[part 12 of 23: package /Cluster]
AUTOSAR XML (schema 4-3-0)
package /Cluster  (continued)
  7 x lin cluster, all with baudrate=19200, protocol-name=LIN, protocol-version=2.0:  (continued)
    Klima_LIN4
      lin physical channel CHNL: comm-connectors=CN_Klima_LIN4
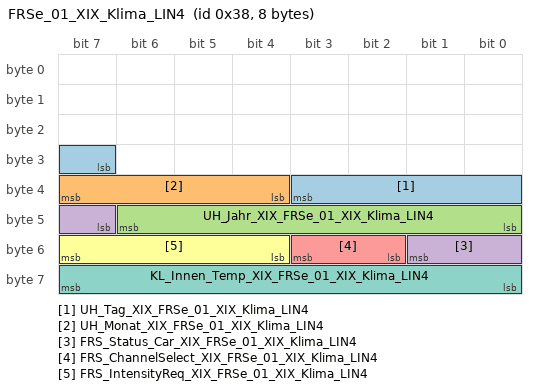
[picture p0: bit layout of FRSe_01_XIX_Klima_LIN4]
        frame FRSe_01_XIX_Klima_LIN4: id 0x38, from Klima, frame-length=8, lin-checksum=ENHANCED
          pdu FRSe_01_XIX_Klima_LIN4: length=8, unused-bit-pattern=0
            signal UH_Tag_XIX_FRSe_01_XIX_Klima_LIN4: start 31, 5 bit, little-endian, data-type-policy=OVERRIDE, i-signal-type=PRIMITIVE, init-value=0, base-type=BT_UH_Tag, compu {0=Cx0_Init (CM_UH_Tag_Cx0_Init), phys=raw for raw 1..31; unit Unit_Day}, range phys 1..31 Unit_Day, raw 0..31, unit=Unit_Day, transfer-property=PENDING  # 0x0: reserviert bei VW
            signal UH_Monat_XIX_FRSe_01_XIX_Klima_LIN4: start 36, 4 bit, little-endian, data-type-policy=OVERRIDE, i-signal-type=PRIMITIVE, init-value=0, base-type=BT_UH_Monat, invalid-value=Invalid_UH_Monat_XIX_FRSe_01_XIX_Klima_LIN4:15, compu {0=Cx0_Init (CM_UH_Monat_Cx0_Init), phys=raw for raw 1..12, 14=Cxe_Relatives_Datum (CM_UH_Monat_Cxe_Relatives_Datum), 15=Cxf_Fehler (CM_UH_Monat_Cxf_Fehler); unit Unit_Month}, range phys 1..12 Unit_Month, raw 0..15, unit=Unit_Month, transfer-property=PENDING  # 0x0D, 0xF = Werte ungültig 0x0E = Relatives Datum (nur VW)
            signal UH_Jahr_XIX_FRSe_01_XIX_Klima_LIN4: start 40, 7 bit, little-endian, data-type-policy=OVERRIDE, i-signal-type=PRIMITIVE, init-value=0, base-type=BT_UH_Jahr, compu {phys=raw+2000 for raw 0..127; unit Unit_Year}, range phys 2000..2127 Unit_Year, raw 0..127, unit=Unit_Year, transfer-property=PENDING
            signal FRS_Status_Car_XIX_FRSe_01_XIX_Klima_LIN4: start 47, 3 bit, little-endian, data-type-policy=OVERRIDE, i-signal-type=PRIMITIVE, init-value=0, base-type=BT_FRS_Status_Car, compu {0=Cx0_Kl15_off (CM_FRS_Status_Car_Cx0_Kl15_off), 1=Cx1_VoKo_active (CM_FRS_Status_Car_Cx1_VoKo_active), 2=Cx2_Kl15_on (CM_FRS_Status_Car_Cx2_Kl15_on)}, range raw 0..2, transfer-property=PENDING  # Status (Kl.15, VoKo)
            signal FRS_ChannelSelect_XIX_FRSe_01_XIX_Klima_LIN4: start 50, 2 bit, little-endian, data-type-policy=OVERRIDE, i-signal-type=PRIMITIVE, init-value=0, base-type=BT_FRS_ChannelSelect, compu {0=Cx0_Init (CM_FRS_ChannelSelect_Cx0_Init), 1=Cx1_container_1 (CM_FRS_ChannelSelect_Cx1_container_1), 2=Cx2_container_2 (CM_FRS_ChannelSelect_Cx2_container_2), 3=Cx3_container_3 (CM_FRS_ChannelSelect_Cx3_container_3)}, range raw 0..3, transfer-property=PENDING  # Fragrance channel select
            signal FRS_IntensityReq_XIX_FRSe_01_XIX_Klima_LIN4: start 52, 4 bit, little-endian, data-type-policy=OVERRIDE, i-signal-type=PRIMITIVE, init-value=14, base-type=BT_FRS_IntensityReq, invalid-value=Invalid_FRS_IntensityReq_XIX_FRSe_01_XIX_Klima_LIN4:15, compu {phys=raw*10 for raw 0..10, 14=Cxe_Init (CM_FRS_IntensityReq_Cxe_Init), 15=Cxf_Fehler (CM_FRS_IntensityReq_Cxf_Fehler); unit Unit_PerCent}, range phys 0..100 Unit_PerCent, raw 0..15, unit=Unit_PerCent, transfer-property=PENDING  # Fragrance Intensity Request (0=off, 10=max)
            signal KL_Innen_Temp_XIX_FRSe_01_XIX_Klima_LIN4: start 56, 8 bit, little-endian, data-type-policy=OVERRIDE, i-signal-type=PRIMITIVE, init-value=254, base-type=BT_KL_Innen_Temp, invalid-value=Invalid_KL_Innen_Temp_XIX_FRSe_01_XIX_Klima_LIN4:255, compu {phys=raw*0.5-50 for raw 0..252, 253=Cxfd_nicht_verbaut (CM_KL_Innen_Temp_Cxfd_nicht_verbaut), 254=Cxfe_nicht_verfuegbar (CM_KL_Innen_Temp_Cxfe_nicht_verfuegbar), 255=Cxff_Fehler (CM_KL_Innen_Temp_Cxff_Fehler); unit Unit_DegreCelsi}, range phys -50..76 Unit_DegreCelsi, raw 0..255, unit=Unit_DegreCelsi, transfer-property=PENDING  # Innentemperatur
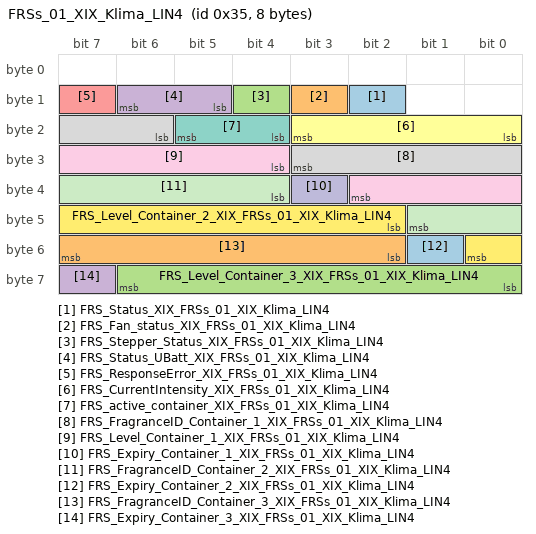
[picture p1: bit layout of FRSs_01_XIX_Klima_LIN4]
        frame FRSs_01_XIX_Klima_LIN4: id 0x35, to Klima, frame-length=8, lin-checksum=ENHANCED
          pdu FRSs_01_XIX_Klima_LIN4: length=8, unused-bit-pattern=0
            signal FRS_Status_XIX_FRSs_01_XIX_Klima_LIN4: start 10, 1 bit, little-endian, data-type-policy=OVERRIDE, i-signal-type=PRIMITIVE, init-value=0, base-type=BT_FRS_Status, compu {0=Cx0_no_error (CM_FRS_Status_Cx0_no_error), 1=Cx1_error (CM_FRS_Status_Cx1_error)}, range raw 0..1, transfer-property=PENDING, to Klima(timeout 3.5 s)  # internal error of fragrance system
            signal FRS_Fan_status_XIX_FRSs_01_XIX_Klima_LIN4: start 11, 1 bit, little-endian, data-type-policy=OVERRIDE, i-signal-type=PRIMITIVE, init-value=0, base-type=BT_FRS_Fan_status, compu {0=Cx0_no_error (CM_FRS_Fan_status_Cx0_no_error), 1=Cx1_error (CM_FRS_Fan_status_Cx1_error)}, range raw 0..1, transfer-property=PENDING, to Klima(timeout 3.5 s)  # Status of fragrance fan
            signal FRS_Stepper_Status_XIX_FRSs_01_XIX_Klima_LIN4: start 12, 1 bit, little-endian, data-type-policy=OVERRIDE, i-signal-type=PRIMITIVE, init-value=0, base-type=BT_FRS_Stepper_Status, compu {0=Cx0_no_error (CM_FRS_Stepper_Status_Cx0_no_error), 1=Cx1_error (CM_FRS_Stepper_Status_Cx1_error)}, range raw 0..1, transfer-property=PENDING, to Klima(timeout 3.5 s)  # Status of fragrance Stepper
            signal FRS_Status_UBatt_XIX_FRSs_01_XIX_Klima_LIN4: start 13, 2 bit, little-endian, data-type-policy=OVERRIDE, i-signal-type=PRIMITIVE, init-value=3, base-type=BT_FRS_Status_UBatt, compu {0=Cx0_voltage_OK (CM_FRS_Status_UBatt_Cx0_voltage_OK), 1=Cx1_undervoltage (CM_FRS_Status_UBatt_Cx1_undervoltage), 2=Cx2_overvoltage (CM_FRS_Status_UBatt_Cx2_overvoltage), 3=Cx3_init (CM_FRS_Status_UBatt_Cx3_init)}, range raw 0..3, transfer-property=PENDING, to Klima(timeout 3.5 s)  # Power supply status
            signal FRS_ResponseError_XIX_FRSs_01_XIX_Klima_LIN4: start 15, 1 bit, little-endian, data-type-policy=OVERRIDE, i-signal-type=PRIMITIVE, init-value=0, base-type=BT_FRS_ResponseError, invalid-value=Invalid_FRS_ResponseError_XIX_FRSs_01_XIX_Klima_LIN4:1, compu {0=Cx0_normal (CM_FRS_ResponseError_Cx0_normal), 1=Cx1_Fehler (CM_FRS_ResponseError_Cx1_Fehler)}, range raw 0..1, transfer-property=PENDING, to Klima(timeout 3.5 s)  # siehe LIN2.0-Specification (Darf nicht über ein Fehlergueltigkeitsbit abgesichtert werden!)
            signal FRS_CurrentIntensity_XIX_FRSs_01_XIX_Klima_LIN4: start 16, 4 bit, little-endian, data-type-policy=OVERRIDE, i-signal-type=PRIMITIVE, init-value=14, base-type=BT_FRS_CurrentIntensity, invalid-value=Invalid_FRS_CurrentIntensity_XIX_FRSs_01_XIX_Klima_LIN4:15, compu {phys=raw*10 for raw 0..10, 14=Cxe_Init (CM_FRS_CurrentIntensity_Cxe_Init), 15=Cxf_Fehler (CM_FRS_CurrentIntensity_Cxf_Fehler); unit Unit_PerCent}, range phys 0..100 Unit_PerCent, raw 0..15, unit=Unit_PerCent, transfer-property=PENDING, to Klima(timeout 3.5 s)  # Status of intensitry (0=off, 10=max)
            signal FRS_active_container_XIX_FRSs_01_XIX_Klima_LIN4: start 20, 2 bit, little-endian, data-type-policy=OVERRIDE, i-signal-type=PRIMITIVE, init-value=0, base-type=BT_FRS_active_container, compu {0=Cx0_init_none (CM_FRS_active_container_Cx0_init_none), 1=Cx1_container_1 (CM_FRS_active_container_Cx1_container_1), 2=Cx2_container_2 (CM_FRS_active_container_Cx2_container_2), 3=Cx3_container_3 (CM_FRS_active_container_Cx3_container_3)}, range raw 0..3, transfer-property=PENDING, to Klima(timeout 3.5 s)  # Current active container
            signal FRS_FragranceID_Container_1_XIX_FRSs_01_XIX_Klima_LIN4: start 22, 6 bit, little-endian, data-type-policy=OVERRIDE, i-signal-type=PRIMITIVE, init-value=0, base-type=BT_FRS_FragranceID_Container_1, compu {0=Cx0_not_installed (CM_FRS_FragranceID_Container_1_Cx0_not_installed), phys=raw for raw 1..60, 62=Cx3e_not_identified (CM_FRS_FragranceID_Container_1_Cx3e_not_identified), 63=Cx3f_custom_built (CM_FRS_FragranceID_Container_1_Cx3f_custom_built); unit Unit_None}, range phys 1..60 Unit_None, raw 0..63, unit=Unit_None, transfer-property=PENDING, to Klima(timeout 3.5 s)  # FragranceID in Container_1
            signal FRS_Level_Container_1_XIX_FRSs_01_XIX_Klima_LIN4: start 28, 7 bit, little-endian, data-type-policy=OVERRIDE, i-signal-type=PRIMITIVE, init-value=126, base-type=BT_FRS_Level_Container_1, compu {phys=raw for raw 0..100, 125=Cx7d_not_calculable (CM_FRS_Level_Container_1_Cx7d_not_calculable), 126=Cx7e_init (CM_FRS_Level_Container_1_Cx7e_init), 127=Cx7f_error (CM_FRS_Level_Container_1_Cx7f_error); unit Unit_PerCent}, range phys 0..100 Unit_PerCent, raw 0..127, unit=Unit_PerCent, transfer-property=PENDING, to Klima(timeout 3.5 s)  # Remaining level container 1
            signal FRS_Expiry_Container_1_XIX_FRSs_01_XIX_Klima_LIN4: start 35, 1 bit, little-endian, data-type-policy=OVERRIDE, i-signal-type=PRIMITIVE, init-value=0, base-type=BT_FRS_Expiry_Container_1, compu {0=Cx0_ok (CM_FRS_Expiry_Container_1_Cx0_ok), 1=Cx1_expiry_exceeded (CM_FRS_Expiry_Container_1_Cx1_expiry_exceeded)}, range raw 0..1, transfer-property=PENDING, to Klima(timeout 3.5 s)  # Expiry of Container 1
            signal FRS_FragranceID_Container_2_XIX_FRSs_01_XIX_Klima_LIN4: start 36, 6 bit, little-endian, data-type-policy=OVERRIDE, i-signal-type=PRIMITIVE, init-value=0, base-type=BT_FRS_FragranceID_Container_2, compu {0=Cx0_not_installed (CM_FRS_FragranceID_Container_2_Cx0_not_installed), phys=raw for raw 1..60, 62=Cx3e_not_identified (CM_FRS_FragranceID_Container_2_Cx3e_not_identified), 63=Cx3f_custom_built (CM_FRS_FragranceID_Container_2_Cx3f_custom_built); unit Unit_None}, range phys 1..60 Unit_None, raw 0..63, unit=Unit_None, transfer-property=PENDING, to Klima(timeout 3.5 s)  # FragranceID in Container_2
            signal FRS_Level_Container_2_XIX_FRSs_01_XIX_Klima_LIN4: start 42, 7 bit, little-endian, data-type-policy=OVERRIDE, i-signal-type=PRIMITIVE, init-value=126, base-type=BT_FRS_Level_Container_2, compu {phys=raw for raw 0..100, 125=Cx7d_not_calculable (CM_FRS_Level_Container_2_Cx7d_not_calculable), 126=Cx7e_init (CM_FRS_Level_Container_2_Cx7e_init), 127=Cx7f_error (CM_FRS_Level_Container_2_Cx7f_error); unit Unit_PerCent}, range phys 0..100 Unit_PerCent, raw 0..127, unit=Unit_PerCent, transfer-property=PENDING, to Klima(timeout 3.5 s)  # Remaining level container 2
            signal FRS_Expiry_Container_2_XIX_FRSs_01_XIX_Klima_LIN4: start 49, 1 bit, little-endian, data-type-policy=OVERRIDE, i-signal-type=PRIMITIVE, init-value=0, base-type=BT_FRS_Expiry_Container_2, compu {0=Cx0_ok (CM_FRS_Expiry_Container_2_Cx0_ok), 1=Cx1_expiry_exceeded (CM_FRS_Expiry_Container_2_Cx1_expiry_exceeded)}, range raw 0..1, transfer-property=PENDING, to Klima(timeout 3.5 s)  # Expiry of Container 2
            signal FRS_FragranceID_Container_3_XIX_FRSs_01_XIX_Klima_LIN4: start 50, 6 bit, little-endian, data-type-policy=OVERRIDE, i-signal-type=PRIMITIVE, init-value=0, base-type=BT_FRS_FragranceID_Container_3, compu {0=Cx0_not_installed (CM_FRS_FragranceID_Container_3_Cx0_not_installed), phys=raw for raw 1..60, 62=Cx3e_not_identified (CM_FRS_FragranceID_Container_3_Cx3e_not_identified), 63=Cx3f_custom_built (CM_FRS_FragranceID_Container_3_Cx3f_custom_built); unit Unit_None}, range phys 1..60 Unit_None, raw 0..63, unit=Unit_None, transfer-property=PENDING, to Klima(timeout 3.5 s)  # FragranceID in Container_3
            signal FRS_Level_Container_3_XIX_FRSs_01_XIX_Klima_LIN4: start 56, 7 bit, little-endian, data-type-policy=OVERRIDE, i-signal-type=PRIMITIVE, init-value=126, base-type=BT_FRS_Level_Container_3, compu {phys=raw for raw 0..100, 125=Cx7d_not_calculable (CM_FRS_Level_Container_3_Cx7d_not_calculable), 126=Cx7e_init (CM_FRS_Level_Container_3_Cx7e_init), 127=Cx7f_error (CM_FRS_Level_Container_3_Cx7f_error); unit Unit_PerCent}, range phys 0..100 Unit_PerCent, raw 0..127, unit=Unit_PerCent, transfer-property=PENDING, to Klima(timeout 3.5 s)  # Remaining level container 3
            signal FRS_Expiry_Container_3_XIX_FRSs_01_XIX_Klima_LIN4: start 63, 1 bit, little-endian, data-type-policy=OVERRIDE, i-signal-type=PRIMITIVE, init-value=0, base-type=BT_FRS_Expiry_Container_3, compu {0=Cx0_ok (CM_FRS_Expiry_Container_3_Cx0_ok), 1=Cx1_expiry_exceeded (CM_FRS_Expiry_Container_3_Cx1_expiry_exceeded)}, range raw 0..1, transfer-property=PENDING, to Klima(timeout 3.5 s)  # Expiry of Container 3
        frame HV_Hbe_01_XIX_Klima_LIN4: id 0x1C, from Klima, frame-length=4, lin-checksum=ENHANCED
          pdu HV_Hbe_01_XIX_Klima_LIN4: length=4, unused-bit-pattern=0
            signal KL_HV_Hb_soll_XIX_HV_Hbe_01_XIX_Klima_LIN4: start 0, 8 bit, little-endian, data-type-policy=OVERRIDE, i-signal-type=PRIMITIVE, init-value=254, base-type=BT_KL_HV_Hb_soll, invalid-value=Invalid_KL_HV_Hb_soll_XIX_HV_Hbe_01_XIX_Klima_LIN4:255, compu {phys=raw for raw 0..100, 254=Cxfe_Init (CM_KL_HV_Hb_soll_Cxfe_Init), 255=Cxff_Fehler (CM_KL_HV_Hb_soll_Cxff_Fehler); unit Unit_PerCent}, range phys 0..100 Unit_PerCent, raw 0..255, unit=Unit_PerCent, transfer-property=PENDING  # Calculated maximum HV-PTC Heater Power coming from Motor ECU
            signal KL_HV_Hb_ein_XIX_HV_Hbe_01_XIX_Klima_LIN4: start 8, 1 bit, little-endian, data-type-policy=OVERRIDE, i-signal-type=PRIMITIVE, init-value=0, base-type=BT_KL_HV_Hb_ein, compu {0=Cx0_Aus (CM_KL_HV_Hb_ein_Cx0_Aus), 1=Cx1_Ein (CM_KL_HV_Hb_ein_Cx1_Ein)}, range raw 0..1, transfer-property=PENDING  # PTC Aus/Ein
        frame HV_Hbs_01_XIX_Klima_LIN4: id 0x30, to Klima, frame-length=8, lin-checksum=ENHANCED  # HV-PTC
          pdu HV_Hbs_01_XIX_Klima_LIN4: length=8, unused-bit-pattern=0  # HV-PTC
            signal PTC_HVb_I_ist_XIX_HV_Hbs_01_XIX_Klima_LIN4: start 0, 8 bit, little-endian, data-type-policy=OVERRIDE, i-signal-type=PRIMITIVE, init-value=254, base-type=BT_PTC_HVb_I_ist, invalid-value=Invalid_PTC_HVb_I_ist_XIX_HV_Hbs_01_XIX_Klima_LIN4:255, compu {phys=raw*0.25 for raw 0..253, 254=Cxfe_Init (CM_PTC_HVb_I_ist_Cxfe_Init), 255=Cxff_Fehler (CM_PTC_HVb_I_ist_Cxff_Fehler); unit Unit_Amper}, range phys 0..63.25 Unit_Amper, raw 0..255, unit=Unit_Amper, transfer-property=PENDING, to Klima(timeout 3.5 s)  # PTC Stromverbrauch (max. 63,25A)
            signal PTC_HVb_ERR_XIX_HV_Hbs_01_XIX_Klima_LIN4: start 8, 2 bit, little-endian, data-type-policy=OVERRIDE, i-signal-type=PRIMITIVE, init-value=3, base-type=BT_PTC_HVb_ERR, compu {0=Cx0_No_Error (CM_PTC_HVb_ERR_Cx0_No_Error), 1=Cx1_High_Voltage_too_low (CM_PTC_HVb_ERR_Cx1_High_Voltage_too_low), 2=Cx2_High_Voltage_too_high (CM_PTC_HVb_ERR_Cx2_High_Voltage_too_high), 3=Cx3_Init (CM_PTC_HVb_ERR_Cx3_Init)}, range raw 0..3, transfer-property=PENDING, to Klima(timeout 3.5 s)
            signal PTC_HVb_Status_PTC_XIX_HV_Hbs_01_XIX_Klima_LIN4: start 16, 3 bit, little-endian, data-type-policy=OVERRIDE, i-signal-type=PRIMITIVE, init-value=7, base-type=BT_PTC_HVb_Status_PTC, compu {0=Cx0_PTC_OK (CM_PTC_HVb_Status_PTC_Cx0_PTC_OK), 1=Cx1_PTC_defekt (CM_PTC_HVb_Status_PTC_Cx1_PTC_defekt), 2=Cx2_PTC_error (CM_PTC_HVb_Status_PTC_Cx2_PTC_error), 3=Cx3_PTC_degraded_by_HW (CM_PTC_HVb_Status_PTC_Cx3_PTC_degraded_by_HW), 4=Cx4_PTC_degraded_by_SW (CM_PTC_HVb_Status_PTC_Cx4_PTC_degraded_by_SW), 5=Cx5_PTC_overheat_protection (CM_PTC_HVb_Status_PTC_Cx5_PTC_overheat_protection), 6=Cx6_not_defined (CM_PTC_HVb_Status_PTC_Cx6_not_defined), 7=Cx7_Init (CM_PTC_HVb_Status_PTC_Cx7_Init)}, range raw 0..7, transfer-property=PENDING, to Klima(timeout 3.5 s)  # Status der HV-PTC Heizeinheit
            signal PTC_HVb_Status_UBatt_XIX_HV_Hbs_01_XIX_Klima_LIN4: start 19, 2 bit, little-endian, data-type-policy=OVERRIDE, i-signal-type=PRIMITIVE, init-value=3, base-type=BT_PTC_HVb_Status_UBatt, compu {0=Cx0_Batterie_OK (CM_PTC_HVb_Status_UBatt_Cx0_Batterie_OK), 1=Cx1_Unterspannung (CM_PTC_HVb_Status_UBatt_Cx1_Unterspannung), 2=Cx2_Ueberspannung (CM_PTC_HVb_Status_UBatt_Cx2_Ueberspannung), 3=Cx3_Init (CM_PTC_HVb_Status_UBatt_Cx3_Init)}, range raw 0..3, transfer-property=PENDING, to Klima(timeout 3.5 s)  # Status der Batteriespannung
            signal PTC_HVb_ResponseError_XIX_HV_Hbs_01_XIX_Klima_LIN4: start 21, 1 bit, little-endian, data-type-policy=OVERRIDE, i-signal-type=PRIMITIVE, init-value=0, base-type=BT_PTC_HVb_ResponseError, invalid-value=Invalid_PTC_HVb_ResponseError_XIX_HV_Hbs_01_XIX_Klima_LIN4:1, compu {0=Cx0_normal (CM_PTC_HVb_ResponseError_Cx0_normal), 1=Cx1_Fehler (CM_PTC_HVb_ResponseError_Cx1_Fehler)}, range raw 0..1, transfer-property=PENDING, to Klima(timeout 3.5 s)  # siehe LIN2.0-Specification (Darf nicht über ein Fehlergueltigkeitsbit abgesichtert werden!)
            signal PTC_HVb_TimeOut_Fehler_XIX_HV_Hbs_01_XIX_Klima_LIN4: start 22, 1 bit, little-endian, data-type-policy=OVERRIDE, i-signal-type=PRIMITIVE, init-value=0, base-type=BT_PTC_HVb_TimeOut_Fehler, compu {0=Cx0_no_timeout (CM_PTC_HVb_TimeOut_Fehler_Cx0_no_timeout), 1=Cx1_timeout_detected (CM_PTC_HVb_TimeOut_Fehler_Cx1_timeout_detected)}, range raw 0..1, transfer-property=PENDING, to Klima(timeout 3.5 s)  # TPC hat zu lange keine Empfangsframes mehr erhalten (Dieser Fehler muss nicht über einen Fehlergueltigkeitsbit abgesichert werden).
            signal PTC_HVb_Err_Heizkreis_1_XIX_HV_Hbs_01_XIX_Klima_LIN4: start 24, 1 bit, little-endian, data-type-policy=OVERRIDE, i-signal-type=PRIMITIVE, init-value=0, base-type=BT_PTC_HVb_Err_Heizkreis_1, invalid-value=Invalid_PTC_HVb_Err_Heizkreis_1_XIX_HV_Hbs_01_XIX_Klima_LIN4:1, compu {0=Cx0_normal (CM_PTC_HVb_Err_Heizkreis_1_Cx0_normal), 1=Cx1_Fehler (CM_PTC_HVb_Err_Heizkreis_1_Cx1_Fehler)}, range raw 0..1, transfer-property=PENDING, to Klima(timeout 3.5 s)  # Bit wird gesetzt wenn Fehler in Heizkreis 1
            signal PTC_HVb_Err_Heizkreis_2_XIX_HV_Hbs_01_XIX_Klima_LIN4: start 25, 1 bit, little-endian, data-type-policy=OVERRIDE, i-signal-type=PRIMITIVE, init-value=0, base-type=BT_PTC_HVb_Err_Heizkreis_2, invalid-value=Invalid_PTC_HVb_Err_Heizkreis_2_XIX_HV_Hbs_01_XIX_Klima_LIN4:1, compu {0=Cx0_normal (CM_PTC_HVb_Err_Heizkreis_2_Cx0_normal), 1=Cx1_Fehler (CM_PTC_HVb_Err_Heizkreis_2_Cx1_Fehler)}, range raw 0..1, transfer-property=PENDING, to Klima(timeout 3.5 s)  # Bit wird gesetzt wenn Fehler in Heizkreis 2
            signal PTC_HVb_Err_Heizkreis_3_XIX_HV_Hbs_01_XIX_Klima_LIN4: start 26, 1 bit, little-endian, data-type-policy=OVERRIDE, i-signal-type=PRIMITIVE, init-value=0, base-type=BT_PTC_HVb_Err_Heizkreis_3, invalid-value=Invalid_PTC_HVb_Err_Heizkreis_3_XIX_HV_Hbs_01_XIX_Klima_LIN4:1, compu {0=Cx0_normal (CM_PTC_HVb_Err_Heizkreis_3_Cx0_normal), 1=Cx1_Fehler (CM_PTC_HVb_Err_Heizkreis_3_Cx1_Fehler)}, range raw 0..1, transfer-property=PENDING, to Klima(timeout 3.5 s)  # Bit wird gesetzt wenn Fehler in Heizkreis 3
            signal PTC_HVb_Err_Leckagestrom_XIX_HV_Hbs_01_XIX_Klima_LIN4: start 27, 1 bit, little-endian, data-type-policy=OVERRIDE, i-signal-type=PRIMITIVE, init-value=0, base-type=BT_PTC_HVb_Err_Leckagestrom, invalid-value=Invalid_PTC_HVb_Err_Leckagestrom_XIX_HV_Hbs_01_XIX_Klima_LIN4:1, compu {0=Cx0_normal (CM_PTC_HVb_Err_Leckagestrom_Cx0_normal), 1=Cx1_Fehler (CM_PTC_HVb_Err_Leckagestrom_Cx1_Fehler)}, range raw 0..1, transfer-property=PENDING, to Klima(timeout 3.5 s)  # Bit wird gesetzt, wenn Strom fließt obwohl kein Heizkreis angesteuert wird ( IGBT Fehler)
            signal PTC_HVb_Err_Ueberstromabschaltung_XIX_HV_Hbs_01_XIX_Klima_LIN4: start 28, 1 bit, little-endian, data-type-policy=OVERRIDE, i-signal-type=PRIMITIVE, init-value=0, base-type=BT_PTC_HVb_Err_Ueberstromabschaltung, compu {0=Cx0_inaktiv (CM_PTC_HVb_Err_Ueberstromabschaltung_Cx0_inaktiv), 1=Cx1_aktiv (CM_PTC_HVb_Err_Ueberstromabschaltung_Cx1_aktiv)}, range raw 0..1, transfer-property=PENDING, to Klima(timeout 3.5 s)  # Bit wird gesetzt, wenn über längeren Zeitraum ein zu hoher Gesamtstrom fließt (I Heizkreise > definierte Gesamtstromaufnahme)
            signal PTC_HVb_Err_Temperaturschutz_XIX_HV_Hbs_01_XIX_Klima_LIN4: start 29, 1 bit, little-endian, data-type-policy=OVERRIDE, i-signal-type=PRIMITIVE, init-value=0, base-type=BT_PTC_HVb_Err_Temperaturschutz, compu {0=Cx0_inaktiv (CM_PTC_HVb_Err_Temperaturschutz_Cx0_inaktiv), 1=Cx1_aktiv (CM_PTC_HVb_Err_Temperaturschutz_Cx1_aktiv)}, range raw 0..1, transfer-property=PENDING, to Klima(timeout 3.5 s)  # Bit wird gesetzt wenn die PlatinenTemperatur ihren Abschaltwert erreicht, Rücknahme bei erreichen der Einschalttemperaturschwelle
            signal PTC_HVb_Err_intern_XIX_HV_Hbs_01_XIX_Klima_LIN4: start 30, 1 bit, little-endian, data-type-policy=OVERRIDE, i-signal-type=PRIMITIVE, init-value=0, base-type=BT_PTC_HVb_Err_intern, invalid-value=Invalid_PTC_HVb_Err_intern_XIX_HV_Hbs_01_XIX_Klima_LIN4:1, compu {0=Cx0_normal (CM_PTC_HVb_Err_intern_Cx0_normal), 1=Cx1_Fehler (CM_PTC_HVb_Err_intern_Cx1_Fehler)}, range raw 0..1, transfer-property=PENDING, to Klima(timeout 3.5 s)  # Bit soll gesetzt werden, bei allen anderen internen Fehlern, welche denkbar sind (z.B. CPU- oder EEPROM Error; AD_Wandler defekt etc.)
            signal PTC_HVb_UBatt_XIX_HV_Hbs_01_XIX_Klima_LIN4: start 32, 8 bit, little-endian, data-type-policy=OVERRIDE, i-signal-type=PRIMITIVE, init-value=254, base-type=BT_PTC_HVb_UBatt, invalid-value=Invalid_PTC_HVb_UBatt_XIX_HV_Hbs_01_XIX_Klima_LIN4:255, compu {phys=raw*0.1 for raw 0..253, 254=Cxfe_Init (CM_PTC_HVb_UBatt_Cxfe_Init), 255=Cxff_Fehler (CM_PTC_HVb_UBatt_Cxff_Fehler); unit Unit_Volt}, range phys 0..25.3 Unit_Volt, raw 0..255, unit=Unit_Volt, transfer-property=PENDING, to Klima(timeout 3.5 s)  # Gemessene Batteriespannung
            signal PTC_HVb_Temp_PCB_XIX_HV_Hbs_01_XIX_Klima_LIN4: start 40, 8 bit, little-endian, data-type-policy=OVERRIDE, i-signal-type=PRIMITIVE, init-value=254, base-type=BT_PTC_HVb_Temp_PCB, invalid-value=Invalid_PTC_HVb_Temp_PCB_XIX_HV_Hbs_01_XIX_Klima_LIN4:255, compu {phys=raw-50 for raw 0..200, 254=Cxfe_Init (CM_PTC_HVb_Temp_PCB_Cxfe_Init), 255=Cxff_Fehler (CM_PTC_HVb_Temp_PCB_Cxff_Fehler); unit Unit_DegreCelsi}, range phys -50..150 Unit_DegreCelsi, raw 0..255, unit=Unit_DegreCelsi, transfer-property=PENDING, to Klima(timeout 3.5 s)  # Temperatur der PTC Ekektronik und der Platine (PCB)
            signal PTC_HVb_Heizmedium_Sensor_1_XIX_HV_Hbs_01_XIX_Klima_LIN4: start 48, 8 bit, little-endian, data-type-policy=OVERRIDE, i-signal-type=PRIMITIVE, init-value=254, base-type=BT_PTC_HVb_Heizmedium_Sensor_1, invalid-value=Invalid_PTC_HVb_Heizmedium_Sensor_1_XIX_HV_Hbs_01_XIX_Klima_LIN4:255, compu {phys=raw-50 for raw 0..220, 254=Cxfe_Init (CM_PTC_HVb_Heizmedium_Sensor_1_Cxfe_Init), 255=Cxff_Fehler (CM_PTC_HVb_Heizmedium_Sensor_1_Cxff_Fehler); unit Unit_DegreCelsi}, range phys -50..170 Unit_DegreCelsi, raw 0..255, unit=Unit_DegreCelsi, transfer-property=PENDING, to Klima(timeout 3.5 s)  # Gemessene Wassereinlasstemperatur
            signal PTC_HVb_Heizmedium_Sensor_2_XIX_HV_Hbs_01_XIX_Klima_LIN4: start 56, 8 bit, little-endian, data-type-policy=OVERRIDE, i-signal-type=PRIMITIVE, init-value=254, base-type=BT_PTC_HVb_Heizmedium_Sensor_2, invalid-value=Invalid_PTC_HVb_Heizmedium_Sensor_2_XIX_HV_Hbs_01_XIX_Klima_LIN4:255, compu {phys=raw-50 for raw 0..220, 254=Cxfe_Init (CM_PTC_HVb_Heizmedium_Sensor_2_Cxfe_Init), 255=Cxff_Fehler (CM_PTC_HVb_Heizmedium_Sensor_2_Cxff_Fehler); unit Unit_DegreCelsi}, range phys -50..170 Unit_DegreCelsi, raw 0..255, unit=Unit_DegreCelsi, transfer-property=PENDING, to Klima(timeout 3.5 s)  # Gemessene Wasserauslasstemperatur
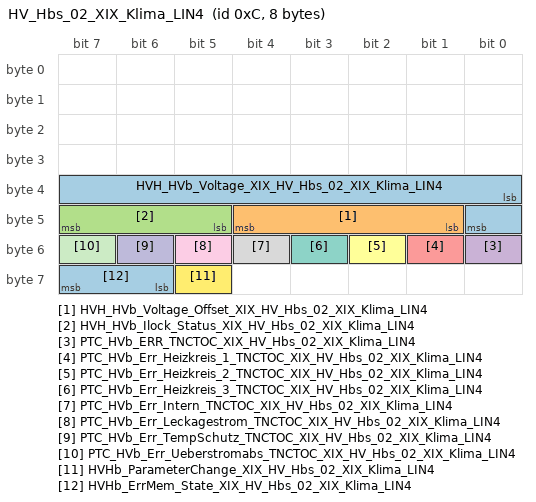
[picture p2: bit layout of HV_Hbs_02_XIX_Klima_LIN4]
        frame HV_Hbs_02_XIX_Klima_LIN4: id 0xC, to Klima, frame-length=8, lin-checksum=ENHANCED
          pdu HV_Hbs_02_XIX_Klima_LIN4: length=8, unused-bit-pattern=0
            signal HVH_HVb_Voltage_XIX_HV_Hbs_02_XIX_Klima_LIN4: start 32, 9 bit, little-endian, data-type-policy=OVERRIDE, i-signal-type=PRIMITIVE, init-value=510, base-type=BT_HVH_HVb_Voltage, invalid-value=Invalid_HVH_HVb_Voltage_XIX_HV_Hbs_02_XIX_Klima_LIN4:511, compu {phys=raw*4 for raw 0..509, 510=Cx1fe_Init (CM_HVH_HVb_Voltage_Cx1fe_Init), 511=Cx1ff_Fehler (CM_HVH_HVb_Voltage_Cx1ff_Fehler); unit Unit_Volt}, range phys 0..2036 Unit_Volt, raw 0..511, unit=Unit_Volt, transfer-property=PENDING, to Klima(timeout 3.5 s)  # Actual meassured High Voltage level of the HVH
            signal HVH_HVb_Voltage_Offset_XIX_HV_Hbs_02_XIX_Klima_LIN4: start 41, 4 bit, little-endian, data-type-policy=OVERRIDE, i-signal-type=PRIMITIVE, init-value=14, base-type=BT_HVH_HVb_Voltage_Offset, invalid-value=Invalid_HVH_HVb_Voltage_Offset_XIX_HV_Hbs_02_XIX_Klima_LIN4:15, compu {phys=raw*0.5 for raw 0..8, 14=Cxe_Init (CM_HVH_HVb_Voltage_Offset_Cxe_Init), 15=Cxf_Fehler (CM_HVH_HVb_Voltage_Offset_Cxf_Fehler); unit Unit_Volt}, range phys 0..4 Unit_Volt, raw 0..15, unit=Unit_Volt, transfer-property=PENDING, to Klima(timeout 3.5 s)  # Feinauflösung der HV-Spannung des HV-Heizers
            signal HVH_HVb_Ilock_Status_XIX_HV_Hbs_02_XIX_Klima_LIN4: start 45, 3 bit, little-endian, data-type-policy=OVERRIDE, i-signal-type=PRIMITIVE, init-value=7, base-type=BT_HVH_HVb_Ilock_Status, invalid-value=Invalid_HVH_HVb_Ilock_Status_XIX_HV_Hbs_02_XIX_Klima_LIN4:2, compu {0=Cx0_Connected (CM_HVH_HVb_Ilock_Status_Cx0_Connected), 1=Cx1_Disconnected (CM_HVH_HVb_Ilock_Status_Cx1_Disconnected), 2=Cx2_Fehler (CM_HVH_HVb_Ilock_Status_Cx2_Fehler), 3=Cx3_unused (CM_HVH_HVb_Ilock_Status_Cx3_unused), 4=Cx4_unused (CM_HVH_HVb_Ilock_Status_Cx4_unused), 5=Cx5_unused (CM_HVH_HVb_Ilock_Status_Cx5_unused), 6=Cx6_unused (CM_HVH_HVb_Ilock_Status_Cx6_unused), 7=Cx7_Init (CM_HVH_HVb_Ilock_Status_Cx7_Init)}, range raw 0..7, transfer-property=PENDING, to Klima(timeout 3.5 s)  # Status HV-Interlock
            signal PTC_HVb_ERR_TNCTOC_XIX_HV_Hbs_02_XIX_Klima_LIN4: start 48, 1 bit, little-endian, data-type-policy=OVERRIDE, i-signal-type=PRIMITIVE, init-value=1, base-type=BT_PTC_HVb_ERR_TNCTOC, compu {0=Cx0_testcompletedthisoperationcycle (CM_PTC_HVb_ERR_TNCTOC_Cx0_testcompletedthisoperationcycle), 1=Cx1_testnotcompleted (CM_PTC_HVb_ERR_TNCTOC_Cx1_testnotcompleted)}, range raw 0..1, transfer-property=PENDING, to Klima(timeout 3.5 s)  # Vorhalt OBD-Signal zu PTC_HV_ERR
            signal PTC_HVb_Err_Heizkreis_1_TNCTOC_XIX_HV_Hbs_02_XIX_Klima_LIN4: start 49, 1 bit, little-endian, data-type-policy=OVERRIDE, i-signal-type=PRIMITIVE, init-value=1, base-type=BT_PTC_HVb_Err_Heizkreis_1_TNCTOC, compu {0=Cx0_TestDurchlaufen (CM_PTC_HVb_Err_Heizkreis_1_TNCTOC_Cx0_TestDurchlaufen), 1=Cx1_TestNichtDurchlaufen (CM_PTC_HVb_Err_Heizkreis_1_TNCTOC_Cx1_TestNichtDurchlaufen)}, range raw 0..1, transfer-property=PENDING, to Klima(timeout 3.5 s)  # TNCTOC: test not completed this operation cycle
            signal PTC_HVb_Err_Heizkreis_2_TNCTOC_XIX_HV_Hbs_02_XIX_Klima_LIN4: start 50, 1 bit, little-endian, data-type-policy=OVERRIDE, i-signal-type=PRIMITIVE, init-value=1, base-type=BT_PTC_HVb_Err_Heizkreis_2_TNCTOC, compu {0=Cx0_TestDurchlaufen (CM_PTC_HVb_Err_Heizkreis_2_TNCTOC_Cx0_TestDurchlaufen), 1=Cx1_TestNichtDurchlaufen (CM_PTC_HVb_Err_Heizkreis_2_TNCTOC_Cx1_TestNichtDurchlaufen)}, range raw 0..1, transfer-property=PENDING, to Klima(timeout 3.5 s)  # TNCTOC: test not completed this operation cycle
            signal PTC_HVb_Err_Heizkreis_3_TNCTOC_XIX_HV_Hbs_02_XIX_Klima_LIN4: start 51, 1 bit, little-endian, data-type-policy=OVERRIDE, i-signal-type=PRIMITIVE, init-value=1, base-type=BT_PTC_HVb_Err_Heizkreis_3_TNCTOC, compu {0=Cx0_TestDurchlaufen (CM_PTC_HVb_Err_Heizkreis_3_TNCTOC_Cx0_TestDurchlaufen), 1=Cx1_TestNichtDurchlaufen (CM_PTC_HVb_Err_Heizkreis_3_TNCTOC_Cx1_TestNichtDurchlaufen)}, range raw 0..1, transfer-property=PENDING, to Klima(timeout 3.5 s)  # TNCTOC: test not completed this operation cycle
            signal PTC_HVb_Err_Intern_TNCTOC_XIX_HV_Hbs_02_XIX_Klima_LIN4: start 52, 1 bit, little-endian, data-type-policy=OVERRIDE, i-signal-type=PRIMITIVE, init-value=1, base-type=BT_PTC_HVb_Err_Intern_TNCTOC, compu {0=Cx0_TestDurchlaufen (CM_PTC_HVb_Err_Intern_TNCTOC_Cx0_TestDurchlaufen), 1=Cx1_TestNichtDurchlaufen (CM_PTC_HVb_Err_Intern_TNCTOC_Cx1_TestNichtDurchlaufen)}, range raw 0..1, transfer-property=PENDING, to Klima(timeout 3.5 s)  # TNCTOC: test not completed this operation cycle
            signal PTC_HVb_Err_Leckagestrom_TNCTOC_XIX_HV_Hbs_02_XIX_Klima_LIN4: start 53, 1 bit, little-endian, data-type-policy=OVERRIDE, i-signal-type=PRIMITIVE, init-value=1, base-type=BT_PTC_HVb_Err_Leckagestrom_TNCTOC, compu {0=Cx0_TestDurchlaufen (CM_PTC_HVb_Err_Leckagestrom_TNCTOC_Cx0_TestDurchlaufen), 1=Cx1_TestNichtDurchlaufen (CM_PTC_HVb_Err_Leckagestrom_TNCTOC_Cx1_TestNichtDurchlaufen)}, range raw 0..1, transfer-property=PENDING, to Klima(timeout 3.5 s)  # TNCTOC: test not completed this operation cycle
            signal PTC_HVb_Err_TempSchutz_TNCTOC_XIX_HV_Hbs_02_XIX_Klima_LIN4: start 54, 1 bit, little-endian, data-type-policy=OVERRIDE, i-signal-type=PRIMITIVE, init-value=1, base-type=BT_PTC_HVb_Err_TempSchutz_TNCTOC, compu {0=Cx0_TestDurchlaufen (CM_PTC_HVb_Err_TempSchutz_TNCTOC_Cx0_TestDurchlaufen), 1=Cx1_TestNichtDurchlaufen (CM_PTC_HVb_Err_TempSchutz_TNCTOC_Cx1_TestNichtDurchlaufen)}, range raw 0..1, transfer-property=PENDING, to Klima(timeout 3.5 s)  # TNCTOC: test not completed this operation cycle
            signal PTC_HVb_Err_Ueberstromabs_TNCTOC_XIX_HV_Hbs_02_XIX_Klima_LIN4: start 55, 1 bit, little-endian, data-type-policy=OVERRIDE, i-signal-type=PRIMITIVE, init-value=1, base-type=BT_PTC_HVb_Err_Ueberstromabs_TNCTOC, compu {0=Cx0_TestDurchlaufen (CM_PTC_HVb_Err_Ueberstromabs_TNCTOC_Cx0_TestDurchlaufen), 1=Cx1_TestNichtDurchlaufen (CM_PTC_HVb_Err_Ueberstromabs_TNCTOC_Cx1_TestNichtDurchlaufen)}, range raw 0..1, transfer-property=PENDING, to Klima(timeout 3.5 s)  # TNCTOC: test not completed this operation cycle
            signal HVHb_ParameterChange_XIX_HV_Hbs_02_XIX_Klima_LIN4: start 61, 1 bit, little-endian, data-type-policy=OVERRIDE, i-signal-type=PRIMITIVE, init-value=0, base-type=BT_HVHb_ParameterChange, compu {0=Cx0_noParameterChange (CM_HVHb_ParameterChange_Cx0_noParameterChange), 1=Cx1_ParameterChange (CM_HVHb_ParameterChange_Cx1_ParameterChange)}, range raw 0..1, transfer-property=PENDING, to Klima(timeout 3.5 s)  # Im LIN Slave wurde ein Parameter geändert, der eine Neuberechnung der CALID/CVN nach sich zieht. Das Bit wird auf '0' gesetzt, wenn seitens des DK4 eine Abfrage der CALID/CVN angestoßen und das DK1/2-System diese vollständig versendet hat.
            signal HVHb_ErrMem_State_XIX_HV_Hbs_02_XIX_Klima_LIN4: start 62, 2 bit, little-endian, data-type-policy=OVERRIDE, i-signal-type=PRIMITIVE, init-value=0, base-type=BT_HVHb_ErrMem_State, compu {0=Cx0_Init (CM_HVHb_ErrMem_State_Cx0_Init), 1=Cx1_Normalbetrieb (CM_HVHb_ErrMem_State_Cx1_Normalbetrieb), 2=Cx2_WertNachEmpfangMode04Request (CM_HVHb_ErrMem_State_Cx2_WertNachEmpfangMode04Request), 3=Cx3_WertNachInitialisierung (CM_HVHb_ErrMem_State_Cx3_WertNachInitialisierung)}, range raw 0..3, transfer-property=PENDING, to Klima(timeout 3.5 s)  # ErrMem_Init_done: Wird nach erfolgreichem löschen im LIN Slave für die Teit t_InitDone gesetzt und bedeutet, dass initialisiert wurde und ErrMem wieder aktiv ist. Nach Zeit t_InitDone wird der Wert 'ErrMem_Active_State' zurückgesetzt.
        frame KLhe_01_XIX_Klima_LIN4: id 0x1, from Klima, frame-length=8, lin-checksum=ENHANCED
          pdu KLhe_01_XIX_Klima_LIN4: length=8, unused-bit-pattern=0
            signal KL_Anz_oben_hl_XIX_KLhe_01_XIX_Klima_LIN4: start 0, 1 bit, little-endian, data-type-policy=OVERRIDE, i-signal-type=PRIMITIVE, init-value=0, base-type=BT_KL_Anz_oben_hl, compu {0=Cx0_Aus (CM_KL_Anz_oben_hl_Cx0_Aus), 1=Cx1_Ein (CM_KL_Anz_oben_hl_Cx1_Ein)}, range raw 0..1, transfer-property=PENDING  # VW428
            signal KL_Anz_mitte_hl_XIX_KLhe_01_XIX_Klima_LIN4: start 1, 1 bit, little-endian, data-type-policy=OVERRIDE, i-signal-type=PRIMITIVE, init-value=0, base-type=BT_KL_Anz_mitte_hl, compu {0=Cx0_Aus (CM_KL_Anz_mitte_hl_Cx0_Aus), 1=Cx1_Ein (CM_KL_Anz_mitte_hl_Cx1_Ein)}, range raw 0..1, transfer-property=PENDING  # Rückmeldung "Luftverteilung Mannanströmer Heck"
            signal KL_Anz_unten_hl_XIX_KLhe_01_XIX_Klima_LIN4: start 2, 1 bit, little-endian, data-type-policy=OVERRIDE, i-signal-type=PRIMITIVE, init-value=0, base-type=BT_KL_Anz_unten_hl, compu {0=Cx0_Aus (CM_KL_Anz_unten_hl_Cx0_Aus), 1=Cx1_Ein (CM_KL_Anz_unten_hl_Cx1_Ein)}, range raw 0..1, transfer-property=PENDING  # Rückmeldung "Luftverteilung Fußraum Heck"
            signal KL_Anz_auto_hl_XIX_KLhe_01_XIX_Klima_LIN4: start 3, 1 bit, little-endian, data-type-policy=OVERRIDE, i-signal-type=PRIMITIVE, init-value=0, base-type=BT_KL_Anz_auto_hl, compu {0=Cx0_Aus (CM_KL_Anz_auto_hl_Cx0_Aus), 1=Cx1_Ein (CM_KL_Anz_auto_hl_Cx1_Ein)}, range raw 0..1, transfer-property=PENDING  # Rückmeldung "Auto Heck"
            signal KL_Anz_seite_hl_XIX_KLhe_01_XIX_Klima_LIN4: start 4, 1 bit, little-endian, data-type-policy=OVERRIDE, i-signal-type=PRIMITIVE, init-value=0, base-type=BT_KL_Anz_seite_hl, compu {0=Cx0_Aus (CM_KL_Anz_seite_hl_Cx0_Aus), 1=Cx1_Ein (CM_KL_Anz_seite_hl_Cx1_Ein)}, range raw 0..1, transfer-property=PENDING  # Rückmeldung "Luftverteilung Seitenscheibe Heck"
            signal KL_Anz_seite_defog_hl_XIX_KLhe_01_XIX_Klima_LIN4: start 5, 1 bit, little-endian, data-type-policy=OVERRIDE, i-signal-type=PRIMITIVE, init-value=0, base-type=BT_KL_Anz_seite_defog_hl, compu {0=Cx0_Aus (CM_KL_Anz_seite_defog_hl_Cx0_Aus), 1=Cx1_Ein (CM_KL_Anz_seite_defog_hl_Cx1_Ein)}, range raw 0..1, transfer-property=PENDING  # Rückmeldung "Seitenscheiben-Defog Heck"
            signal KL_KLh_aus_XIX_KLhe_01_XIX_Klima_LIN4: start 8, 1 bit, little-endian, data-type-policy=OVERRIDE, i-signal-type=PRIMITIVE, base-type=BT_KL_KLh_aus, compu {0=Cx0_HeckBT_EIN (CM_KL_KLh_aus_Cx0_HeckBT_EIN), 1=Cx1_HeckBT_AUS (CM_KL_KLh_aus_Cx1_HeckBT_AUS)}, range raw 0..1, transfer-property=PENDING  # Anforderung Heckbedienteil Aus
            signal KL_KLh_LastMode_XIX_KLhe_01_XIX_Klima_LIN4: start 9, 2 bit, little-endian, data-type-policy=OVERRIDE, i-signal-type=PRIMITIVE, base-type=BT_KL_KLh_LastMode, compu {0=Cx0_LastMode_nicht_speichern (CM_KL_KLh_LastMode_Cx0_LastMode_nicht_speichern) (LastMode nicht speichern), 1=Cx1_Speichern_zeitbegrenzt (CM_KL_KLh_LastMode_Cx1_Speichern_zeitbegrenzt) (Speichern (zeitbegrenzt)), 2=Cx2_Speichern (CM_KL_KLh_LastMode_Cx2_Speichern)}, range raw 0..2, transfer-property=PENDING  # Übermittlung an Sitzheizung Heck, ob LastMode zu speichern ist.
            signal KL_KLh_lock_XIX_KLhe_01_XIX_Klima_LIN4: start 11, 1 bit, little-endian, data-type-policy=OVERRIDE, i-signal-type=PRIMITIVE, base-type=BT_KL_KLh_lock, compu {0=Cx0_Bedienung_HeckBT_nicht_gesperrt (CM_KL_KLh_lock_Cx0_Bedienung_HeckBT_nicht_gesperrt) (Bedienung HeckBT nicht gesperrt), 1=Cx1_Bedienung_HeckBT_gesperrt (CM_KL_KLh_lock_Cx1_Bedienung_HeckBT_gesperrt) (Bedienung HeckBT gesperrt)}, range raw 0..1, transfer-property=PENDING  # Das KlimaBT (front) unterbindet die Bedienung der Klimafunktionen des HeckBT durch Fahrgast hintere Reihe.
            signal KL_StellgliedtestINV_Heck_XIX_KLhe_01_XIX_Klima_LIN4: start 12, 1 bit, little-endian, data-type-policy=OVERRIDE, i-signal-type=PRIMITIVE, init-value=1, base-type=BT_KL_StellgliedtestINV_Heck, compu {0=Cx0_aktiv (CM_KL_StellgliedtestINV_Heck_Cx0_aktiv), 1=Cx1_inaktiv (CM_KL_StellgliedtestINV_Heck_Cx1_inaktiv)}, range raw 0..1, transfer-property=PENDING  # KlimaBT sendet an HeckBT Info über Status Stellgliedtest bzgl. Komponenten Heck.
            signal KL_Sitzkennlinie_Heck_XIX_KLhe_01_XIX_Klima_LIN4: start 13, 3 bit, little-endian, data-type-policy=OVERRIDE, i-signal-type=PRIMITIVE, base-type=BT_KL_Sitzkennlinie_Heck, compu {phys=raw for raw 0..7; unit Unit_None}, range phys 0..7 Unit_None, raw 0..7, unit=Unit_None, transfer-property=PENDING  # Globaler fester Satz von Applikationskennlinien Sitzheizung in HeckBT, ausgewählt für Fahrzeugprojekt.
            signal KL_Anz_Temp_hl_XIX_KLhe_01_XIX_Klima_LIN4: start 16, 8 bit, little-endian, data-type-policy=OVERRIDE, i-signal-type=PRIMITIVE, init-value=254, base-type=BT_KL_Anz_Temp_hl, invalid-value=Invalid_KL_Anz_Temp_hl_XIX_KLhe_01_XIX_Klima_LIN4:255, compu {0=Cx0_Low (CM_KL_Anz_Temp_hl_Cx0_Low), phys=raw for raw 1..250, 251=Cxfb_Anzeige_ECO (CM_KL_Anz_Temp_hl_Cxfb_Anzeige_ECO), 252=Cxfc_High (CM_KL_Anz_Temp_hl_Cxfc_High), 253=Cxfd_Keine_TemperaturAnzeige (CM_KL_Anz_Temp_hl_Cxfd_Keine_TemperaturAnzeige), 254=Cxfe_Init (CM_KL_Anz_Temp_hl_Cxfe_Init), 255=Cxff_Fehler (CM_KL_Anz_Temp_hl_Cxff_Fehler); unit Unit_None}, range phys 1..250 Unit_None, raw 0..255, unit=Unit_None, transfer-property=PENDING  # Soll-Temperatur Heck. Interpretation Intervall [1, 250] ist abhängig von Signal "KL_Anz_Temp_Einheit": °C: Offset=-50, Step=0,5 F: Offset=-50, Step=1 TempStufen: Offset=0, Step=1 physikalischer Wertebereich auf [1, 250] begrenzt logischer Wert für "ECO" hinzugefügt
            signal KL_Anz_Geblaese_hl_XIX_KLhe_01_XIX_Klima_LIN4: start 24, 4 bit, little-endian, data-type-policy=OVERRIDE, i-signal-type=PRIMITIVE, init-value=14, base-type=BT_KL_Anz_Geblaese_hl, invalid-value=Invalid_KL_Anz_Geblaese_hl_XIX_KLhe_01_XIX_Klima_LIN4:15, compu {phys=raw for raw 0..12, 13=Cxd_Keine_GeblaeseAnzeige (CM_KL_Anz_Geblaese_hl_Cxd_Keine_GeblaeseAnzeige), 14=Cxe_Init (CM_KL_Anz_Geblaese_hl_Cxe_Init), 15=Cxf_Fehler (CM_KL_Anz_Geblaese_hl_Cxf_Fehler); unit Unit_None}, range phys 0..12 Unit_None, raw 0..15, unit=Unit_None, transfer-property=PENDING  # Gebläsebalken Heck
            signal KL_SIH_Anforderung_hl_XIX_KLhe_01_XIX_Klima_LIN4: start 32, 3 bit, little-endian, data-type-policy=OVERRIDE, i-signal-type=PRIMITIVE, base-type=BT_KL_SIH_Anforderung_hl, compu {0=Cx0_Stufe_0_angefordert (CM_KL_SIH_Anforderung_hl_Cx0_Stufe_0_angefordert) (Stufe_0 angefordert), 1=Cx1_Stufe_1_angefordert (CM_KL_SIH_Anforderung_hl_Cx1_Stufe_1_angefordert) (Stufe_1 angefordert), 2=Cx2_Stufe_2_angefordert (CM_KL_SIH_Anforderung_hl_Cx2_Stufe_2_angefordert) (Stufe_2 angefordert), 3=Cx3_Stufe_3_angefordert (CM_KL_SIH_Anforderung_hl_Cx3_Stufe_3_angefordert) (Stufe_3 angefordert), 4=Cx4_Stufe_4_angefordert (CM_KL_SIH_Anforderung_hl_Cx4_Stufe_4_angefordert) (Stufe_4 angefordert), 5=Cx5_Stufe_5_angefordert (CM_KL_SIH_Anforderung_hl_Cx5_Stufe_5_angefordert) (Stufe_5 angefordert), 6=Cx6_Stufe_6_angefordert (CM_KL_SIH_Anforderung_hl_Cx6_Stufe_6_angefordert) (Stufe_6 angefordert), 7=Cx7_Keine_Anforderung (CM_KL_SIH_Anforderung_hl_Cx7_Keine_Anforderung) (Keine Anforderung)}, range raw 0..7, transfer-property=PENDING  # Anforderung der Sitzheizung Heck linke Seite durch KlimaBT.
            signal KL_SIH_Anforderung_hr_XIX_KLhe_01_XIX_Klima_LIN4: start 35, 3 bit, little-endian, data-type-policy=OVERRIDE, i-signal-type=PRIMITIVE, base-type=BT_KL_SIH_Anforderung_hr, compu {0=Cx0_Stufe_0_angefordert (CM_KL_SIH_Anforderung_hr_Cx0_Stufe_0_angefordert) (Stufe_0 angefordert), 1=Cx1_Stufe_1_angefordert (CM_KL_SIH_Anforderung_hr_Cx1_Stufe_1_angefordert) (Stufe_1 angefordert), 2=Cx2_Stufe_2_angefordert (CM_KL_SIH_Anforderung_hr_Cx2_Stufe_2_angefordert) (Stufe_2 angefordert), 3=Cx3_Stufe_3_angefordert (CM_KL_SIH_Anforderung_hr_Cx3_Stufe_3_angefordert) (Stufe_3 angefordert), 4=Cx4_Stufe_4_angefordert (CM_KL_SIH_Anforderung_hr_Cx4_Stufe_4_angefordert) (Stufe_4 angefordert), 5=Cx5_Stufe_5_angefordert (CM_KL_SIH_Anforderung_hr_Cx5_Stufe_5_angefordert) (Stufe_5 angefordert), 6=Cx6_Stufe_6_angefordert (CM_KL_SIH_Anforderung_hr_Cx6_Stufe_6_angefordert) (Stufe_6 angefordert), 7=Cx7_Keine_Anforderung (CM_KL_SIH_Anforderung_hr_Cx7_Keine_Anforderung) (Keine Anforderung)}, range raw 0..7, transfer-property=PENDING  # Anforderung der Sitzheizung Heck rechte Seite durch KlimaBT.
            signal KL_Anz_Temp_Einheit_XIX_KLhe_01_XIX_Klima_LIN4: start 38, 2 bit, little-endian, data-type-policy=OVERRIDE, i-signal-type=PRIMITIVE, base-type=BT_KL_Anz_Temp_Einheit, compu {0=Cx0_Celsius (CM_KL_Anz_Temp_Einheit_Cx0_Celsius), 1=Cx1_Fahrenheit (CM_KL_Anz_Temp_Einheit_Cx1_Fahrenheit), 2=Cx2_TemperaturStufen (CM_KL_Anz_Temp_Einheit_Cx2_TemperaturStufen), 3=Cx3_reserviert (CM_KL_Anz_Temp_Einheit_Cx3_reserviert)}, range raw 0..3, transfer-property=PENDING  # Vorgabe zur Interpretation der Temperaturanzeuge Heck.
            signal KL_Anz_Temp_hr_XIX_KLhe_01_XIX_Klima_LIN4: start 40, 8 bit, little-endian, data-type-policy=OVERRIDE, i-signal-type=PRIMITIVE, init-value=254, base-type=BT_KL_Anz_Temp_hr, invalid-value=Invalid_KL_Anz_Temp_hr_XIX_KLhe_01_XIX_Klima_LIN4:255, compu {0=Cx0_Low (CM_KL_Anz_Temp_hr_Cx0_Low), phys=raw for raw 1..250, 251=Cxfb_Anzeige_ECO (CM_KL_Anz_Temp_hr_Cxfb_Anzeige_ECO), 252=Cxfc_High (CM_KL_Anz_Temp_hr_Cxfc_High), 253=Cxfd_Keine_TemperaturAnzeige (CM_KL_Anz_Temp_hr_Cxfd_Keine_TemperaturAnzeige), 254=Cxfe_Init (CM_KL_Anz_Temp_hr_Cxfe_Init), 255=Cxff_Fehler (CM_KL_Anz_Temp_hr_Cxff_Fehler); unit Unit_None}, range phys 1..250 Unit_None, raw 0..255, unit=Unit_None, transfer-property=PENDING  # Soll-Temperatur Heck (rechts). Interpretation Intervall [1, 250] ist abhängig von Signal "KL_Anz_Temp_Einheit": °C: Offset=-50, Step=0,5 F: Offset=-50, Step=1 TempStufen: Offset=0, Step=1 physikalischer Wertebereich auf [1, 250] begrenzt logischer Wert für "ECO" hinzugefügt
            signal KL_HBT_Geblaesestufe_anzeigen_XIX_KLhe_01_XIX_Klima_LIN4: start 48, 2 bit, little-endian, data-type-policy=OVERRIDE, i-signal-type=PRIMITIVE, init-value=1, base-type=BT_KL_HBT_Geblaesestufe_anzeigen, compu {0=Cx0_Geblaesestufe_anzeigen (CM_KL_HBT_Geblaesestufe_anzeigen_Cx0_Geblaesestufe_anzeigen), 1=Cx1_Geblaesestufe_ausblenden (CM_KL_HBT_Geblaesestufe_anzeigen_Cx1_Geblaesestufe_ausblenden), 2=Cx2_reserviert (CM_KL_HBT_Geblaesestufe_anzeigen_Cx2_reserviert), 3=Cx3_reserviert (CM_KL_HBT_Geblaesestufe_anzeigen_Cx3_reserviert)}, range raw 0..3, transfer-property=PENDING  # Wenn zwei Heckbedienteile (HBT) im Fahrzeug verbaut sind, wird über dieses Signal eine synchrone Anzeige der Gebläsestufe sichergestellt. Wird an einem HBT die Gebläsestufe verändert, wird über diesen Flag dem anderen HBT signalisiert, die aktuelle Gebläsestufe ebenfalls anzuzeigen.
            signal KL_HBT_Verbausituation_XIX_KLhe_01_XIX_Klima_LIN4: start 50, 2 bit, little-endian, data-type-policy=OVERRIDE, i-signal-type=PRIMITIVE, init-value=1, base-type=BT_KL_HBT_Verbausituation, compu {0=Cx0_Zwei_Heckbedienteile (CM_KL_HBT_Verbausituation_Cx0_Zwei_Heckbedienteile), 1=Cx1_Ein_Heckbedienteil (CM_KL_HBT_Verbausituation_Cx1_Ein_Heckbedienteil), 2=Cx2_reserviert (CM_KL_HBT_Verbausituation_Cx2_reserviert), 3=Cx3_reserviert (CM_KL_HBT_Verbausituation_Cx3_reserviert)}, range raw 0..3, transfer-property=PENDING  # Gibt die Verbausituation der Heckbedienteile (HBT) an. Im Fahrzeug können für die Bedienung der hinteren Klimazone auch mehrere HBTs verbaut sein. Für eine synchrone Anzeige der Geläbsestufe wird über dieses Signal die Verbausituation dauerhaft gesendet.
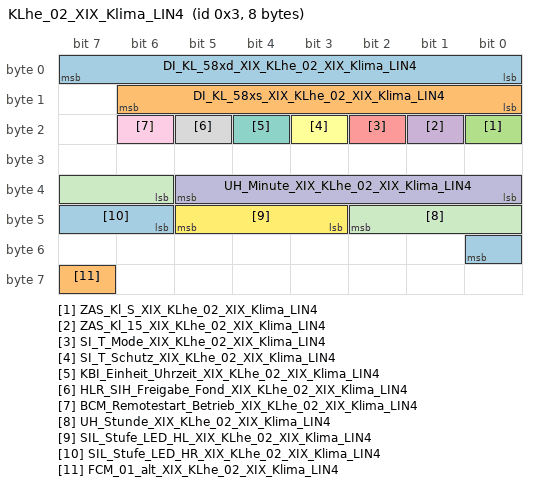
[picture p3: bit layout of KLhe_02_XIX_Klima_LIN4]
        frame KLhe_02_XIX_Klima_LIN4: id 0x3, from Klima, frame-length=8, lin-checksum=ENHANCED
          pdu KLhe_02_XIX_Klima_LIN4: length=8, unused-bit-pattern=0
            signal DI_KL_58xd_XIX_KLhe_02_XIX_Klima_LIN4: start 0, 8 bit, little-endian, data-type-policy=OVERRIDE, i-signal-type=PRIMITIVE, init-value=254, base-type=BT_DI_KL_58xd, invalid-value=Invalid_DI_KL_58xd_XIX_KLhe_02_XIX_Klima_LIN4:255, compu {phys=raw for raw 0..253, 254=Cxfe_Init (CM_DI_KL_58xd_Cxfe_Init), 255=Cxff_Fehler (CM_DI_KL_58xd_Cxff_Fehler)}, range phys 0..253, raw 0..255, transfer-property=PENDING  # Klemme 58xd Display- und Funktionsbeleuchtung Mit der Klemme 58xd wird die Helligkeit der Display- und der Funktionsbeleuchtungen der Schalter gesteuert. Im Detail beschrieben im 'Funktionslastenheft Dimmung MQB'.
            signal DI_KL_58xs_XIX_KLhe_02_XIX_Klima_LIN4: start 8, 7 bit, little-endian, data-type-policy=OVERRIDE, i-signal-type=PRIMITIVE, init-value=126, base-type=BT_DI_KL_58xs, invalid-value=Invalid_DI_KL_58xs_XIX_KLhe_02_XIX_Klima_LIN4:127, compu {phys=raw for raw 0..100, 126=Cx7e_Init (CM_DI_KL_58xs_Cx7e_Init), 127=Cx7f_Fehler (CM_DI_KL_58xs_Cx7f_Fehler); unit Unit_PerCent}, range phys 0..100 Unit_PerCent, raw 0..127, unit=Unit_PerCent, transfer-property=PENDING  # Suchbeleuchtung Schalter EIN-AUS-Schaltalgorithmus der allgemeinen Schaltersuchbeleuchtung. Im Detail beschrieben im 'Funktionslastenheft Dimmung MQB'.
            signal ZAS_Kl_S_XIX_KLhe_02_XIX_Klima_LIN4: start 16, 1 bit, little-endian, data-type-policy=OVERRIDE, i-signal-type=PRIMITIVE, init-value=0, base-type=BT_ZAS_Kl_S, compu {0=Cx0_aus (CM_ZAS_Kl_S_Cx0_aus), 1=Cx1_S_Kontakt_ein (CM_ZAS_Kl_S_Cx1_S_Kontakt_ein)}, range raw 0..1, transfer-property=PENDING  # Klemme S: S-Kontakt (Schluessel steckt)
            signal ZAS_Kl_15_XIX_KLhe_02_XIX_Klima_LIN4: start 17, 1 bit, little-endian, data-type-policy=OVERRIDE, i-signal-type=PRIMITIVE, init-value=0, base-type=BT_ZAS_Kl_15, compu {0=Cx0_aus (CM_ZAS_Kl_15_Cx0_aus), 1=Cx1_ein (CM_ZAS_Kl_15_Cx1_ein)}, range raw 0..1, transfer-property=PENDING  # Klemme 15: Zuendung (SW-Kl.15)
            signal SI_T_Mode_XIX_KLhe_02_XIX_Klima_LIN4: start 18, 1 bit, little-endian, data-type-policy=OVERRIDE, i-signal-type=PRIMITIVE, init-value=0, base-type=BT_SI_T_Mode, compu {0=Cx0_Transportmodus_nicht_aktiv (CM_SI_T_Mode_Cx0_Transportmodus_nicht_aktiv), 1=Cx1_Transportmodus_aktiv (CM_SI_T_Mode_Cx1_Transportmodus_aktiv)}, range raw 0..1, transfer-property=PENDING  # 0x0: Transportmodus nicht aktiv 0x1: Transportmodus aktiv
            signal SI_T_Schutz_XIX_KLhe_02_XIX_Klima_LIN4: start 19, 1 bit, little-endian, data-type-policy=OVERRIDE, i-signal-type=PRIMITIVE, init-value=0, base-type=BT_SI_T_Schutz, compu {0=Cx0_Transportschutz_nicht_aktiv (CM_SI_T_Schutz_Cx0_Transportschutz_nicht_aktiv), 1=Cx1_Transportschutz_aktiv (CM_SI_T_Schutz_Cx1_Transportschutz_aktiv)}, range raw 0..1, transfer-property=PENDING  # Transportschutz-Signal, das bei Transportmodus und Motorlauf aktiv bleibt 0x0: Transportschutz nicht aktiv 0x1: Transportschutz aktiv
            signal KBI_Einheit_Uhrzeit_XIX_KLhe_02_XIX_Klima_LIN4: start 20, 1 bit, little-endian, data-type-policy=OVERRIDE, i-signal-type=PRIMITIVE, init-value=0, base-type=BT_KBI_Einheit_Uhrzeit, compu {0=Cx0_24h (CM_KBI_Einheit_Uhrzeit_Cx0_24h), 1=Cx1_12h_AM_PM (CM_KBI_Einheit_Uhrzeit_Cx1_12h_AM_PM) (12h AM/PM)}, range raw 0..1, transfer-property=PENDING  # Anzeigevariante der Uhrzeit
            signal HLR_SIH_Freigabe_Fond_XIX_KLhe_02_XIX_Klima_LIN4: start 21, 1 bit, little-endian, data-type-policy=OVERRIDE, i-signal-type=PRIMITIVE, init-value=0, base-type=BT_HLR_SIH_Freigabe_Fond, compu {0=Cx0_keine_Freigabe (CM_HLR_SIH_Freigabe_Fond_Cx0_keine_Freigabe), 1=Cx1_Freigabe (CM_HLR_SIH_Freigabe_Fond_Cx1_Freigabe)}, range raw 0..1, transfer-property=PENDING  # Freigabe des EM für Sitzheizungen hinten
            signal BCM_Remotestart_Betrieb_XIX_KLhe_02_XIX_Klima_LIN4: start 22, 1 bit, little-endian, data-type-policy=OVERRIDE, i-signal-type=PRIMITIVE, init-value=0, base-type=BT_BCM_Remotestart_Betrieb, compu {0=Cx0_kein_RS_Betrieb (CM_BCM_Remotestart_Betrieb_Cx0_kein_RS_Betrieb), 1=Cx1_RS_Betrieb (CM_BCM_Remotestart_Betrieb_Cx1_RS_Betrieb)}, range raw 0..1, transfer-property=PENDING  # Zeigt den Status des RemoteStarts an, d.h. KL15_RSt ist aktiviert und der Motorlauf ist im RSt-Betrieb aktiv.
            signal UH_Minute_XIX_KLhe_02_XIX_Klima_LIN4: start 32, 6 bit, little-endian, data-type-policy=OVERRIDE, i-signal-type=PRIMITIVE, init-value=0, base-type=BT_UH_Minute, compu {phys=raw for raw 0..59; unit Unit_Minut}, range phys 0..59 Unit_Minut, raw 0..59, unit=Unit_Minut, transfer-property=PENDING  # 0x3C- 0x3f = Werte ungültig
            signal UH_Stunde_XIX_KLhe_02_XIX_Klima_LIN4: start 38, 5 bit, little-endian, data-type-policy=OVERRIDE, i-signal-type=PRIMITIVE, init-value=0, base-type=BT_UH_Stunde, compu {phys=raw for raw 0..23; unit Unit_Hours}, range phys 0..23 Unit_Hours, raw 0..23, unit=Unit_Hours, transfer-property=PENDING  # 0x18 - 0x1F = Werte ungültig
            signal SIL_Stufe_LED_HL_XIX_KLhe_02_XIX_Klima_LIN4: start 43, 3 bit, little-endian, data-type-policy=OVERRIDE, i-signal-type=PRIMITIVE, init-value=0, base-type=BT_SIL_Stufe_LED_HL, compu {0=Cx0_Aus (CM_SIL_Stufe_LED_HL_Cx0_Aus), 1=Cx1_Stufe_1 (CM_SIL_Stufe_LED_HL_Cx1_Stufe_1), 2=Cx2_Stufe_2 (CM_SIL_Stufe_LED_HL_Cx2_Stufe_2), 3=Cx3_Stufe_3 (CM_SIL_Stufe_LED_HL_Cx3_Stufe_3), 4=Cx4_Stufe_4 (CM_SIL_Stufe_LED_HL_Cx4_Stufe_4), 5=Cx5_Stufe_5 (CM_SIL_Stufe_LED_HL_Cx5_Stufe_5), 6=Cx6_Stufe_6 (CM_SIL_Stufe_LED_HL_Cx6_Stufe_6)}, range raw 0..6, transfer-property=PENDING  # Statusmeldung Sitzlüftung hinten links
            signal SIL_Stufe_LED_HR_XIX_KLhe_02_XIX_Klima_LIN4: start 46, 3 bit, little-endian, data-type-policy=OVERRIDE, i-signal-type=PRIMITIVE, init-value=0, base-type=BT_SIL_Stufe_LED_HR, compu {0=Cx0_Aus (CM_SIL_Stufe_LED_HR_Cx0_Aus), 1=Cx1_Stufe_1 (CM_SIL_Stufe_LED_HR_Cx1_Stufe_1), 2=Cx2_Stufe_2 (CM_SIL_Stufe_LED_HR_Cx2_Stufe_2), 3=Cx3_Stufe_3 (CM_SIL_Stufe_LED_HR_Cx3_Stufe_3), 4=Cx4_Stufe_4 (CM_SIL_Stufe_LED_HR_Cx4_Stufe_4), 5=Cx5_Stufe_5 (CM_SIL_Stufe_LED_HR_Cx5_Stufe_5), 6=Cx6_Stufe_6 (CM_SIL_Stufe_LED_HR_Cx6_Stufe_6)}, range raw 0..6, transfer-property=PENDING  # Statusmeldung Sitzlüftung hinten rechts
            signal FCM_01_alt_XIX_KLhe_02_XIX_Klima_LIN4: start 63, 1 bit, little-endian, data-type-policy=OVERRIDE, i-signal-type=PRIMITIVE, init-value=1, base-type=BT_FCM_01_alt, compu {0=Cx0_aktuell (CM_FCM_01_alt_Cx0_aktuell), 1=Cx1_veraltet (CM_FCM_01_alt_Cx1_veraltet)}, range raw 0..1, transfer-property=PENDING  # Veraltet Bit für die Botschaft FCM_01
        frame KLhs_01_XIX_Klima_LIN4: id 0x2, to Klima, frame-length=8, lin-checksum=ENHANCED
          pdu KLhs_01_XIX_Klima_LIN4: length=8, unused-bit-pattern=0
            signal KLh_Fehler1_XIX_KLhs_01_XIX_Klima_LIN4: start 0, 1 bit, little-endian, data-type-policy=OVERRIDE, i-signal-type=PRIMITIVE, init-value=0, base-type=BT_KLh_Fehler1, compu {0=Cx0_T5_Heck_normal (CM_KLh_Fehler1_Cx0_T5_Heck_normal) (T5 Heck normal), 1=Cx1_T5_Heck_Fehler (CM_KLh_Fehler1_Cx1_T5_Heck_Fehler) (T5 Heck Fehler)}, range raw 0..1, transfer-property=PENDING, to Klima(timeout 3.5 s)  # Heckbedienteil Fehler1
            signal KLh_Fehler2_XIX_KLhs_01_XIX_Klima_LIN4: start 1, 1 bit, little-endian, data-type-policy=OVERRIDE, i-signal-type=PRIMITIVE, init-value=0, base-type=BT_KLh_Fehler2, compu {0=Cx0_T5_Heck_normal (CM_KLh_Fehler2_Cx0_T5_Heck_normal) (T5 Heck normal), 1=Cx1_T5_Heck_Fehler (CM_KLh_Fehler2_Cx1_T5_Heck_Fehler) (T5 Heck Fehler)}, range raw 0..1, transfer-property=PENDING, to Klima(timeout 3.5 s)  # Heckbedienteil Fehler2
            signal KLh_Fehler3_XIX_KLhs_01_XIX_Klima_LIN4: start 2, 1 bit, little-endian, data-type-policy=OVERRIDE, i-signal-type=PRIMITIVE, init-value=0, base-type=BT_KLh_Fehler3, compu {0=Cx0_T5_Heck_normal (CM_KLh_Fehler3_Cx0_T5_Heck_normal) (T5 Heck normal), 1=Cx1_T5_Heck_Fehler (CM_KLh_Fehler3_Cx1_T5_Heck_Fehler) (T5 Heck Fehler)}, range raw 0..1, transfer-property=PENDING, to Klima(timeout 3.5 s)  # Heckbedienteil Fehler3
            signal KLh_Fehler4_XIX_KLhs_01_XIX_Klima_LIN4: start 3, 1 bit, little-endian, data-type-policy=OVERRIDE, i-signal-type=PRIMITIVE, init-value=0, base-type=BT_KLh_Fehler4, compu {0=Cx0_T5_Heck_normal (CM_KLh_Fehler4_Cx0_T5_Heck_normal) (T5 Heck normal), 1=Cx1_T5_Heck_Fehler (CM_KLh_Fehler4_Cx1_T5_Heck_Fehler) (T5 Heck Fehler)}, range raw 0..1, transfer-property=PENDING, to Klima(timeout 3.5 s)  # Heckbedienteil Fehler4
            signal KLh_Fehler5_XIX_KLhs_01_XIX_Klima_LIN4: start 4, 1 bit, little-endian, data-type-policy=OVERRIDE, i-signal-type=PRIMITIVE, init-value=0, base-type=BT_KLh_Fehler5, compu {0=Cx0_T5_Heck_normal (CM_KLh_Fehler5_Cx0_T5_Heck_normal) (T5 Heck normal), 1=Cx1_T5_Heck_Fehler (CM_KLh_Fehler5_Cx1_T5_Heck_Fehler) (T5 Heck Fehler)}, range raw 0..1, transfer-property=PENDING, to Klima(timeout 3.5 s)  # Heckbedienteil Fehler5
            signal KLh_Fehler6_XIX_KLhs_01_XIX_Klima_LIN4: start 5, 1 bit, little-endian, data-type-policy=OVERRIDE, i-signal-type=PRIMITIVE, init-value=0, base-type=BT_KLh_Fehler6, compu {0=Cx0_T5_Heck_normal (CM_KLh_Fehler6_Cx0_T5_Heck_normal) (T5 Heck normal), 1=Cx1_T5_Heck_Fehler (CM_KLh_Fehler6_Cx1_T5_Heck_Fehler) (T5 Heck Fehler)}, range raw 0..1, transfer-property=PENDING, to Klima(timeout 3.5 s)  # Heckbedienteil Fehler6
            signal KLh_Fehler7_XIX_KLhs_01_XIX_Klima_LIN4: start 6, 1 bit, little-endian, data-type-policy=OVERRIDE, i-signal-type=PRIMITIVE, init-value=0, base-type=BT_KLh_Fehler7, compu {0=Cx0_T5_Heck_normal (CM_KLh_Fehler7_Cx0_T5_Heck_normal) (T5 Heck normal), 1=Cx1_T5_Heck_Fehler (CM_KLh_Fehler7_Cx1_T5_Heck_Fehler) (T5 Heck Fehler)}, range raw 0..1, transfer-property=PENDING, to Klima(timeout 3.5 s)  # Heckbedienteil Fehler7
            signal KLh_Fehler8_XIX_KLhs_01_XIX_Klima_LIN4: start 7, 1 bit, little-endian, data-type-policy=OVERRIDE, i-signal-type=PRIMITIVE, init-value=0, base-type=BT_KLh_Fehler8, compu {0=Cx0_T5_Heck_normal (CM_KLh_Fehler8_Cx0_T5_Heck_normal) (T5 Heck normal), 1=Cx1_T5_Heck_Fehler (CM_KLh_Fehler8_Cx1_T5_Heck_Fehler) (T5 Heck Fehler)}, range raw 0..1, transfer-property=PENDING, to Klima(timeout 3.5 s)  # Heckbedienteil Fehler8
            signal KLhl_GeblaeseSoll_XIX_KLhs_01_XIX_Klima_LIN4: start 8, 4 bit, little-endian, data-type-policy=OVERRIDE, i-signal-type=PRIMITIVE, init-value=0, base-type=BT_KLhl_GeblaeseSoll, compu {0=Cx0_keine_Ticks (CM_KLhl_GeblaeseSoll_Cx0_keine_Ticks) (keine Ticks), 1=Cx1_1_Ticks (CM_KLhl_GeblaeseSoll_Cx1_1_Ticks) (+1 Ticks), 2=Cx2_2_Ticks (CM_KLhl_GeblaeseSoll_Cx2_2_Ticks) (+2 Ticks), 3=Cx3_3_Ticks (CM_KLhl_GeblaeseSoll_Cx3_3_Ticks) (+3 Ticks), 4=Cx4_4_Ticks (CM_KLhl_GeblaeseSoll_Cx4_4_Ticks) (+4 Ticks), 5=Cx5_5_Ticks (CM_KLhl_GeblaeseSoll_Cx5_5_Ticks) (+5 Ticks), 6=Cx6_6_Ticks (CM_KLhl_GeblaeseSoll_Cx6_6_Ticks) (+6 Ticks), 7=Cx7_7_Ticks (CM_KLhl_GeblaeseSoll_Cx7_7_Ticks) (+7 Ticks), 8=Cx8_Fehlerwert (CM_KLhl_GeblaeseSoll_Cx8_Fehlerwert), 9=Cx9_7_Ticks (CM_KLhl_GeblaeseSoll_Cx9_7_Ticks) (-7 Ticks), 10=Cxa_6_Ticks (CM_KLhl_GeblaeseSoll_Cxa_6_Ticks) (-6 Ticks), 11=Cxb_5_Ticks (CM_KLhl_GeblaeseSoll_Cxb_5_Ticks) (-5 Ticks), 12=Cxc_5_Ticks (CM_KLhl_GeblaeseSoll_Cxc_5_Ticks) (-5 Ticks), 13=Cxd_3_Ticks (CM_KLhl_GeblaeseSoll_Cxd_3_Ticks) (-3 Ticks), 14=Cxe_2_Ticks (CM_KLhl_GeblaeseSoll_Cxe_2_Ticks) (-2 Ticks), 15=Cxf_1_Ticks (CM_KLhl_GeblaeseSoll_Cxf_1_Ticks) (-1 Ticks)}, range raw 0..15, transfer-property=PENDING, to Klima(timeout 3.5 s)  # VW428
            signal KLhl_TempSoll_XIX_KLhs_01_XIX_Klima_LIN4: start 12, 4 bit, little-endian, data-type-policy=OVERRIDE, i-signal-type=PRIMITIVE, init-value=0, base-type=BT_KLhl_TempSoll, compu {0=Cx0_keine_Ticks (CM_KLhl_TempSoll_Cx0_keine_Ticks) (keine Ticks), 1=Cx1_1_Ticks (CM_KLhl_TempSoll_Cx1_1_Ticks) (+1 Ticks), 2=Cx2_2_Ticks (CM_KLhl_TempSoll_Cx2_2_Ticks) (+2 Ticks), 3=Cx3_3_Ticks (CM_KLhl_TempSoll_Cx3_3_Ticks) (+3 Ticks), 4=Cx4_4_Ticks (CM_KLhl_TempSoll_Cx4_4_Ticks) (+4 Ticks), 5=Cx5_5_Ticks (CM_KLhl_TempSoll_Cx5_5_Ticks) (+5 Ticks), 6=Cx6_6_Ticks (CM_KLhl_TempSoll_Cx6_6_Ticks) (+6 Ticks), 7=Cx7_7_Ticks (CM_KLhl_TempSoll_Cx7_7_Ticks) (+7 Ticks), 8=Cx8_Fehlerwert (CM_KLhl_TempSoll_Cx8_Fehlerwert), 9=Cx9_7_Ticks (CM_KLhl_TempSoll_Cx9_7_Ticks) (-7 Ticks), 10=Cxa_6_Ticks (CM_KLhl_TempSoll_Cxa_6_Ticks) (-6 Ticks), 11=Cxb_5_Ticks (CM_KLhl_TempSoll_Cxb_5_Ticks) (-5 Ticks), 12=Cxc_5_Ticks (CM_KLhl_TempSoll_Cxc_5_Ticks) (-5 Ticks), 13=Cxd_3_Ticks (CM_KLhl_TempSoll_Cxd_3_Ticks) (-3 Ticks), 14=Cxe_2_Ticks (CM_KLhl_TempSoll_Cxe_2_Ticks) (-2 Ticks), 15=Cxf_1_Ticks (CM_KLhl_TempSoll_Cxf_1_Ticks) (-1 Ticks)}, range raw 0..15, transfer-property=PENDING, to Klima(timeout 3.5 s)  # VW428
            signal KLhl_Luft_oben_XIX_KLhs_01_XIX_Klima_LIN4: start 16, 1 bit, little-endian, data-type-policy=OVERRIDE, i-signal-type=PRIMITIVE, init-value=0, base-type=BT_KLhl_Luft_oben, compu {0=Cx0_nicht_betaetigt (CM_KLhl_Luft_oben_Cx0_nicht_betaetigt), 1=Cx1_betaetigt (CM_KLhl_Luft_oben_Cx1_betaetigt)}, range raw 0..1, transfer-property=PENDING, to Klima(timeout 3.5 s)  # VW428
            signal KLhl_Luft_mitte_XIX_KLhs_01_XIX_Klima_LIN4: start 17, 1 bit, little-endian, data-type-policy=OVERRIDE, i-signal-type=PRIMITIVE, init-value=0, base-type=BT_KLhl_Luft_mitte, compu {0=Cx0_nicht_betaetigt (CM_KLhl_Luft_mitte_Cx0_nicht_betaetigt), 1=Cx1_betaetigt (CM_KLhl_Luft_mitte_Cx1_betaetigt)}, range raw 0..1, transfer-property=PENDING, to Klima(timeout 3.5 s)  # Tastendruck "Luftverteilung Mannanströmer Heck"
            signal KLhl_Luft_unten_XIX_KLhs_01_XIX_Klima_LIN4: start 18, 1 bit, little-endian, data-type-policy=OVERRIDE, i-signal-type=PRIMITIVE, init-value=0, base-type=BT_KLhl_Luft_unten, compu {0=Cx0_nicht_betaetigt (CM_KLhl_Luft_unten_Cx0_nicht_betaetigt), 1=Cx1_betaetigt (CM_KLhl_Luft_unten_Cx1_betaetigt)}, range raw 0..1, transfer-property=PENDING, to Klima(timeout 3.5 s)  # Tastendruck "Luftverteilung Fußraum Heck"
            signal KLhl_Luft_auto_XIX_KLhs_01_XIX_Klima_LIN4: start 19, 1 bit, little-endian, data-type-policy=OVERRIDE, i-signal-type=PRIMITIVE, init-value=0, base-type=BT_KLhl_Luft_auto, compu {0=Cx0_nicht_betaetigt (CM_KLhl_Luft_auto_Cx0_nicht_betaetigt), 1=Cx1_betaetigt (CM_KLhl_Luft_auto_Cx1_betaetigt)}, range raw 0..1, transfer-property=PENDING, to Klima(timeout 3.5 s)  # Tastendruck "Auto Heck"
            signal KLhl_Luft_seite_XIX_KLhs_01_XIX_Klima_LIN4: start 20, 1 bit, little-endian, data-type-policy=OVERRIDE, i-signal-type=PRIMITIVE, init-value=0, base-type=BT_KLhl_Luft_seite, compu {0=Cx0_nicht_betaetigt (CM_KLhl_Luft_seite_Cx0_nicht_betaetigt), 1=Cx1_betaetigt (CM_KLhl_Luft_seite_Cx1_betaetigt)}, range raw 0..1, transfer-property=PENDING, to Klima(timeout 3.5 s)  # Tastendruck "Luftverteilung Seitenscheibe Heck"
            signal KLh_Seite_defog_hl_XIX_KLhs_01_XIX_Klima_LIN4: start 21, 1 bit, little-endian, data-type-policy=OVERRIDE, i-signal-type=PRIMITIVE, init-value=0, base-type=BT_KLh_Seite_defog_hl, compu {0=Cx0_nicht_betaetigt (CM_KLh_Seite_defog_hl_Cx0_nicht_betaetigt), 1=Cx1_betaetigt (CM_KLh_Seite_defog_hl_Cx1_betaetigt)}, range raw 0..1, transfer-property=PENDING, to Klima(timeout 3.5 s)  # Tastendruck "defog Heck"
            signal KLh_aus_XIX_KLhs_01_XIX_Klima_LIN4: start 22, 1 bit, little-endian, data-type-policy=OVERRIDE, i-signal-type=PRIMITIVE, base-type=BT_KLh_aus, compu {0=Cx0_Ein (CM_KLh_aus_Cx0_Ein), 1=Cx1_Aus (CM_KLh_aus_Cx1_Aus)}, range raw 0..1, transfer-property=PENDING, to Klima(timeout 3.5 s)  # Zustand HeckBT ein/aus
            signal KLhl_ResponseError_XIX_KLhs_01_XIX_Klima_LIN4: start 23, 1 bit, little-endian, data-type-policy=OVERRIDE, i-signal-type=PRIMITIVE, init-value=0, base-type=BT_KLhl_ResponseError, invalid-value=Invalid_KLhl_ResponseError_XIX_KLhs_01_XIX_Klima_LIN4:1, compu {0=Cx0_normal (CM_KLhl_ResponseError_Cx0_normal), 1=Cx1_Fehler (CM_KLhl_ResponseError_Cx1_Fehler)}, range raw 0..1, transfer-property=PENDING, to Klima(timeout 3.5 s)  # siehe LIN2.0-Specification (Kap 2.7.3) (Darf nicht über ein Fehlergueltigkeitsbit abgesichtert werden!)
            signal KLh_Ausstattung_KlimaHeck_XIX_KLhs_01_XIX_Klima_LIN4: start 24, 3 bit, little-endian, data-type-policy=OVERRIDE, i-signal-type=PRIMITIVE, base-type=BT_KLh_Ausstattung_KlimaHeck, compu {0=Cx0_Heizung_elektrisch (CM_KLh_Ausstattung_KlimaHeck_Cx0_Heizung_elektrisch), 1=Cx1_Klimamanuell_elektrisch (CM_KLh_Ausstattung_KlimaHeck_Cx1_Klimamanuell_elektrisch), 2=Cx2_Climatic_1_Zone (CM_KLh_Ausstattung_KlimaHeck_Cx2_Climatic_1_Zone), 3=Cx3_Climatronic_1_Zone (CM_KLh_Ausstattung_KlimaHeck_Cx3_Climatronic_1_Zone), 4=Cx4_Climatronic_2_Zonen (CM_KLh_Ausstattung_KlimaHeck_Cx4_Climatronic_2_Zonen), 5=Cx5_reserviert (CM_KLh_Ausstattung_KlimaHeck_Cx5_reserviert), 6=Cx6_reserviert (CM_KLh_Ausstattung_KlimaHeck_Cx6_reserviert), 7=Cx7_reserviert (CM_KLh_Ausstattung_KlimaHeck_Cx7_reserviert)}, range raw 0..7, transfer-property=PENDING, to Klima(timeout 3.5 s)  # Austtattungsart der Klimabedienung Heckbedienteil
            signal KLhr_TempSoll_XIX_KLhs_01_XIX_Klima_LIN4: start 27, 4 bit, little-endian, data-type-policy=OVERRIDE, i-signal-type=PRIMITIVE, init-value=0, base-type=BT_KLhr_TempSoll, compu {0=Cx0_keine_Ticks (CM_KLhr_TempSoll_Cx0_keine_Ticks) (keine Ticks), 1=Cx1_1_Ticks (CM_KLhr_TempSoll_Cx1_1_Ticks) (+1 Ticks), 2=Cx2_2_Ticks (CM_KLhr_TempSoll_Cx2_2_Ticks) (+2 Ticks), 3=Cx3_3_Ticks (CM_KLhr_TempSoll_Cx3_3_Ticks) (+3 Ticks), 4=Cx4_4_Ticks (CM_KLhr_TempSoll_Cx4_4_Ticks) (+4 Ticks), 5=Cx5_5_Ticks (CM_KLhr_TempSoll_Cx5_5_Ticks) (+5 Ticks), 6=Cx6_6_Ticks (CM_KLhr_TempSoll_Cx6_6_Ticks) (+6 Ticks), 7=Cx7_7_Ticks (CM_KLhr_TempSoll_Cx7_7_Ticks) (+7 Ticks), 8=Cx8_Fehlerwert (CM_KLhr_TempSoll_Cx8_Fehlerwert), 9=Cx9_7_Ticks (CM_KLhr_TempSoll_Cx9_7_Ticks) (-7 Ticks), 10=Cxa_6_Ticks (CM_KLhr_TempSoll_Cxa_6_Ticks) (-6 Ticks), 11=Cxb_5_Ticks (CM_KLhr_TempSoll_Cxb_5_Ticks) (-5 Ticks), 12=Cxc_5_Ticks (CM_KLhr_TempSoll_Cxc_5_Ticks) (-5 Ticks), 13=Cxd_3_Ticks (CM_KLhr_TempSoll_Cxd_3_Ticks) (-3 Ticks), 14=Cxe_2_Ticks (CM_KLhr_TempSoll_Cxe_2_Ticks) (-2 Ticks), 15=Cxf_1_Ticks (CM_KLhr_TempSoll_Cxf_1_Ticks) (-1 Ticks)}, range raw 0..15, transfer-property=PENDING, to Klima(timeout 3.5 s)  # Verstellung Temperatur 4. Zone durch Bedienelement Heck
            signal KLh_toggle_LVT_XIX_KLhs_01_XIX_Klima_LIN4: start 32, 2 bit, little-endian, data-type-policy=OVERRIDE, i-signal-type=PRIMITIVE, init-value=0, base-type=BT_KLh_toggle_LVT, compu {0=Cx0_nicht_betaetigt (CM_KLh_toggle_LVT_Cx0_nicht_betaetigt), 1=Cx1_betaetigt (CM_KLh_toggle_LVT_Cx1_betaetigt), 2=Cx2_long_push (CM_KLh_toggle_LVT_Cx2_long_push), 3=Cx3_klemmt (CM_KLh_toggle_LVT_Cx3_klemmt)}, range raw 0..3, transfer-property=PENDING, to Klima(timeout 3.5 s)  # Tastendruck "Toggle"
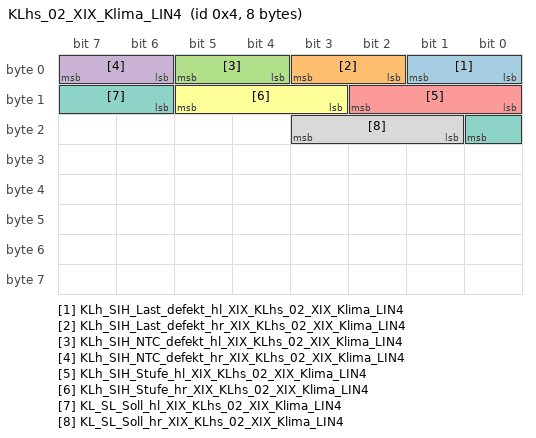
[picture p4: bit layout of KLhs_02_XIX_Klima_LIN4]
        frame KLhs_02_XIX_Klima_LIN4: id 0x4, to Klima, frame-length=8, lin-checksum=ENHANCED
          pdu KLhs_02_XIX_Klima_LIN4: length=8, unused-bit-pattern=0
            signal KLh_SIH_Last_defekt_hl_XIX_KLhs_02_XIX_Klima_LIN4: start 0, 2 bit, little-endian, data-type-policy=OVERRIDE, i-signal-type=PRIMITIVE, base-type=BT_KLh_SIH_Last_defekt_hl, compu {0=Cx0_Kein_Fehler_erkannt (CM_KLh_SIH_Last_defekt_hl_Cx0_Kein_Fehler_erkannt) (Kein Fehler erkannt), 1=Cx1_Unterbrechung (CM_KLh_SIH_Last_defekt_hl_Cx1_Unterbrechung), 2=Cx2_Kurzschluss_nach_Masse (CM_KLh_SIH_Last_defekt_hl_Cx2_Kurzschluss_nach_Masse) (Kurzschluss nach Masse)}, range raw 0..2, transfer-property=PENDING, to Klima(timeout 3.5 s)  # Diagnostizierung Sitzheizung Last Heck links.
            signal KLh_SIH_Last_defekt_hr_XIX_KLhs_02_XIX_Klima_LIN4: start 2, 2 bit, little-endian, data-type-policy=OVERRIDE, i-signal-type=PRIMITIVE, base-type=BT_KLh_SIH_Last_defekt_hr, compu {0=Cx0_Kein_Fehler_erkannt (CM_KLh_SIH_Last_defekt_hr_Cx0_Kein_Fehler_erkannt) (Kein Fehler erkannt), 1=Cx1_Unterbrechung (CM_KLh_SIH_Last_defekt_hr_Cx1_Unterbrechung), 2=Cx2_Kurzschluss_nach_Masse (CM_KLh_SIH_Last_defekt_hr_Cx2_Kurzschluss_nach_Masse) (Kurzschluss nach Masse)}, range raw 0..2, transfer-property=PENDING, to Klima(timeout 3.5 s)  # Diagnostizierung Sitzheizung Last Heck rechts.
            signal KLh_SIH_NTC_defekt_hl_XIX_KLhs_02_XIX_Klima_LIN4: start 4, 2 bit, little-endian, data-type-policy=OVERRIDE, i-signal-type=PRIMITIVE, base-type=BT_KLh_SIH_NTC_defekt_hl, compu {0=Cx0_Kein_Fehler_erkannt (CM_KLh_SIH_NTC_defekt_hl_Cx0_Kein_Fehler_erkannt) (Kein Fehler erkannt), 1=Cx1_Unterbrechung (CM_KLh_SIH_NTC_defekt_hl_Cx1_Unterbrechung), 2=Cx2_Kurzschluss_nach_Masse (CM_KLh_SIH_NTC_defekt_hl_Cx2_Kurzschluss_nach_Masse) (Kurzschluss nach Masse)}, range raw 0..2, transfer-property=PENDING, to Klima(timeout 3.5 s)  # Diagnostizierung Temperaturfühler Sitzheizung Heck links.
            signal KLh_SIH_NTC_defekt_hr_XIX_KLhs_02_XIX_Klima_LIN4: start 6, 2 bit, little-endian, data-type-policy=OVERRIDE, i-signal-type=PRIMITIVE, base-type=BT_KLh_SIH_NTC_defekt_hr, compu {0=Cx0_Kein_Fehler_erkannt (CM_KLh_SIH_NTC_defekt_hr_Cx0_Kein_Fehler_erkannt) (Kein Fehler erkannt), 1=Cx1_Unterbrechung (CM_KLh_SIH_NTC_defekt_hr_Cx1_Unterbrechung), 2=Cx2_Kurzschluss_nach_Masse (CM_KLh_SIH_NTC_defekt_hr_Cx2_Kurzschluss_nach_Masse) (Kurzschluss nach Masse)}, range raw 0..2, transfer-property=PENDING, to Klima(timeout 3.5 s)  # Diagnostizierung Temperaturfühler Sitzheizung Heck rechts.
            signal KLh_SIH_Stufe_hl_XIX_KLhs_02_XIX_Klima_LIN4: start 8, 3 bit, little-endian, data-type-policy=OVERRIDE, i-signal-type=PRIMITIVE, base-type=BT_KLh_SIH_Stufe_hl, compu {0=Cx0_Stufe_0 (CM_KLh_SIH_Stufe_hl_Cx0_Stufe_0), 1=Cx1_Stufe_1 (CM_KLh_SIH_Stufe_hl_Cx1_Stufe_1), 2=Cx2_Stufe_2 (CM_KLh_SIH_Stufe_hl_Cx2_Stufe_2), 3=Cx3_Stufe_3 (CM_KLh_SIH_Stufe_hl_Cx3_Stufe_3), 4=Cx4_Stufe_4 (CM_KLh_SIH_Stufe_hl_Cx4_Stufe_4), 5=Cx5_Stufe_5 (CM_KLh_SIH_Stufe_hl_Cx5_Stufe_5), 6=Cx6_Stufe_6 (CM_KLh_SIH_Stufe_hl_Cx6_Stufe_6)}, range raw 0..6, transfer-property=PENDING, to Klima(timeout 3.5 s)  # Aktive Stufe Sitzheizung Heck links, auf deren Basis die Sitzheizungsmatten bestromt werden. Bei dreistufigen Sitzheizungen wird Stufe 0/2/4/6 verwendet.
            signal KLh_SIH_Stufe_hr_XIX_KLhs_02_XIX_Klima_LIN4: start 11, 3 bit, little-endian, data-type-policy=OVERRIDE, i-signal-type=PRIMITIVE, base-type=BT_KLh_SIH_Stufe_hr, compu {0=Cx0_Stufe_0 (CM_KLh_SIH_Stufe_hr_Cx0_Stufe_0), 1=Cx1_Stufe_1 (CM_KLh_SIH_Stufe_hr_Cx1_Stufe_1), 2=Cx2_Stufe_2 (CM_KLh_SIH_Stufe_hr_Cx2_Stufe_2), 3=Cx3_Stufe_3 (CM_KLh_SIH_Stufe_hr_Cx3_Stufe_3), 4=Cx4_Stufe_4 (CM_KLh_SIH_Stufe_hr_Cx4_Stufe_4), 5=Cx5_Stufe_5 (CM_KLh_SIH_Stufe_hr_Cx5_Stufe_5), 6=Cx6_Stufe_6 (CM_KLh_SIH_Stufe_hr_Cx6_Stufe_6)}, range raw 0..6, transfer-property=PENDING, to Klima(timeout 3.5 s)  # Aktive Stufe Sitzheizung Heck rechts, auf deren Basis die Sitzheizungsmatten bestromt werden. Bei dreistufigen Sitzheizungen wird Stufe 0/2/4/6 verwendet.
            signal KL_SL_Soll_hl_XIX_KLhs_02_XIX_Klima_LIN4: start 14, 3 bit, little-endian, data-type-policy=OVERRIDE, i-signal-type=PRIMITIVE, init-value=0, base-type=BT_KL_SL_Soll_hl, compu {0=Cx0_Stufe_0 (CM_KL_SL_Soll_hl_Cx0_Stufe_0), 1=Cx1_Stufe_1 (CM_KL_SL_Soll_hl_Cx1_Stufe_1), 2=Cx2_Stufe_2 (CM_KL_SL_Soll_hl_Cx2_Stufe_2), 3=Cx3_Stufe_3 (CM_KL_SL_Soll_hl_Cx3_Stufe_3), 4=Cx4_Stufe_4 (CM_KL_SL_Soll_hl_Cx4_Stufe_4), 5=Cx5_Stufe_5 (CM_KL_SL_Soll_hl_Cx5_Stufe_5), 6=Cx6_Stufe_6 (CM_KL_SL_Soll_hl_Cx6_Stufe_6)}, range raw 0..6, transfer-property=PENDING, to Klima(timeout 3.5 s)  # Einstellung Sitzlüftung hinten links (0...6)
            signal KL_SL_Soll_hr_XIX_KLhs_02_XIX_Klima_LIN4: start 17, 3 bit, little-endian, data-type-policy=OVERRIDE, i-signal-type=PRIMITIVE, init-value=0, base-type=BT_KL_SL_Soll_hr, compu {0=Cx0_Stufe_0 (CM_KL_SL_Soll_hr_Cx0_Stufe_0), 1=Cx1_Stufe_1 (CM_KL_SL_Soll_hr_Cx1_Stufe_1), 2=Cx2_Stufe_2 (CM_KL_SL_Soll_hr_Cx2_Stufe_2), 3=Cx3_Stufe_3 (CM_KL_SL_Soll_hr_Cx3_Stufe_3), 4=Cx4_Stufe_4 (CM_KL_SL_Soll_hr_Cx4_Stufe_4), 5=Cx5_Stufe_5 (CM_KL_SL_Soll_hr_Cx5_Stufe_5), 6=Cx6_Stufe_6 (CM_KL_SL_Soll_hr_Cx6_Stufe_6)}, range raw 0..6, transfer-property=PENDING, to Klima(timeout 3.5 s)  # Einstellung Sitzlüftung hinten rechts (0...6)
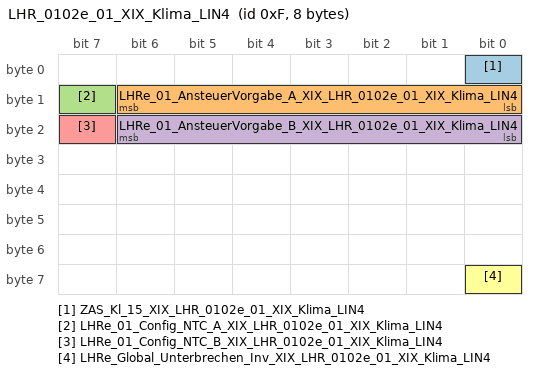
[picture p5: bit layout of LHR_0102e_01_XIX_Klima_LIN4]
        frame LHR_0102e_01_XIX_Klima_LIN4: id 0xF, from Klima, frame-length=8, lin-checksum=ENHANCED
          pdu LHR_0102e_01_XIX_Klima_LIN4: length=8, unused-bit-pattern=0
            signal ZAS_Kl_15_XIX_LHR_0102e_01_XIX_Klima_LIN4: start 0, 1 bit, little-endian, data-type-policy=OVERRIDE, i-signal-type=PRIMITIVE, init-value=0, base-type=BT_ZAS_Kl_15, compu {0=Cx0_aus (CM_ZAS_Kl_15_Cx0_aus), 1=Cx1_ein (CM_ZAS_Kl_15_Cx1_ein)}, range raw 0..1, transfer-property=PENDING  # Klemme 15: Zuendung (SW-Kl.15)
            signal LHRe_01_AnsteuerVorgabe_A_XIX_LHR_0102e_01_XIX_Klima_LIN4: start 8, 7 bit, little-endian, data-type-policy=OVERRIDE, i-signal-type=PRIMITIVE, init-value=0, base-type=BT_LHRe_01_AnsteuerVorgabe_A, invalid-value=Invalid_LHRe_01_AnsteuerVorgabe_A_XIX_LHR_0102e_01_XIX_Klima_LIN4:127, compu {phys=raw for raw 0..100, 101=Cx65_PWM_100Prozent_ohne_U_Kompensat (CM_LHRe_01_AnsteuerVorgabe_A_Cx65_PWM_100Prozent_ohne_U_Kompensat), 110=Cx6e_Stufe_0 (CM_LHRe_01_AnsteuerVorgabe_A_Cx6e_Stufe_0), 111=Cx6f_Stufe_1 (CM_LHRe_01_AnsteuerVorgabe_A_Cx6f_Stufe_1), 112=Cx70_Stufe_2 (CM_LHRe_01_AnsteuerVorgabe_A_Cx70_Stufe_2), 113=Cx71_Stufe_3 (CM_LHRe_01_AnsteuerVorgabe_A_Cx71_Stufe_3), 114=Cx72_Stufe_4 (CM_LHRe_01_AnsteuerVorgabe_A_Cx72_Stufe_4), 115=Cx73_Stufe_5 (CM_LHRe_01_AnsteuerVorgabe_A_Cx73_Stufe_5), 116=Cx74_Stufe_6 (CM_LHRe_01_AnsteuerVorgabe_A_Cx74_Stufe_6), 117=Cx75_Stufe_7 (CM_LHRe_01_AnsteuerVorgabe_A_Cx75_Stufe_7), 118=Cx76_Stufe_8 (CM_LHRe_01_AnsteuerVorgabe_A_Cx76_Stufe_8), 119=Cx77_Stufe_9 (CM_LHRe_01_AnsteuerVorgabe_A_Cx77_Stufe_9), 120=Cx78_Stufe_10 (CM_LHRe_01_AnsteuerVorgabe_A_Cx78_Stufe_10), 127=Cx7f_Fehler (CM_LHRe_01_AnsteuerVorgabe_A_Cx7f_Fehler); unit Unit_PerCent}, range phys 0..100 Unit_PerCent, raw 0..127, unit=Unit_PerCent, transfer-property=PENDING  # Heizvorgabe Kanal A
            signal LHRe_01_Config_NTC_A_XIX_LHR_0102e_01_XIX_Klima_LIN4: start 15, 1 bit, little-endian, data-type-policy=OVERRIDE, i-signal-type=PRIMITIVE, init-value=0, base-type=BT_LHRe_01_Config_NTC_A, compu {0=Cx0_Init_ohne_NTC (CM_LHRe_01_Config_NTC_A_Cx0_Init_ohne_NTC), 1=Cx1_mit_NTC (CM_LHRe_01_Config_NTC_A_Cx1_mit_NTC)}, range raw 0..1, transfer-property=PENDING  # Verbauinformation für NTC a
            signal LHRe_01_AnsteuerVorgabe_B_XIX_LHR_0102e_01_XIX_Klima_LIN4: start 16, 7 bit, little-endian, data-type-policy=OVERRIDE, i-signal-type=PRIMITIVE, init-value=0, base-type=BT_LHRe_01_AnsteuerVorgabe_B, invalid-value=Invalid_LHRe_01_AnsteuerVorgabe_B_XIX_LHR_0102e_01_XIX_Klima_LIN4:127, compu {phys=raw for raw 0..100, 101=Cx65_PWM_100Prozent_ohne_U_Kompensat (CM_LHRe_01_AnsteuerVorgabe_B_Cx65_PWM_100Prozent_ohne_U_Kompensat), 110=Cx6e_Stufe_0 (CM_LHRe_01_AnsteuerVorgabe_B_Cx6e_Stufe_0), 111=Cx6f_Stufe_1 (CM_LHRe_01_AnsteuerVorgabe_B_Cx6f_Stufe_1), 112=Cx70_Stufe_2 (CM_LHRe_01_AnsteuerVorgabe_B_Cx70_Stufe_2), 113=Cx71_Stufe_3 (CM_LHRe_01_AnsteuerVorgabe_B_Cx71_Stufe_3), 114=Cx72_Stufe_4 (CM_LHRe_01_AnsteuerVorgabe_B_Cx72_Stufe_4), 115=Cx73_Stufe_5 (CM_LHRe_01_AnsteuerVorgabe_B_Cx73_Stufe_5), 116=Cx74_Stufe_6 (CM_LHRe_01_AnsteuerVorgabe_B_Cx74_Stufe_6), 117=Cx75_Stufe_7 (CM_LHRe_01_AnsteuerVorgabe_B_Cx75_Stufe_7), 118=Cx76_Stufe_8 (CM_LHRe_01_AnsteuerVorgabe_B_Cx76_Stufe_8), 119=Cx77_Stufe_9 (CM_LHRe_01_AnsteuerVorgabe_B_Cx77_Stufe_9), 120=Cx78_Stufe_10 (CM_LHRe_01_AnsteuerVorgabe_B_Cx78_Stufe_10), 127=Cx7f_Fehler (CM_LHRe_01_AnsteuerVorgabe_B_Cx7f_Fehler); unit Unit_PerCent}, range phys 0..100 Unit_PerCent, raw 0..127, unit=Unit_PerCent, transfer-property=PENDING  # Heizvorgabe Kanal B
            signal LHRe_01_Config_NTC_B_XIX_LHR_0102e_01_XIX_Klima_LIN4: start 23, 1 bit, little-endian, data-type-policy=OVERRIDE, i-signal-type=PRIMITIVE, init-value=0, base-type=BT_LHRe_01_Config_NTC_B, compu {0=Cx0_Init_ohne_NTC (CM_LHRe_01_Config_NTC_B_Cx0_Init_ohne_NTC), 1=Cx1_mit_NTC (CM_LHRe_01_Config_NTC_B_Cx1_mit_NTC)}, range raw 0..1, transfer-property=PENDING  # Verbauinformation für NTC B
            signal LHRe_Global_Unterbrechen_Inv_XIX_LHR_0102e_01_XIX_Klima_LIN4: start 56, 1 bit, little-endian, data-type-policy=OVERRIDE, i-signal-type=PRIMITIVE, init-value=0, base-type=BT_LHRe_Global_Unterbrechen_Inv, compu {0=Cx0_Globale_Unterbrechung (CM_LHRe_Global_Unterbrechen_Inv_Cx0_Globale_Unterbrechung), 1=Cx1_Keine_Unterbrechung_Init (CM_LHRe_Global_Unterbrechen_Inv_Cx1_Keine_Unterbrechung_Init)}, range raw 0..1, transfer-property=PENDING  # Alle LHR-Slaves werden mit diesem Signal über eine temporäre Abschaltung informiert, damit sie so schnell wie möglich abschalten können um die Motor-Wiederstartanforderung zu erfüllen und andere Sofortabschaltungen umzusetzen.
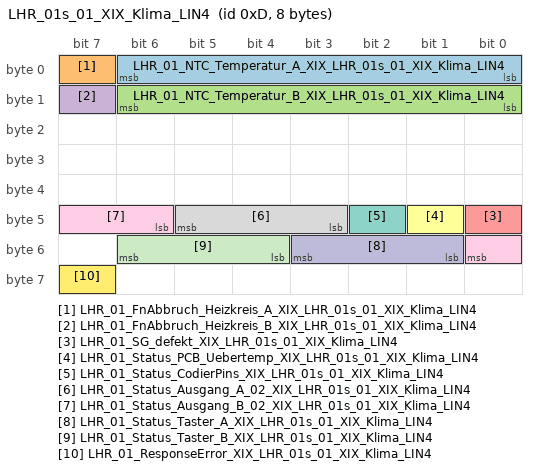
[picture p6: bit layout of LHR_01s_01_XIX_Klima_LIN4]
        frame LHR_01s_01_XIX_Klima_LIN4: id 0xD, to Klima, frame-length=8, lin-checksum=ENHANCED
          pdu LHR_01s_01_XIX_Klima_LIN4: length=8, unused-bit-pattern=0
            signal LHR_01_NTC_Temperatur_A_XIX_LHR_01s_01_XIX_Klima_LIN4: start 0, 7 bit, little-endian, data-type-policy=OVERRIDE, i-signal-type=PRIMITIVE, init-value=125, base-type=BT_LHR_01_NTC_Temperatur_A, compu {phys=raw-40 for raw 0..120, 125=Cx7d_NTC_ungetested_init (CM_LHR_01_NTC_Temperatur_A_Cx7d_NTC_ungetested_init), 126=Cx7e_OpenLoad_Kurzschluss_Plus (CM_LHR_01_NTC_Temperatur_A_Cx7e_OpenLoad_Kurzschluss_Plus), 127=Cx7f_Overload_Kurzschluss_Masse (CM_LHR_01_NTC_Temperatur_A_Cx7f_Overload_Kurzschluss_Masse); unit Unit_DegreCelsi}, range phys -40..80 Unit_DegreCelsi, raw 0..127, unit=Unit_DegreCelsi, transfer-property=PENDING, to Klima(timeout 3.5 s)  # Isttemperatur am NTC A
            signal LHR_01_FnAbbruch_Heizkreis_A_XIX_LHR_01s_01_XIX_Klima_LIN4: start 7, 1 bit, little-endian, data-type-policy=OVERRIDE, i-signal-type=PRIMITIVE, init-value=0, base-type=BT_LHR_01_FnAbbruch_Heizkreis_A, compu {0=Cx0_Init_OK (CM_LHR_01_FnAbbruch_Heizkreis_A_Cx0_Init_OK), 1=Cx1_Funktionsabbruch (CM_LHR_01_FnAbbruch_Heizkreis_A_Cx1_Funktionsabbruch)}, range raw 0..1, transfer-property=PENDING, to Klima(timeout 3.5 s)  # Heizungsregler hat Heizvorgang aufgrund von Fehler abgebrochen (wartet auf Neuinitialisierung)
            signal LHR_01_NTC_Temperatur_B_XIX_LHR_01s_01_XIX_Klima_LIN4: start 8, 7 bit, little-endian, data-type-policy=OVERRIDE, i-signal-type=PRIMITIVE, init-value=125, base-type=BT_LHR_01_NTC_Temperatur_B, compu {phys=raw-40 for raw 0..120, 125=Cx7d_NTC_ungetested_init (CM_LHR_01_NTC_Temperatur_B_Cx7d_NTC_ungetested_init), 126=Cx7e_OpenLoad_Kurzschluss_Plus (CM_LHR_01_NTC_Temperatur_B_Cx7e_OpenLoad_Kurzschluss_Plus), 127=Cx7f_Overload_Kurzschluss_Masse (CM_LHR_01_NTC_Temperatur_B_Cx7f_Overload_Kurzschluss_Masse); unit Unit_DegreCelsi}, range phys -40..80 Unit_DegreCelsi, raw 0..127, unit=Unit_DegreCelsi, transfer-property=PENDING, to Klima(timeout 3.5 s)  # Isttemperatur am NTC B
            signal LHR_01_FnAbbruch_Heizkreis_B_XIX_LHR_01s_01_XIX_Klima_LIN4: start 15, 1 bit, little-endian, data-type-policy=OVERRIDE, i-signal-type=PRIMITIVE, init-value=0, base-type=BT_LHR_01_FnAbbruch_Heizkreis_B, compu {0=Cx0_Init_OK (CM_LHR_01_FnAbbruch_Heizkreis_B_Cx0_Init_OK), 1=Cx1_Funktionsabbruch (CM_LHR_01_FnAbbruch_Heizkreis_B_Cx1_Funktionsabbruch)}, range raw 0..1, transfer-property=PENDING, to Klima(timeout 3.5 s)  # Heizungsregler hat Heizvorgang aufgrund von Fehler abgebrochen (wartet auf Neuinitialisierung)
            signal LHR_01_SG_defekt_XIX_LHR_01s_01_XIX_Klima_LIN4: start 40, 1 bit, little-endian, data-type-policy=OVERRIDE, i-signal-type=PRIMITIVE, init-value=0, base-type=BT_LHR_01_SG_defekt, compu {0=Cx0_Init_OK (CM_LHR_01_SG_defekt_Cx0_Init_OK), 1=Cx1_SG_defekt (CM_LHR_01_SG_defekt_Cx1_SG_defekt)}, range raw 0..1, transfer-property=PENDING, to Klima(timeout 3.5 s)  # Heizungsregler hat irreversiblen defekt
            signal LHR_01_Status_PCB_Uebertemp_XIX_LHR_01s_01_XIX_Klima_LIN4: start 41, 1 bit, little-endian, data-type-policy=OVERRIDE, i-signal-type=PRIMITIVE, init-value=0, base-type=BT_LHR_01_Status_PCB_Uebertemp, compu {0=Cx0_Init_OK (CM_LHR_01_Status_PCB_Uebertemp_Cx0_Init_OK), 1=Cx1_Uebertemperatur (CM_LHR_01_Status_PCB_Uebertemp_Cx1_Uebertemperatur)}, range raw 0..1, transfer-property=PENDING, to Klima(timeout 3.5 s)  # Status der Leiterplattentemperatur
            signal LHR_01_Status_CodierPins_XIX_LHR_01s_01_XIX_Klima_LIN4: start 42, 1 bit, little-endian, data-type-policy=OVERRIDE, i-signal-type=PRIMITIVE, init-value=0, base-type=BT_LHR_01_Status_CodierPins, compu {0=Cx0_Init_OK (CM_LHR_01_Status_CodierPins_Cx0_Init_OK), 1=Cx1_HW_Codierung_Fehler (CM_LHR_01_Status_CodierPins_Cx1_HW_Codierung_Fehler)}, range raw 0..1, transfer-property=PENDING, to Klima(timeout 3.5 s)  # Status der Codierung (Abgleich HW und Softwarecodierung)
            signal LHR_01_Status_Ausgang_A_02_XIX_LHR_01s_01_XIX_Klima_LIN4: start 43, 3 bit, little-endian, data-type-policy=OVERRIDE, i-signal-type=PRIMITIVE, init-value=0, base-type=BT_LHR_01_Status_Ausgang_A_02, compu {0=Cx0_ungetestet (CM_LHR_01_Status_Ausgang_A_02_Cx0_ungetestet), 1=Cx1_Sitzheizung_erkannt (CM_LHR_01_Status_Ausgang_A_02_Cx1_Sitzheizung_erkannt), 2=Cx2_Sitzheizung_nicht_erkannt (CM_LHR_01_Status_Ausgang_A_02_Cx2_Sitzheizung_nicht_erkannt), 3=Cx3_Overload (CM_LHR_01_Status_Ausgang_A_02_Cx3_Overload), 4=Cx4_Openload (CM_LHR_01_Status_Ausgang_A_02_Cx4_Openload)}, range raw 0..4, transfer-property=PENDING, to Klima(timeout 3.5 s)  # Status des Leistungstreibers A. Verbau der Sitzheizung und Kurzschlussprüfung nach Masse oder nach Plus.
            signal LHR_01_Status_Ausgang_B_02_XIX_LHR_01s_01_XIX_Klima_LIN4: start 46, 3 bit, little-endian, data-type-policy=OVERRIDE, i-signal-type=PRIMITIVE, init-value=0, base-type=BT_LHR_01_Status_Ausgang_B_02, compu {0=Cx0_ungetestet (CM_LHR_01_Status_Ausgang_B_02_Cx0_ungetestet), 1=Cx1_Sitzheizung_erkannt (CM_LHR_01_Status_Ausgang_B_02_Cx1_Sitzheizung_erkannt), 2=Cx2_Sitzheizung_nicht_erkannt (CM_LHR_01_Status_Ausgang_B_02_Cx2_Sitzheizung_nicht_erkannt), 3=Cx3_Overload (CM_LHR_01_Status_Ausgang_B_02_Cx3_Overload), 4=Cx4_Openload (CM_LHR_01_Status_Ausgang_B_02_Cx4_Openload)}, range raw 0..4, transfer-property=PENDING, to Klima(timeout 3.5 s)  # Status des Leistungstreibers A. Verbau der Sitzheizung und Kurzschlussprüfung nach Masse oder nach Plus.
            signal LHR_01_Status_Taster_A_XIX_LHR_01s_01_XIX_Klima_LIN4: start 49, 3 bit, little-endian, data-type-policy=OVERRIDE, i-signal-type=PRIMITIVE, init-value=0, base-type=BT_LHR_01_Status_Taster_A, compu {0=Cx0_ungetestet (CM_LHR_01_Status_Taster_A_Cx0_ungetestet), 1=Cx1_Taster_nicht_erkannt (CM_LHR_01_Status_Taster_A_Cx1_Taster_nicht_erkannt), 2=Cx2_Taster_Stufe_0 (CM_LHR_01_Status_Taster_A_Cx2_Taster_Stufe_0), 3=Cx3_Taster_Stufe_1 (CM_LHR_01_Status_Taster_A_Cx3_Taster_Stufe_1), 4=Cx4_Taster_Stufe_2 (CM_LHR_01_Status_Taster_A_Cx4_Taster_Stufe_2), 5=Cx5_Taster_Stufe_3 (CM_LHR_01_Status_Taster_A_Cx5_Taster_Stufe_3)}, range raw 0..5, transfer-property=PENDING, to Klima(timeout 3.5 s)  # Status des Sitzheizungstasters, Kanal A
            signal LHR_01_Status_Taster_B_XIX_LHR_01s_01_XIX_Klima_LIN4: start 52, 3 bit, little-endian, data-type-policy=OVERRIDE, i-signal-type=PRIMITIVE, init-value=0, base-type=BT_LHR_01_Status_Taster_B, compu {0=Cx0_ungetestet (CM_LHR_01_Status_Taster_B_Cx0_ungetestet), 1=Cx1_Taster_nicht_erkannt (CM_LHR_01_Status_Taster_B_Cx1_Taster_nicht_erkannt), 2=Cx2_Taster_Stufe_0 (CM_LHR_01_Status_Taster_B_Cx2_Taster_Stufe_0), 3=Cx3_Taster_Stufe_1 (CM_LHR_01_Status_Taster_B_Cx3_Taster_Stufe_1), 4=Cx4_Taster_Stufe_2 (CM_LHR_01_Status_Taster_B_Cx4_Taster_Stufe_2), 5=Cx5_Taster_Stufe_3 (CM_LHR_01_Status_Taster_B_Cx5_Taster_Stufe_3)}, range raw 0..5, transfer-property=PENDING, to Klima(timeout 3.5 s)  # Status des Sitzheizungstasters, Kanal B
            signal LHR_01_ResponseError_XIX_LHR_01s_01_XIX_Klima_LIN4: start 63, 1 bit, little-endian, data-type-policy=OVERRIDE, i-signal-type=PRIMITIVE, init-value=0, base-type=BT_LHR_01_ResponseError, invalid-value=Invalid_LHR_01_ResponseError_XIX_LHR_01s_01_XIX_Klima_LIN4:1, compu {0=Cx0_normal (CM_LHR_01_ResponseError_Cx0_normal), 1=Cx1_Fehler (CM_LHR_01_ResponseError_Cx1_Fehler)}, range raw 0..1, transfer-property=PENDING, to Klima(timeout 3.5 s)  # siehe LIN2.0-Specification (Darf nicht über ein Fehlergueltigkeitsbit abgesichtert werden!)
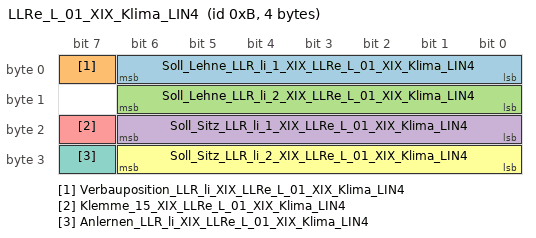
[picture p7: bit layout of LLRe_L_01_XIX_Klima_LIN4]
        frame LLRe_L_01_XIX_Klima_LIN4: id 0xB, from Klima, frame-length=4, lin-checksum=ENHANCED
          pdu LLRe_L_01_XIX_Klima_LIN4: length=4, unused-bit-pattern=0
            signal Soll_Lehne_LLR_li_1_XIX_LLRe_L_01_XIX_Klima_LIN4: start 0, 7 bit, little-endian, data-type-policy=OVERRIDE, i-signal-type=PRIMITIVE, init-value=0, base-type=BT_Soll_Lehne_LLR_li_1, compu {phys=raw for raw 0..100; unit Unit_PerCent}, range phys 0..100 Unit_PerCent, raw 0..100, unit=Unit_PerCent, transfer-property=PENDING  # Ansteuerung Sitzluefter PWM in %
            signal Verbauposition_LLR_li_XIX_LLRe_L_01_XIX_Klima_LIN4: start 7, 1 bit, little-endian, data-type-policy=OVERRIDE, i-signal-type=PRIMITIVE, base-type=BT_Verbauposition_LLR_li, compu {0=Cx0_vorne (CM_Verbauposition_LLR_li_Cx0_vorne), 1=Cx1_hinten (CM_Verbauposition_LLR_li_Cx1_hinten)}, range raw 0..1, transfer-property=PENDING  # Verbauposition vorne/hinten für eindeutige Diagnose/Identifikation. Signal für hinten ist immer 0x1, Signal für vorne ist immer 0x0.
            signal Soll_Lehne_LLR_li_2_XIX_LLRe_L_01_XIX_Klima_LIN4: start 8, 7 bit, little-endian, data-type-policy=OVERRIDE, i-signal-type=PRIMITIVE, init-value=0, base-type=BT_Soll_Lehne_LLR_li_2, compu {phys=raw for raw 0..100; unit Unit_PerCent}, range phys 0..100 Unit_PerCent, raw 0..100, unit=Unit_PerCent, transfer-property=PENDING  # Ansteuerung Sitzluefter PWM in %
            signal Soll_Sitz_LLR_li_1_XIX_LLRe_L_01_XIX_Klima_LIN4: start 16, 7 bit, little-endian, data-type-policy=OVERRIDE, i-signal-type=PRIMITIVE, init-value=0, base-type=BT_Soll_Sitz_LLR_li_1, compu {phys=raw for raw 0..100; unit Unit_PerCent}, range phys 0..100 Unit_PerCent, raw 0..100, unit=Unit_PerCent, transfer-property=PENDING  # Ansteuerung Sitzluefter PWM in %
            signal Klemme_15_XIX_LLRe_L_01_XIX_Klima_LIN4: start 23, 1 bit, little-endian, data-type-policy=OVERRIDE, i-signal-type=PRIMITIVE, init-value=0, base-type=BT_Klemme_15, compu {0=Cx0_Aus (CM_Klemme_15_Cx0_Aus), 1=Cx1_Ein (CM_Klemme_15_Cx1_Ein)}, range raw 0..1, transfer-property=PENDING
            signal Soll_Sitz_LLR_li_2_XIX_LLRe_L_01_XIX_Klima_LIN4: start 24, 7 bit, little-endian, data-type-policy=OVERRIDE, i-signal-type=PRIMITIVE, init-value=0, base-type=BT_Soll_Sitz_LLR_li_2, compu {phys=raw for raw 0..100; unit Unit_PerCent}, range phys 0..100 Unit_PerCent, raw 0..100, unit=Unit_PerCent, transfer-property=PENDING  # Ansteuerung Sitzluefter PWM in %
            signal Anlernen_LLR_li_XIX_LLRe_L_01_XIX_Klima_LIN4: start 31, 1 bit, little-endian, data-type-policy=OVERRIDE, i-signal-type=PRIMITIVE, init-value=0, base-type=BT_Anlernen_LLR_li, compu {0=Cx0_Init (CM_Anlernen_LLR_li_Cx0_Init), 1=Cx1_Adresse_lernen (CM_Anlernen_LLR_li_Cx1_Adresse_lernen)}, range raw 0..1, transfer-property=PENDING  # Triggersignale zum Anlernen der Slave SG abhängig vom CodierPin
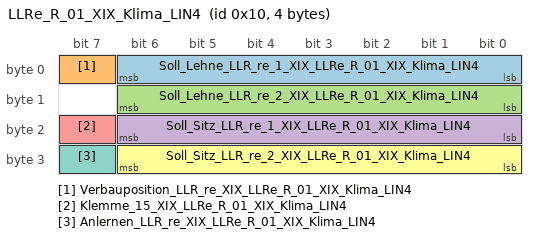
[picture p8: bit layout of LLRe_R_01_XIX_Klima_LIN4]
        frame LLRe_R_01_XIX_Klima_LIN4: id 0x10, from Klima, frame-length=4, lin-checksum=ENHANCED
          pdu LLRe_R_01_XIX_Klima_LIN4: length=4, unused-bit-pattern=0
            signal Soll_Lehne_LLR_re_1_XIX_LLRe_R_01_XIX_Klima_LIN4: start 0, 7 bit, little-endian, data-type-policy=OVERRIDE, i-signal-type=PRIMITIVE, init-value=0, base-type=BT_Soll_Lehne_LLR_re_1, compu {phys=raw for raw 0..100; unit Unit_PerCent}, range phys 0..100 Unit_PerCent, raw 0..100, unit=Unit_PerCent, transfer-property=PENDING  # Ansteuerung Sitzluefter PWM in %
            signal Verbauposition_LLR_re_XIX_LLRe_R_01_XIX_Klima_LIN4: start 7, 1 bit, little-endian, data-type-policy=OVERRIDE, i-signal-type=PRIMITIVE, base-type=BT_Verbauposition_LLR_re, compu {0=Cx0_vorne (CM_Verbauposition_LLR_re_Cx0_vorne), 1=Cx1_hinten (CM_Verbauposition_LLR_re_Cx1_hinten)}, range raw 0..1, transfer-property=PENDING  # Verbauposition vorne/hinten für eindeutige Diagnose/Identifikation. Signal für hinten ist immer 0x1, Signal für vorne ist immer 0x0.
            signal Soll_Lehne_LLR_re_2_XIX_LLRe_R_01_XIX_Klima_LIN4: start 8, 7 bit, little-endian, data-type-policy=OVERRIDE, i-signal-type=PRIMITIVE, init-value=0, base-type=BT_Soll_Lehne_LLR_re_2, compu {phys=raw for raw 0..100; unit Unit_PerCent}, range phys 0..100 Unit_PerCent, raw 0..100, unit=Unit_PerCent, transfer-property=PENDING  # Ansteuerung Sitzluefter PWM in %
            signal Soll_Sitz_LLR_re_1_XIX_LLRe_R_01_XIX_Klima_LIN4: start 16, 7 bit, little-endian, data-type-policy=OVERRIDE, i-signal-type=PRIMITIVE, init-value=0, base-type=BT_Soll_Sitz_LLR_re_1, compu {phys=raw for raw 0..100; unit Unit_PerCent}, range phys 0..100 Unit_PerCent, raw 0..100, unit=Unit_PerCent, transfer-property=PENDING  # Ansteuerung Sitzluefter PWM in %
            signal Klemme_15_XIX_LLRe_R_01_XIX_Klima_LIN4: start 23, 1 bit, little-endian, data-type-policy=OVERRIDE, i-signal-type=PRIMITIVE, init-value=0, base-type=BT_Klemme_15, compu {0=Cx0_Aus (CM_Klemme_15_Cx0_Aus), 1=Cx1_Ein (CM_Klemme_15_Cx1_Ein)}, range raw 0..1, transfer-property=PENDING
            signal Soll_Sitz_LLR_re_2_XIX_LLRe_R_01_XIX_Klima_LIN4: start 24, 7 bit, little-endian, data-type-policy=OVERRIDE, i-signal-type=PRIMITIVE, init-value=0, base-type=BT_Soll_Sitz_LLR_re_2, compu {phys=raw for raw 0..100; unit Unit_PerCent}, range phys 0..100 Unit_PerCent, raw 0..100, unit=Unit_PerCent, transfer-property=PENDING  # Ansteuerung Sitzluefter PWM in %
            signal Anlernen_LLR_re_XIX_LLRe_R_01_XIX_Klima_LIN4: start 31, 1 bit, little-endian, data-type-policy=OVERRIDE, i-signal-type=PRIMITIVE, init-value=0, base-type=BT_Anlernen_LLR_re, compu {0=Cx0_Init (CM_Anlernen_LLR_re_Cx0_Init), 1=Cx1_Adresse_lernen (CM_Anlernen_LLR_re_Cx1_Adresse_lernen)}, range raw 0..1, transfer-property=PENDING  # Triggersignale zum Anlernen der Slave SG abhängig vom CodierPin
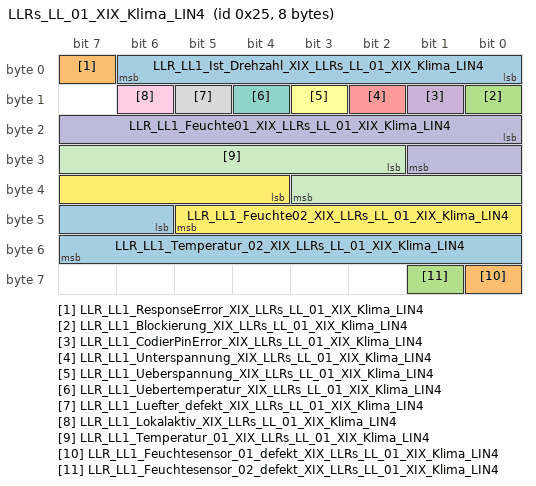
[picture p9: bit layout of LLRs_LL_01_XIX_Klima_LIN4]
        frame LLRs_LL_01_XIX_Klima_LIN4: id 0x25, to Klima, frame-length=8, lin-checksum=ENHANCED
          pdu LLRs_LL_01_XIX_Klima_LIN4: length=8, unused-bit-pattern=0
            signal LLR_LL1_Ist_Drehzahl_XIX_LLRs_LL_01_XIX_Klima_LIN4: start 0, 7 bit, little-endian, data-type-policy=OVERRIDE, i-signal-type=PRIMITIVE, init-value=0, base-type=BT_LLR_LL1_Ist_Drehzahl, compu {phys=raw for raw 0..100; unit Unit_PerCent}, range phys 0..100 Unit_PerCent, raw 0..100, unit=Unit_PerCent, transfer-property=PENDING, to Klima(timeout 3.5 s)  # Fehlende Beschreibung (Import)
            signal LLR_LL1_ResponseError_XIX_LLRs_LL_01_XIX_Klima_LIN4: start 7, 1 bit, little-endian, data-type-policy=OVERRIDE, i-signal-type=PRIMITIVE, init-value=0, base-type=BT_LLR_LL1_ResponseError, invalid-value=Invalid_LLR_LL1_ResponseError_XIX_LLRs_LL_01_XIX_Klima_LIN4:1, compu {0=Cx0_normal (CM_LLR_LL1_ResponseError_Cx0_normal), 1=Cx1_Fehler (CM_LLR_LL1_ResponseError_Cx1_Fehler)}, range raw 0..1, transfer-property=PENDING, to Klima(timeout 3.5 s)  # siehe LIN2.0-Specification (Darf nicht über ein Fehlergueltigkeitsbit abgesichtert werden!)
            signal LLR_LL1_Blockierung_XIX_LLRs_LL_01_XIX_Klima_LIN4: start 8, 1 bit, little-endian, data-type-policy=OVERRIDE, i-signal-type=PRIMITIVE, init-value=0, base-type=BT_LLR_LL1_Blockierung, compu {0=Cx0_kein_Fehler (CM_LLR_LL1_Blockierung_Cx0_kein_Fehler), 1=Cx1_Blockierung_Kompressor_Fehler (CM_LLR_LL1_Blockierung_Cx1_Blockierung_Kompressor_Fehler)}, range raw 0..1, transfer-property=PENDING, to Klima(timeout 3.5 s)  # Blockierung des Lüfters erkannt Geforderte Solldrehzahl kann nicht erreicht werden
            signal LLR_LL1_CodierPinError_XIX_LLRs_LL_01_XIX_Klima_LIN4: start 9, 1 bit, little-endian, data-type-policy=OVERRIDE, i-signal-type=PRIMITIVE, init-value=0, base-type=BT_LLR_LL1_CodierPinError, compu {0=Cx0_kein_Fehler (CM_LLR_LL1_CodierPinError_Cx0_kein_Fehler), 1=Cx1_HW_Codierung_Fehler (CM_LLR_LL1_CodierPinError_Cx1_HW_Codierung_Fehler)}, range raw 0..1, transfer-property=PENDING, to Klima(timeout 3.5 s)  # Fehlende Beschreibung (Import)
            signal LLR_LL1_Unterspannung_XIX_LLRs_LL_01_XIX_Klima_LIN4: start 10, 1 bit, little-endian, data-type-policy=OVERRIDE, i-signal-type=PRIMITIVE, init-value=0, base-type=BT_LLR_LL1_Unterspannung, invalid-value=Invalid_LLR_LL1_Unterspannung_XIX_LLRs_LL_01_XIX_Klima_LIN4:1, compu {0=Cx0_normal (CM_LLR_LL1_Unterspannung_Cx0_normal), 1=Cx1_Fehler (CM_LLR_LL1_Unterspannung_Cx1_Fehler)}, range raw 0..1, transfer-property=PENDING, to Klima(timeout 3.5 s)  # Fehlende Beschreibung (Import)
            signal LLR_LL1_Ueberspannung_XIX_LLRs_LL_01_XIX_Klima_LIN4: start 11, 1 bit, little-endian, data-type-policy=OVERRIDE, i-signal-type=PRIMITIVE, init-value=0, base-type=BT_LLR_LL1_Ueberspannung, invalid-value=Invalid_LLR_LL1_Ueberspannung_XIX_LLRs_LL_01_XIX_Klima_LIN4:1, compu {0=Cx0_normal (CM_LLR_LL1_Ueberspannung_Cx0_normal), 1=Cx1_Fehler (CM_LLR_LL1_Ueberspannung_Cx1_Fehler)}, range raw 0..1, transfer-property=PENDING, to Klima(timeout 3.5 s)  # Fehlende Beschreibung (Import)
            signal LLR_LL1_Uebertemperatur_XIX_LLRs_LL_01_XIX_Klima_LIN4: start 12, 1 bit, little-endian, data-type-policy=OVERRIDE, i-signal-type=PRIMITIVE, init-value=0, base-type=BT_LLR_LL1_Uebertemperatur, invalid-value=Invalid_LLR_LL1_Uebertemperatur_XIX_LLRs_LL_01_XIX_Klima_LIN4:1, compu {0=Cx0_normal (CM_LLR_LL1_Uebertemperatur_Cx0_normal), 1=Cx1_Fehler (CM_LLR_LL1_Uebertemperatur_Cx1_Fehler)}, range raw 0..1, transfer-property=PENDING, to Klima(timeout 3.5 s)  # Fehlende Beschreibung (Import)
            signal LLR_LL1_Luefter_defekt_XIX_LLRs_LL_01_XIX_Klima_LIN4: start 13, 1 bit, little-endian, data-type-policy=OVERRIDE, i-signal-type=PRIMITIVE, init-value=0, base-type=BT_LLR_LL1_Luefter_defekt, compu {0=Cx0_Luefter_iO (CM_LLR_LL1_Luefter_defekt_Cx0_Luefter_iO), 1=Cx1_Luefter_defekt (CM_LLR_LL1_Luefter_defekt_Cx1_Luefter_defekt)}, range raw 0..1, transfer-property=PENDING, to Klima(timeout 3.5 s)  # interner Lüfterdefekt erkannt der zu einem Tausch der BG swingt
            signal LLR_LL1_Lokalaktiv_XIX_LLRs_LL_01_XIX_Klima_LIN4: start 14, 1 bit, little-endian, data-type-policy=OVERRIDE, i-signal-type=PRIMITIVE, init-value=0, base-type=BT_LLR_LL1_Lokalaktiv, compu {0=Cx0_war_nicht_lokal_aktiv (CM_LLR_LL1_Lokalaktiv_Cx0_war_nicht_lokal_aktiv), 1=Cx1_war_lokal_aktiv (CM_LLR_LL1_Lokalaktiv_Cx1_war_lokal_aktiv)}, range raw 0..1, transfer-property=PENDING, to Klima(timeout 3.5 s)  # Lüfter war im letzten Sleepmodus lokal aktiv (Nachtlauffunktion)
            signal LLR_LL1_Feuchte01_XIX_LLRs_LL_01_XIX_Klima_LIN4: start 16, 10 bit, little-endian, data-type-policy=OVERRIDE, i-signal-type=PRIMITIVE, init-value=1022, base-type=BT_LLR_LL1_Feuchte01, invalid-value=Invalid_LLR_LL1_Feuchte01_XIX_LLRs_LL_01_XIX_Klima_LIN4:1023, compu {phys=raw*0.1000000015 for raw 0..1021, 1022=Cx3fe_Init (CM_LLR_LL1_Feuchte01_Cx3fe_Init), 1023=Cx3ff_Fehler (CM_LLR_LL1_Feuchte01_Cx3ff_Fehler); unit Unit_PerCent}, range phys 0..102.10000152140856 Unit_PerCent, raw 0..1023, unit=Unit_PerCent, transfer-property=PENDING, to Klima(timeout 3.5 s)  # Vom Sensor01 gemessene relative Feuchte
            signal LLR_LL1_Temperatur_01_XIX_LLRs_LL_01_XIX_Klima_LIN4: start 26, 10 bit, little-endian, data-type-policy=OVERRIDE, i-signal-type=PRIMITIVE, init-value=1022, base-type=BT_LLR_LL1_Temperatur_01, invalid-value=Invalid_LLR_LL1_Temperatur_01_XIX_LLRs_LL_01_XIX_Klima_LIN4:1023, compu {phys=raw*0.1000000015-40 for raw 0..1019, 1020=Cx3fc_Temperatur_unter_40_C (CM_LLR_LL1_Temperatur_01_Cx3fc_Temperatur_unter_40_C) (Temperatur_unter_-40°C), 1021=Cx3fd_Temperatur_ueber_60_C (CM_LLR_LL1_Temperatur_01_Cx3fd_Temperatur_ueber_60_C) (Temperatur_über_+60°C), 1022=Cx3fe_Init (CM_LLR_LL1_Temperatur_01_Cx3fe_Init), 1023=Cx3ff_Fehler (CM_LLR_LL1_Temperatur_01_Cx3ff_Fehler); unit Unit_DegreCelsi}, range phys -40..61.900001518428326 Unit_DegreCelsi, raw 0..1023, unit=Unit_DegreCelsi, transfer-property=PENDING, to Klima(timeout 3.5 s)  # Vom Sensor01 gemessene Temperatur
            signal LLR_LL1_Feuchte02_XIX_LLRs_LL_01_XIX_Klima_LIN4: start 36, 10 bit, little-endian, data-type-policy=OVERRIDE, i-signal-type=PRIMITIVE, init-value=1022, base-type=BT_LLR_LL1_Feuchte02, invalid-value=Invalid_LLR_LL1_Feuchte02_XIX_LLRs_LL_01_XIX_Klima_LIN4:1023, compu {phys=raw*0.1000000015 for raw 0..1021, 1022=Cx3fe_Init (CM_LLR_LL1_Feuchte02_Cx3fe_Init), 1023=Cx3ff_Fehler (CM_LLR_LL1_Feuchte02_Cx3ff_Fehler); unit Unit_PerCent}, range phys 0..102.10000152140856 Unit_PerCent, raw 0..1023, unit=Unit_PerCent, transfer-property=PENDING, to Klima(timeout 3.5 s)  # Vom Sensor02 gemessene relative Feuchte
            signal LLR_LL1_Temperatur_02_XIX_LLRs_LL_01_XIX_Klima_LIN4: start 46, 10 bit, little-endian, data-type-policy=OVERRIDE, i-signal-type=PRIMITIVE, init-value=1022, base-type=BT_LLR_LL1_Temperatur_02, invalid-value=Invalid_LLR_LL1_Temperatur_02_XIX_LLRs_LL_01_XIX_Klima_LIN4:1023, compu {phys=raw*0.1000000015-40 for raw 0..1019, 1020=Cx3fc_Temperatur_unter_40_C (CM_LLR_LL1_Temperatur_02_Cx3fc_Temperatur_unter_40_C) (Temperatur_unter_-40°C), 1021=Cx3fd_Temperatur_ueber_60_C (CM_LLR_LL1_Temperatur_02_Cx3fd_Temperatur_ueber_60_C) (Temperatur_über_+60°C), 1022=Cx3fe_Init (CM_LLR_LL1_Temperatur_02_Cx3fe_Init), 1023=Cx3ff_Fehler (CM_LLR_LL1_Temperatur_02_Cx3ff_Fehler); unit Unit_DegreCelsi}, range phys -40..61.900001518428326 Unit_DegreCelsi, raw 0..1023, unit=Unit_DegreCelsi, transfer-property=PENDING, to Klima(timeout 3.5 s)  # Vom Sensor02 gemessene Temperatur
            signal LLR_LL1_Feuchtesensor_01_defekt_XIX_LLRs_LL_01_XIX_Klima_LIN4: start 56, 1 bit, little-endian, data-type-policy=OVERRIDE, i-signal-type=PRIMITIVE, init-value=0, base-type=BT_LLR_LL1_Feuchtesensor_01_defekt, compu {0=Cx0_Sensor_iO (CM_LLR_LL1_Feuchtesensor_01_defekt_Cx0_Sensor_iO), 1=Cx1_Sensor_defekt (CM_LLR_LL1_Feuchtesensor_01_defekt_Cx1_Sensor_defekt)}, range raw 0..1, transfer-property=PENDING, to Klima(timeout 3.5 s)  # Fehlfunktion des angeschlossenen externen Feuchtesensors 01 erkannt
            signal LLR_LL1_Feuchtesensor_02_defekt_XIX_LLRs_LL_01_XIX_Klima_LIN4: start 57, 1 bit, little-endian, data-type-policy=OVERRIDE, i-signal-type=PRIMITIVE, init-value=0, base-type=BT_LLR_LL1_Feuchtesensor_02_defekt, compu {0=Cx0_Sensor_iO (CM_LLR_LL1_Feuchtesensor_02_defekt_Cx0_Sensor_iO), 1=Cx1_Sensor_defekt (CM_LLR_LL1_Feuchtesensor_02_defekt_Cx1_Sensor_defekt)}, range raw 0..1, transfer-property=PENDING, to Klima(timeout 3.5 s)  # (Description too short)
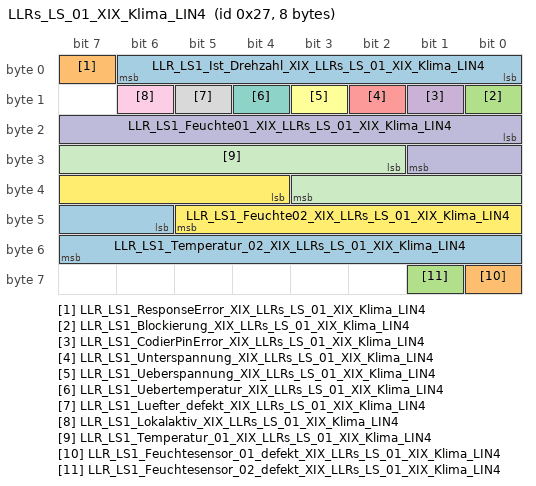
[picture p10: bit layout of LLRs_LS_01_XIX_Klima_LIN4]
        frame LLRs_LS_01_XIX_Klima_LIN4: id 0x27, to Klima, frame-length=8, lin-checksum=ENHANCED
          pdu LLRs_LS_01_XIX_Klima_LIN4: length=8, unused-bit-pattern=0
            signal LLR_LS1_Ist_Drehzahl_XIX_LLRs_LS_01_XIX_Klima_LIN4: start 0, 7 bit, little-endian, data-type-policy=OVERRIDE, i-signal-type=PRIMITIVE, init-value=0, base-type=BT_LLR_LS1_Ist_Drehzahl, compu {phys=raw for raw 0..100; unit Unit_PerCent}, range phys 0..100 Unit_PerCent, raw 0..100, unit=Unit_PerCent, transfer-property=PENDING, to Klima(timeout 3.5 s)  # Aktuelle Istdrehzahl [%] in Bezug auf Maximalwert
            signal LLR_LS1_ResponseError_XIX_LLRs_LS_01_XIX_Klima_LIN4: start 7, 1 bit, little-endian, data-type-policy=OVERRIDE, i-signal-type=PRIMITIVE, init-value=0, base-type=BT_LLR_LS1_ResponseError, invalid-value=Invalid_LLR_LS1_ResponseError_XIX_LLRs_LS_01_XIX_Klima_LIN4:1, compu {0=Cx0_normal (CM_LLR_LS1_ResponseError_Cx0_normal), 1=Cx1_Fehler (CM_LLR_LS1_ResponseError_Cx1_Fehler)}, range raw 0..1, transfer-property=PENDING, to Klima(timeout 3.5 s)  # siehe LIN2.0-Specification (Darf nicht über ein Fehlergueltigkeitsbit abgesichtert werden!)
            signal LLR_LS1_Blockierung_XIX_LLRs_LS_01_XIX_Klima_LIN4: start 8, 1 bit, little-endian, data-type-policy=OVERRIDE, i-signal-type=PRIMITIVE, init-value=0, base-type=BT_LLR_LS1_Blockierung, compu {0=Cx0_kein_Fehler (CM_LLR_LS1_Blockierung_Cx0_kein_Fehler), 1=Cx1_Blockierung_Kompressor_Fehler (CM_LLR_LS1_Blockierung_Cx1_Blockierung_Kompressor_Fehler)}, range raw 0..1, transfer-property=PENDING, to Klima(timeout 3.5 s)  # Fehlende Beschreibung (Import)
            signal LLR_LS1_CodierPinError_XIX_LLRs_LS_01_XIX_Klima_LIN4: start 9, 1 bit, little-endian, data-type-policy=OVERRIDE, i-signal-type=PRIMITIVE, init-value=0, base-type=BT_LLR_LS1_CodierPinError, compu {0=Cx0_kein_Fehler (CM_LLR_LS1_CodierPinError_Cx0_kein_Fehler), 1=Cx1_HW_Codierung_Fehler (CM_LLR_LS1_CodierPinError_Cx1_HW_Codierung_Fehler)}, range raw 0..1, transfer-property=PENDING, to Klima(timeout 3.5 s)  # Fehlende Beschreibung (Import)
            signal LLR_LS1_Unterspannung_XIX_LLRs_LS_01_XIX_Klima_LIN4: start 10, 1 bit, little-endian, data-type-policy=OVERRIDE, i-signal-type=PRIMITIVE, init-value=0, base-type=BT_LLR_LS1_Unterspannung, invalid-value=Invalid_LLR_LS1_Unterspannung_XIX_LLRs_LS_01_XIX_Klima_LIN4:1, compu {0=Cx0_normal (CM_LLR_LS1_Unterspannung_Cx0_normal), 1=Cx1_Fehler (CM_LLR_LS1_Unterspannung_Cx1_Fehler)}, range raw 0..1, transfer-property=PENDING, to Klima(timeout 3.5 s)  # lokal Unterspannung erkannt
            signal LLR_LS1_Ueberspannung_XIX_LLRs_LS_01_XIX_Klima_LIN4: start 11, 1 bit, little-endian, data-type-policy=OVERRIDE, i-signal-type=PRIMITIVE, init-value=0, base-type=BT_LLR_LS1_Ueberspannung, invalid-value=Invalid_LLR_LS1_Ueberspannung_XIX_LLRs_LS_01_XIX_Klima_LIN4:1, compu {0=Cx0_normal (CM_LLR_LS1_Ueberspannung_Cx0_normal), 1=Cx1_Fehler (CM_LLR_LS1_Ueberspannung_Cx1_Fehler)}, range raw 0..1, transfer-property=PENDING, to Klima(timeout 3.5 s)  # Fehlende Beschreibung (Import)
            signal LLR_LS1_Uebertemperatur_XIX_LLRs_LS_01_XIX_Klima_LIN4: start 12, 1 bit, little-endian, data-type-policy=OVERRIDE, i-signal-type=PRIMITIVE, init-value=0, base-type=BT_LLR_LS1_Uebertemperatur, invalid-value=Invalid_LLR_LS1_Uebertemperatur_XIX_LLRs_LS_01_XIX_Klima_LIN4:1, compu {0=Cx0_normal (CM_LLR_LS1_Uebertemperatur_Cx0_normal), 1=Cx1_Fehler (CM_LLR_LS1_Uebertemperatur_Cx1_Fehler)}, range raw 0..1, transfer-property=PENDING, to Klima(timeout 3.5 s)  # intern gemessene Baugruppentemperatur liegt ausserhalb des zulässigen Bereichs
            signal LLR_LS1_Luefter_defekt_XIX_LLRs_LS_01_XIX_Klima_LIN4: start 13, 1 bit, little-endian, data-type-policy=OVERRIDE, i-signal-type=PRIMITIVE, init-value=0, base-type=BT_LLR_LS1_Luefter_defekt, compu {0=Cx0_Luefter_iO (CM_LLR_LS1_Luefter_defekt_Cx0_Luefter_iO), 1=Cx1_Luefter_defekt (CM_LLR_LS1_Luefter_defekt_Cx1_Luefter_defekt)}, range raw 0..1, transfer-property=PENDING, to Klima(timeout 3.5 s)  # interner Lüfterdefekt erkannt der zu einem Tausch der BG swingt
            signal LLR_LS1_Lokalaktiv_XIX_LLRs_LS_01_XIX_Klima_LIN4: start 14, 1 bit, little-endian, data-type-policy=OVERRIDE, i-signal-type=PRIMITIVE, init-value=0, base-type=BT_LLR_LS1_Lokalaktiv, compu {0=Cx0_war_nicht_lokal_aktiv (CM_LLR_LS1_Lokalaktiv_Cx0_war_nicht_lokal_aktiv), 1=Cx1_war_lokal_aktiv (CM_LLR_LS1_Lokalaktiv_Cx1_war_lokal_aktiv)}, range raw 0..1, transfer-property=PENDING, to Klima(timeout 3.5 s)  # Lüfter war im letzten Sleepmodus lokal aktiv (Nachtlauffunktion)
            signal LLR_LS1_Feuchte01_XIX_LLRs_LS_01_XIX_Klima_LIN4: start 16, 10 bit, little-endian, data-type-policy=OVERRIDE, i-signal-type=PRIMITIVE, init-value=1022, base-type=BT_LLR_LS1_Feuchte01, invalid-value=Invalid_LLR_LS1_Feuchte01_XIX_LLRs_LS_01_XIX_Klima_LIN4:1023, compu {phys=raw*0.1000000015 for raw 0..1021, 1022=Cx3fe_Init (CM_LLR_LS1_Feuchte01_Cx3fe_Init), 1023=Cx3ff_Fehler (CM_LLR_LS1_Feuchte01_Cx3ff_Fehler); unit Unit_PerCent}, range phys 0..102.10000152140856 Unit_PerCent, raw 0..1023, unit=Unit_PerCent, transfer-property=PENDING, to Klima(timeout 3.5 s)  # Vom Sensor01 gemessene relative Feuchte
            signal LLR_LS1_Temperatur_01_XIX_LLRs_LS_01_XIX_Klima_LIN4: start 26, 10 bit, little-endian, data-type-policy=OVERRIDE, i-signal-type=PRIMITIVE, init-value=1022, base-type=BT_LLR_LS1_Temperatur_01, invalid-value=Invalid_LLR_LS1_Temperatur_01_XIX_LLRs_LS_01_XIX_Klima_LIN4:1023, compu {phys=raw*0.1000000015-40 for raw 0..1019, 1020=Cx3fc_Temperatur_unter_40_C (CM_LLR_LS1_Temperatur_01_Cx3fc_Temperatur_unter_40_C) (Temperatur_unter_-40°C), 1021=Cx3fd_Temperatur_ueber_60_C (CM_LLR_LS1_Temperatur_01_Cx3fd_Temperatur_ueber_60_C) (Temperatur_über_+60°C), 1022=Cx3fe_Init (CM_LLR_LS1_Temperatur_01_Cx3fe_Init), 1023=Cx3ff_Fehler (CM_LLR_LS1_Temperatur_01_Cx3ff_Fehler); unit Unit_DegreCelsi}, range phys -40..61.900001518428326 Unit_DegreCelsi, raw 0..1023, unit=Unit_DegreCelsi, transfer-property=PENDING, to Klima(timeout 3.5 s)  # Vom Sensor01 gemessene Temperatur
            signal LLR_LS1_Feuchte02_XIX_LLRs_LS_01_XIX_Klima_LIN4: start 36, 10 bit, little-endian, data-type-policy=OVERRIDE, i-signal-type=PRIMITIVE, init-value=1022, base-type=BT_LLR_LS1_Feuchte02, invalid-value=Invalid_LLR_LS1_Feuchte02_XIX_LLRs_LS_01_XIX_Klima_LIN4:1023, compu {phys=raw*0.1000000015 for raw 0..1021, 1022=Cx3fe_Init (CM_LLR_LS1_Feuchte02_Cx3fe_Init), 1023=Cx3ff_Fehler (CM_LLR_LS1_Feuchte02_Cx3ff_Fehler); unit Unit_PerCent}, range phys 0..102.10000152140856 Unit_PerCent, raw 0..1023, unit=Unit_PerCent, transfer-property=PENDING, to Klima(timeout 3.5 s)  # Vom Sensor02 gemessene relative Feuchte
            signal LLR_LS1_Temperatur_02_XIX_LLRs_LS_01_XIX_Klima_LIN4: start 46, 10 bit, little-endian, data-type-policy=OVERRIDE, i-signal-type=PRIMITIVE, init-value=1022, base-type=BT_LLR_LS1_Temperatur_02, invalid-value=Invalid_LLR_LS1_Temperatur_02_XIX_LLRs_LS_01_XIX_Klima_LIN4:1023, compu {phys=raw*0.1000000015-40 for raw 0..1019, 1020=Cx3fc_Temperatur_unter_40_C (CM_LLR_LS1_Temperatur_02_Cx3fc_Temperatur_unter_40_C) (Temperatur_unter_-40°C), 1021=Cx3fd_Temperatur_ueber_60_C (CM_LLR_LS1_Temperatur_02_Cx3fd_Temperatur_ueber_60_C) (Temperatur_über_+60°C), 1022=Cx3fe_Init (CM_LLR_LS1_Temperatur_02_Cx3fe_Init), 1023=Cx3ff_Fehler (CM_LLR_LS1_Temperatur_02_Cx3ff_Fehler); unit Unit_DegreCelsi}, range phys -40..61.900001518428326 Unit_DegreCelsi, raw 0..1023, unit=Unit_DegreCelsi, transfer-property=PENDING, to Klima(timeout 3.5 s)  # Vom Sensor02 gemessene Temperatur
            signal LLR_LS1_Feuchtesensor_01_defekt_XIX_LLRs_LS_01_XIX_Klima_LIN4: start 56, 1 bit, little-endian, data-type-policy=OVERRIDE, i-signal-type=PRIMITIVE, init-value=0, base-type=BT_LLR_LS1_Feuchtesensor_01_defekt, compu {0=Cx0_Sensor_iO (CM_LLR_LS1_Feuchtesensor_01_defekt_Cx0_Sensor_iO), 1=Cx1_Sensor_defekt (CM_LLR_LS1_Feuchtesensor_01_defekt_Cx1_Sensor_defekt)}, range raw 0..1, transfer-property=PENDING, to Klima(timeout 3.5 s)  # Fehlfunktion des angeschlossenen externen Feuchtesensors 01 erkannt
            signal LLR_LS1_Feuchtesensor_02_defekt_XIX_LLRs_LS_01_XIX_Klima_LIN4: start 57, 1 bit, little-endian, data-type-policy=OVERRIDE, i-signal-type=PRIMITIVE, init-value=0, base-type=BT_LLR_LS1_Feuchtesensor_02_defekt, compu {0=Cx0_Sensor_iO (CM_LLR_LS1_Feuchtesensor_02_defekt_Cx0_Sensor_iO), 1=Cx1_Sensor_defekt (CM_LLR_LS1_Feuchtesensor_02_defekt_Cx1_Sensor_defekt)}, range raw 0..1, transfer-property=PENDING, to Klima(timeout 3.5 s)  # Status Feuchtesensor02
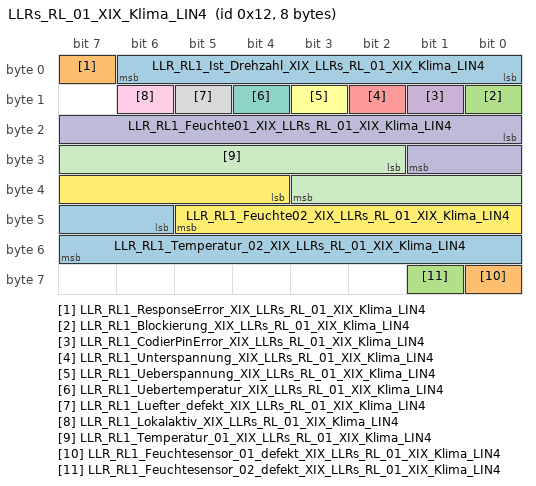
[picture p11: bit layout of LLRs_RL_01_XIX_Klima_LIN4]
        frame LLRs_RL_01_XIX_Klima_LIN4: id 0x12, to Klima, frame-length=8, lin-checksum=ENHANCED
          pdu LLRs_RL_01_XIX_Klima_LIN4: length=8, unused-bit-pattern=0
            signal LLR_RL1_Ist_Drehzahl_XIX_LLRs_RL_01_XIX_Klima_LIN4: start 0, 7 bit, little-endian, data-type-policy=OVERRIDE, i-signal-type=PRIMITIVE, init-value=0, base-type=BT_LLR_RL1_Ist_Drehzahl, compu {phys=raw for raw 0..100; unit Unit_PerCent}, range phys 0..100 Unit_PerCent, raw 0..100, unit=Unit_PerCent, transfer-property=PENDING, to Klima(timeout 3.5 s)  # Aktuelle Istdrehzahl [%] in Bezug auf Maximalwert
            signal LLR_RL1_ResponseError_XIX_LLRs_RL_01_XIX_Klima_LIN4: start 7, 1 bit, little-endian, data-type-policy=OVERRIDE, i-signal-type=PRIMITIVE, init-value=0, base-type=BT_LLR_RL1_ResponseError, invalid-value=Invalid_LLR_RL1_ResponseError_XIX_LLRs_RL_01_XIX_Klima_LIN4:1, compu {0=Cx0_normal (CM_LLR_RL1_ResponseError_Cx0_normal), 1=Cx1_Fehler (CM_LLR_RL1_ResponseError_Cx1_Fehler)}, range raw 0..1, transfer-property=PENDING, to Klima(timeout 3.5 s)  # siehe LIN2.0-Specification (Darf nicht über ein Fehlergueltigkeitsbit abgesichtert werden!)
            signal LLR_RL1_Blockierung_XIX_LLRs_RL_01_XIX_Klima_LIN4: start 8, 1 bit, little-endian, data-type-policy=OVERRIDE, i-signal-type=PRIMITIVE, init-value=0, base-type=BT_LLR_RL1_Blockierung, compu {0=Cx0_kein_Fehler (CM_LLR_RL1_Blockierung_Cx0_kein_Fehler), 1=Cx1_Blockierung_Kompressor_Fehler (CM_LLR_RL1_Blockierung_Cx1_Blockierung_Kompressor_Fehler)}, range raw 0..1, transfer-property=PENDING, to Klima(timeout 3.5 s)  # Blockierung des Lüfters erkannt Geforderte Solldrehzahl kann nicht erreicht werden
            signal LLR_RL1_CodierPinError_XIX_LLRs_RL_01_XIX_Klima_LIN4: start 9, 1 bit, little-endian, data-type-policy=OVERRIDE, i-signal-type=PRIMITIVE, init-value=0, base-type=BT_LLR_RL1_CodierPinError, compu {0=Cx0_kein_Fehler (CM_LLR_RL1_CodierPinError_Cx0_kein_Fehler), 1=Cx1_HW_Codierung_Fehler (CM_LLR_RL1_CodierPinError_Cx1_HW_Codierung_Fehler)}, range raw 0..1, transfer-property=PENDING, to Klima(timeout 3.5 s)  # Die eingelesene Leitungssatzkodierung entspricht nicht dem abgespeicherten Sollwert
            signal LLR_RL1_Unterspannung_XIX_LLRs_RL_01_XIX_Klima_LIN4: start 10, 1 bit, little-endian, data-type-policy=OVERRIDE, i-signal-type=PRIMITIVE, init-value=0, base-type=BT_LLR_RL1_Unterspannung, invalid-value=Invalid_LLR_RL1_Unterspannung_XIX_LLRs_RL_01_XIX_Klima_LIN4:1, compu {0=Cx0_normal (CM_LLR_RL1_Unterspannung_Cx0_normal), 1=Cx1_Fehler (CM_LLR_RL1_Unterspannung_Cx1_Fehler)}, range raw 0..1, transfer-property=PENDING, to Klima(timeout 3.5 s)  # Fehlende Beschreibung (Import)
            signal LLR_RL1_Ueberspannung_XIX_LLRs_RL_01_XIX_Klima_LIN4: start 11, 1 bit, little-endian, data-type-policy=OVERRIDE, i-signal-type=PRIMITIVE, init-value=0, base-type=BT_LLR_RL1_Ueberspannung, invalid-value=Invalid_LLR_RL1_Ueberspannung_XIX_LLRs_RL_01_XIX_Klima_LIN4:1, compu {0=Cx0_normal (CM_LLR_RL1_Ueberspannung_Cx0_normal), 1=Cx1_Fehler (CM_LLR_RL1_Ueberspannung_Cx1_Fehler)}, range raw 0..1, transfer-property=PENDING, to Klima(timeout 3.5 s)  # lokal Überspannung erkannt
            signal LLR_RL1_Uebertemperatur_XIX_LLRs_RL_01_XIX_Klima_LIN4: start 12, 1 bit, little-endian, data-type-policy=OVERRIDE, i-signal-type=PRIMITIVE, init-value=0, base-type=BT_LLR_RL1_Uebertemperatur, invalid-value=Invalid_LLR_RL1_Uebertemperatur_XIX_LLRs_RL_01_XIX_Klima_LIN4:1, compu {0=Cx0_normal (CM_LLR_RL1_Uebertemperatur_Cx0_normal), 1=Cx1_Fehler (CM_LLR_RL1_Uebertemperatur_Cx1_Fehler)}, range raw 0..1, transfer-property=PENDING, to Klima(timeout 3.5 s)  # intern gemessene Baugruppentemperatur liegt ausserhalb des zulässigen Bereichs
            signal LLR_RL1_Luefter_defekt_XIX_LLRs_RL_01_XIX_Klima_LIN4: start 13, 1 bit, little-endian, data-type-policy=OVERRIDE, i-signal-type=PRIMITIVE, init-value=0, base-type=BT_LLR_RL1_Luefter_defekt, compu {0=Cx0_Luefter_iO (CM_LLR_RL1_Luefter_defekt_Cx0_Luefter_iO), 1=Cx1_Luefter_defekt (CM_LLR_RL1_Luefter_defekt_Cx1_Luefter_defekt)}, range raw 0..1, transfer-property=PENDING, to Klima(timeout 3.5 s)  # interner Lüfterdefekt erkannt der zu einem Tausch der BG swingt
            signal LLR_RL1_Lokalaktiv_XIX_LLRs_RL_01_XIX_Klima_LIN4: start 14, 1 bit, little-endian, data-type-policy=OVERRIDE, i-signal-type=PRIMITIVE, init-value=0, base-type=BT_LLR_RL1_Lokalaktiv, compu {0=Cx0_war_nicht_lokal_aktiv (CM_LLR_RL1_Lokalaktiv_Cx0_war_nicht_lokal_aktiv), 1=Cx1_war_lokal_aktiv (CM_LLR_RL1_Lokalaktiv_Cx1_war_lokal_aktiv)}, range raw 0..1, transfer-property=PENDING, to Klima(timeout 3.5 s)  # Lüfter war im letzten Sleepmodus lokal aktiv (Nachtlauffunktion)
            signal LLR_RL1_Feuchte01_XIX_LLRs_RL_01_XIX_Klima_LIN4: start 16, 10 bit, little-endian, data-type-policy=OVERRIDE, i-signal-type=PRIMITIVE, init-value=1022, base-type=BT_LLR_RL1_Feuchte01, invalid-value=Invalid_LLR_RL1_Feuchte01_XIX_LLRs_RL_01_XIX_Klima_LIN4:1023, compu {phys=raw*0.1000000015 for raw 0..1021, 1022=Cx3fe_Init (CM_LLR_RL1_Feuchte01_Cx3fe_Init), 1023=Cx3ff_Fehler (CM_LLR_RL1_Feuchte01_Cx3ff_Fehler); unit Unit_PerCent}, range phys 0..102.10000152140856 Unit_PerCent, raw 0..1023, unit=Unit_PerCent, transfer-property=PENDING, to Klima(timeout 3.5 s)  # Vom Sensor01 gemessene relative Feuchte
            signal LLR_RL1_Temperatur_01_XIX_LLRs_RL_01_XIX_Klima_LIN4: start 26, 10 bit, little-endian, data-type-policy=OVERRIDE, i-signal-type=PRIMITIVE, init-value=1022, base-type=BT_LLR_RL1_Temperatur_01, invalid-value=Invalid_LLR_RL1_Temperatur_01_XIX_LLRs_RL_01_XIX_Klima_LIN4:1023, compu {phys=raw*0.1000000015-40 for raw 0..1019, 1020=Cx3fc_Temperatur_unter_40_C (CM_LLR_RL1_Temperatur_01_Cx3fc_Temperatur_unter_40_C) (Temperatur_unter_-40°C), 1021=Cx3fd_Temperatur_ueber_60_C (CM_LLR_RL1_Temperatur_01_Cx3fd_Temperatur_ueber_60_C) (Temperatur_über_+60°C), 1022=Cx3fe_Init (CM_LLR_RL1_Temperatur_01_Cx3fe_Init), 1023=Cx3ff_Fehler (CM_LLR_RL1_Temperatur_01_Cx3ff_Fehler); unit Unit_DegreCelsi}, range phys -40..61.900001518428326 Unit_DegreCelsi, raw 0..1023, unit=Unit_DegreCelsi, transfer-property=PENDING, to Klima(timeout 3.5 s)  # Vom Sensor01 gemessene Temperatur
            signal LLR_RL1_Feuchte02_XIX_LLRs_RL_01_XIX_Klima_LIN4: start 36, 10 bit, little-endian, data-type-policy=OVERRIDE, i-signal-type=PRIMITIVE, init-value=1022, base-type=BT_LLR_RL1_Feuchte02, invalid-value=Invalid_LLR_RL1_Feuchte02_XIX_LLRs_RL_01_XIX_Klima_LIN4:1023, compu {phys=raw*0.1000000015 for raw 0..1021, 1022=Cx3fe_Init (CM_LLR_RL1_Feuchte02_Cx3fe_Init), 1023=Cx3ff_Fehler (CM_LLR_RL1_Feuchte02_Cx3ff_Fehler); unit Unit_PerCent}, range phys 0..102.10000152140856 Unit_PerCent, raw 0..1023, unit=Unit_PerCent, transfer-property=PENDING, to Klima(timeout 3.5 s)  # Vom Sensor02 gemessene relative Feuchte
            signal LLR_RL1_Temperatur_02_XIX_LLRs_RL_01_XIX_Klima_LIN4: start 46, 10 bit, little-endian, data-type-policy=OVERRIDE, i-signal-type=PRIMITIVE, init-value=1022, base-type=BT_LLR_RL1_Temperatur_02, invalid-value=Invalid_LLR_RL1_Temperatur_02_XIX_LLRs_RL_01_XIX_Klima_LIN4:1023, compu {phys=raw*0.1000000015-40 for raw 0..1019, 1020=Cx3fc_Temperatur_unter_40_C (CM_LLR_RL1_Temperatur_02_Cx3fc_Temperatur_unter_40_C) (Temperatur_unter_-40°C), 1021=Cx3fd_Temperatur_ueber_60_C (CM_LLR_RL1_Temperatur_02_Cx3fd_Temperatur_ueber_60_C) (Temperatur_über_+60°C), 1022=Cx3fe_Init (CM_LLR_RL1_Temperatur_02_Cx3fe_Init), 1023=Cx3ff_Fehler (CM_LLR_RL1_Temperatur_02_Cx3ff_Fehler); unit Unit_DegreCelsi}, range phys -40..61.900001518428326 Unit_DegreCelsi, raw 0..1023, unit=Unit_DegreCelsi, transfer-property=PENDING, to Klima(timeout 3.5 s)  # Vom Sensor02 gemessene Temperatur
            signal LLR_RL1_Feuchtesensor_01_defekt_XIX_LLRs_RL_01_XIX_Klima_LIN4: start 56, 1 bit, little-endian, data-type-policy=OVERRIDE, i-signal-type=PRIMITIVE, init-value=0, base-type=BT_LLR_RL1_Feuchtesensor_01_defekt, compu {0=Cx0_Sensor_iO (CM_LLR_RL1_Feuchtesensor_01_defekt_Cx0_Sensor_iO), 1=Cx1_Sensor_defekt (CM_LLR_RL1_Feuchtesensor_01_defekt_Cx1_Sensor_defekt)}, range raw 0..1, transfer-property=PENDING, to Klima(timeout 3.5 s)  # Fehlfunktion des angeschlossenen externen Feuchtesensors 01 erkannt
            signal LLR_RL1_Feuchtesensor_02_defekt_XIX_LLRs_RL_01_XIX_Klima_LIN4: start 57, 1 bit, little-endian, data-type-policy=OVERRIDE, i-signal-type=PRIMITIVE, init-value=0, base-type=BT_LLR_RL1_Feuchtesensor_02_defekt, compu {0=Cx0_Sensor_iO (CM_LLR_RL1_Feuchtesensor_02_defekt_Cx0_Sensor_iO), 1=Cx1_Sensor_defekt (CM_LLR_RL1_Feuchtesensor_02_defekt_Cx1_Sensor_defekt)}, range raw 0..1, transfer-property=PENDING, to Klima(timeout 3.5 s)  # Status Feuchtesensor02
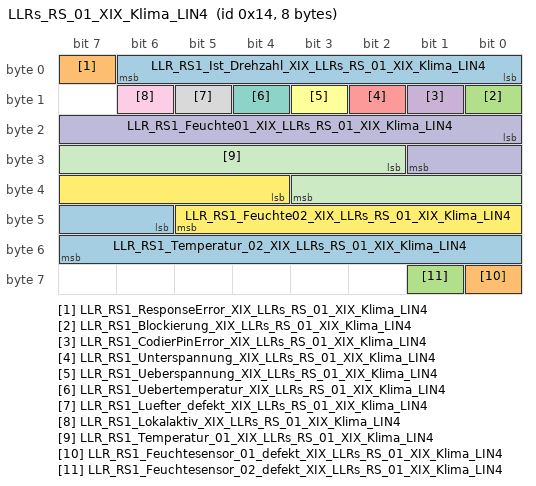
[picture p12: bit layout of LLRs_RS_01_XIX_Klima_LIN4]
        frame LLRs_RS_01_XIX_Klima_LIN4: id 0x14, to Klima, frame-length=8, lin-checksum=ENHANCED
          pdu LLRs_RS_01_XIX_Klima_LIN4: length=8, unused-bit-pattern=0
            signal LLR_RS1_Ist_Drehzahl_XIX_LLRs_RS_01_XIX_Klima_LIN4: start 0, 7 bit, little-endian, data-type-policy=OVERRIDE, i-signal-type=PRIMITIVE, init-value=0, base-type=BT_LLR_RS1_Ist_Drehzahl, compu {phys=raw for raw 0..100; unit Unit_PerCent}, range phys 0..100 Unit_PerCent, raw 0..100, unit=Unit_PerCent, transfer-property=PENDING, to Klima(timeout 3.5 s)  # Aktuelle Istdrehzahl [%] in Bezug auf Maximalwert
            signal LLR_RS1_ResponseError_XIX_LLRs_RS_01_XIX_Klima_LIN4: start 7, 1 bit, little-endian, data-type-policy=OVERRIDE, i-signal-type=PRIMITIVE, init-value=0, base-type=BT_LLR_RS1_ResponseError, invalid-value=Invalid_LLR_RS1_ResponseError_XIX_LLRs_RS_01_XIX_Klima_LIN4:1, compu {0=Cx0_normal (CM_LLR_RS1_ResponseError_Cx0_normal), 1=Cx1_Fehler (CM_LLR_RS1_ResponseError_Cx1_Fehler)}, range raw 0..1, transfer-property=PENDING, to Klima(timeout 3.5 s)  # siehe LIN2.0-Specification (Darf nicht über ein Fehlergueltigkeitsbit abgesichtert werden!)
            signal LLR_RS1_Blockierung_XIX_LLRs_RS_01_XIX_Klima_LIN4: start 8, 1 bit, little-endian, data-type-policy=OVERRIDE, i-signal-type=PRIMITIVE, init-value=0, base-type=BT_LLR_RS1_Blockierung, compu {0=Cx0_kein_Fehler (CM_LLR_RS1_Blockierung_Cx0_kein_Fehler), 1=Cx1_Blockierung_Kompressor_Fehler (CM_LLR_RS1_Blockierung_Cx1_Blockierung_Kompressor_Fehler)}, range raw 0..1, transfer-property=PENDING, to Klima(timeout 3.5 s)  # Blockierung des Lüfters erkannt Geforderte Solldrehzahl kann nicht erreicht werden
            signal LLR_RS1_CodierPinError_XIX_LLRs_RS_01_XIX_Klima_LIN4: start 9, 1 bit, little-endian, data-type-policy=OVERRIDE, i-signal-type=PRIMITIVE, init-value=0, base-type=BT_LLR_RS1_CodierPinError, compu {0=Cx0_kein_Fehler (CM_LLR_RS1_CodierPinError_Cx0_kein_Fehler), 1=Cx1_HW_Codierung_Fehler (CM_LLR_RS1_CodierPinError_Cx1_HW_Codierung_Fehler)}, range raw 0..1, transfer-property=PENDING, to Klima(timeout 3.5 s)  # Die eingelesene Leitungssatzkodierung entspricht nicht dem abgespeicherten Sollwert
            signal LLR_RS1_Unterspannung_XIX_LLRs_RS_01_XIX_Klima_LIN4: start 10, 1 bit, little-endian, data-type-policy=OVERRIDE, i-signal-type=PRIMITIVE, init-value=0, base-type=BT_LLR_RS1_Unterspannung, invalid-value=Invalid_LLR_RS1_Unterspannung_XIX_LLRs_RS_01_XIX_Klima_LIN4:1, compu {0=Cx0_normal (CM_LLR_RS1_Unterspannung_Cx0_normal), 1=Cx1_Fehler (CM_LLR_RS1_Unterspannung_Cx1_Fehler)}, range raw 0..1, transfer-property=PENDING, to Klima(timeout 3.5 s)  # lokal Unterspannung erkannt
            signal LLR_RS1_Ueberspannung_XIX_LLRs_RS_01_XIX_Klima_LIN4: start 11, 1 bit, little-endian, data-type-policy=OVERRIDE, i-signal-type=PRIMITIVE, init-value=0, base-type=BT_LLR_RS1_Ueberspannung, invalid-value=Invalid_LLR_RS1_Ueberspannung_XIX_LLRs_RS_01_XIX_Klima_LIN4:1, compu {0=Cx0_normal (CM_LLR_RS1_Ueberspannung_Cx0_normal), 1=Cx1_Fehler (CM_LLR_RS1_Ueberspannung_Cx1_Fehler)}, range raw 0..1, transfer-property=PENDING, to Klima(timeout 3.5 s)  # lokal Überspannung erkannt
            signal LLR_RS1_Uebertemperatur_XIX_LLRs_RS_01_XIX_Klima_LIN4: start 12, 1 bit, little-endian, data-type-policy=OVERRIDE, i-signal-type=PRIMITIVE, init-value=0, base-type=BT_LLR_RS1_Uebertemperatur, invalid-value=Invalid_LLR_RS1_Uebertemperatur_XIX_LLRs_RS_01_XIX_Klima_LIN4:1, compu {0=Cx0_normal (CM_LLR_RS1_Uebertemperatur_Cx0_normal), 1=Cx1_Fehler (CM_LLR_RS1_Uebertemperatur_Cx1_Fehler)}, range raw 0..1, transfer-property=PENDING, to Klima(timeout 3.5 s)  # intern gemessene Baugruppentemperatur liegt ausserhalb des zulässigen Bereichs
            signal LLR_RS1_Luefter_defekt_XIX_LLRs_RS_01_XIX_Klima_LIN4: start 13, 1 bit, little-endian, data-type-policy=OVERRIDE, i-signal-type=PRIMITIVE, init-value=0, base-type=BT_LLR_RS1_Luefter_defekt, compu {0=Cx0_Luefter_iO (CM_LLR_RS1_Luefter_defekt_Cx0_Luefter_iO), 1=Cx1_Luefter_defekt (CM_LLR_RS1_Luefter_defekt_Cx1_Luefter_defekt)}, range raw 0..1, transfer-property=PENDING, to Klima(timeout 3.5 s)  # interner Lüfterdefekt erkannt der zu einem Tausch der BG swingt
            signal LLR_RS1_Lokalaktiv_XIX_LLRs_RS_01_XIX_Klima_LIN4: start 14, 1 bit, little-endian, data-type-policy=OVERRIDE, i-signal-type=PRIMITIVE, init-value=0, base-type=BT_LLR_RS1_Lokalaktiv, compu {0=Cx0_war_nicht_lokal_aktiv (CM_LLR_RS1_Lokalaktiv_Cx0_war_nicht_lokal_aktiv), 1=Cx1_war_lokal_aktiv (CM_LLR_RS1_Lokalaktiv_Cx1_war_lokal_aktiv)}, range raw 0..1, transfer-property=PENDING, to Klima(timeout 3.5 s)  # Lüfter war im letzten Sleepmodus lokal aktiv (Nachtlauffunktion)
            signal LLR_RS1_Feuchte01_XIX_LLRs_RS_01_XIX_Klima_LIN4: start 16, 10 bit, little-endian, data-type-policy=OVERRIDE, i-signal-type=PRIMITIVE, init-value=1022, base-type=BT_LLR_RS1_Feuchte01, invalid-value=Invalid_LLR_RS1_Feuchte01_XIX_LLRs_RS_01_XIX_Klima_LIN4:1023, compu {phys=raw*0.1000000015 for raw 0..1021, 1022=Cx3fe_Init (CM_LLR_RS1_Feuchte01_Cx3fe_Init), 1023=Cx3ff_Fehler (CM_LLR_RS1_Feuchte01_Cx3ff_Fehler); unit Unit_PerCent}, range phys 0..102.10000152140856 Unit_PerCent, raw 0..1023, unit=Unit_PerCent, transfer-property=PENDING, to Klima(timeout 3.5 s)  # Vom Sensor01 gemessene relative Feuchte
            signal LLR_RS1_Temperatur_01_XIX_LLRs_RS_01_XIX_Klima_LIN4: start 26, 10 bit, little-endian, data-type-policy=OVERRIDE, i-signal-type=PRIMITIVE, init-value=1022, base-type=BT_LLR_RS1_Temperatur_01, invalid-value=Invalid_LLR_RS1_Temperatur_01_XIX_LLRs_RS_01_XIX_Klima_LIN4:1023, compu {phys=raw*0.1000000015-40 for raw 0..1019, 1020=Cx3fc_Temperatur_unter_40_C (CM_LLR_RS1_Temperatur_01_Cx3fc_Temperatur_unter_40_C) (Temperatur unter -40°C), 1021=Cx3fd_Temperatur_ueber_60_C (CM_LLR_RS1_Temperatur_01_Cx3fd_Temperatur_ueber_60_C) (Temperatur über +60°C), 1022=Cx3fe_Init (CM_LLR_RS1_Temperatur_01_Cx3fe_Init), 1023=Cx3ff_Fehler (CM_LLR_RS1_Temperatur_01_Cx3ff_Fehler); unit Unit_DegreCelsi}, range phys -40..61.900001518428326 Unit_DegreCelsi, raw 0..1023, unit=Unit_DegreCelsi, transfer-property=PENDING, to Klima(timeout 3.5 s)  # Vom Sensor01 gemessene Temperatur
            signal LLR_RS1_Feuchte02_XIX_LLRs_RS_01_XIX_Klima_LIN4: start 36, 10 bit, little-endian, data-type-policy=OVERRIDE, i-signal-type=PRIMITIVE, init-value=1022, base-type=BT_LLR_RS1_Feuchte02, invalid-value=Invalid_LLR_RS1_Feuchte02_XIX_LLRs_RS_01_XIX_Klima_LIN4:1023, compu {phys=raw*0.1000000015 for raw 0..1021, 1022=Cx3fe_Init (CM_LLR_RS1_Feuchte02_Cx3fe_Init), 1023=Cx3ff_Fehler (CM_LLR_RS1_Feuchte02_Cx3ff_Fehler); unit Unit_PerCent}, range phys 0..102.10000152140856 Unit_PerCent, raw 0..1023, unit=Unit_PerCent, transfer-property=PENDING, to Klima(timeout 3.5 s)  # Vom Sensor02 gemessene relative Feuchte
            signal LLR_RS1_Temperatur_02_XIX_LLRs_RS_01_XIX_Klima_LIN4: start 46, 10 bit, little-endian, data-type-policy=OVERRIDE, i-signal-type=PRIMITIVE, init-value=1022, base-type=BT_LLR_RS1_Temperatur_02, compu {phys=raw*0.1000000015-40 for raw 0..1019, 1020=Cx3fc_Temperatur_unter_minus_40_Grad_C (CM_LLR_RS1_Temperatur_02_Cx3fc_Temperatur_unter_minus_40_Grad_C), 1021=Cx3fd_Temperatur_ueber_plus_60_Grad_C (CM_LLR_RS1_Temperatur_02_Cx3fd_Temperatur_ueber_plus_60_Grad_C), 1022=Cx3fe_Init (CM_LLR_RS1_Temperatur_02_Cx3fe_Init); unit Unit_DegreCelsi}, range phys -40..61.900001518428326 Unit_DegreCelsi, raw 0..1022, unit=Unit_DegreCelsi, transfer-property=PENDING, to Klima(timeout 3.5 s)  # Vom Sensor02 gemessene Temperatur
            signal LLR_RS1_Feuchtesensor_01_defekt_XIX_LLRs_RS_01_XIX_Klima_LIN4: start 56, 1 bit, little-endian, data-type-policy=OVERRIDE, i-signal-type=PRIMITIVE, init-value=0, base-type=BT_LLR_RS1_Feuchtesensor_01_defekt, compu {0=Cx0_Sensor_iO (CM_LLR_RS1_Feuchtesensor_01_defekt_Cx0_Sensor_iO), 1=Cx1_Sensor_defekt (CM_LLR_RS1_Feuchtesensor_01_defekt_Cx1_Sensor_defekt)}, range raw 0..1, transfer-property=PENDING, to Klima(timeout 3.5 s)  # Status Feuchtesensor01
            signal LLR_RS1_Feuchtesensor_02_defekt_XIX_LLRs_RS_01_XIX_Klima_LIN4: start 57, 1 bit, little-endian, data-type-policy=OVERRIDE, i-signal-type=PRIMITIVE, init-value=0, base-type=BT_LLR_RS1_Feuchtesensor_02_defekt, compu {0=Cx0_Sensor_iO (CM_LLR_RS1_Feuchtesensor_02_defekt_Cx0_Sensor_iO), 1=Cx1_Sensor_defekt (CM_LLR_RS1_Feuchtesensor_02_defekt_Cx1_Sensor_defekt)}, range raw 0..1, transfer-property=PENDING, to Klima(timeout 3.5 s)  # Status Feuchtesensor02
        frame MasterReq_XIX_Klima_LIN4: id 0x3C, from Klima, frame-length=8, lin-checksum=CLASSIC
          n pdu MasterReq_XIX_Klima_LIN4: length=8
        frame SlaveResp_XIX_Klima_LIN4: id 0x3D, to Klima, frame-length=8, lin-checksum=CLASSIC
          n pdu SlaveResp_XIX_Klima_LIN4: length=8
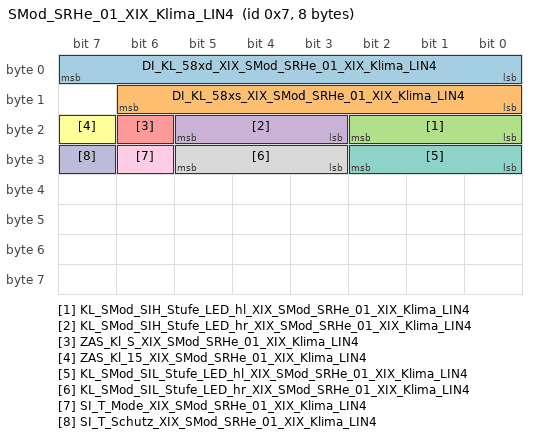
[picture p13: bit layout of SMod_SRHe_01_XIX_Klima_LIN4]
        frame SMod_SRHe_01_XIX_Klima_LIN4: id 0x7, from Klima, frame-length=8, lin-checksum=ENHANCED
          pdu SMod_SRHe_01_XIX_Klima_LIN4: length=8, unused-bit-pattern=0
            signal DI_KL_58xd_XIX_SMod_SRHe_01_XIX_Klima_LIN4: start 0, 8 bit, little-endian, data-type-policy=OVERRIDE, i-signal-type=PRIMITIVE, init-value=254, base-type=BT_DI_KL_58xd, invalid-value=Invalid_DI_KL_58xd_XIX_SMod_SRHe_01_XIX_Klima_LIN4:255, compu {phys=raw for raw 0..253, 254=Cxfe_Init (CM_DI_KL_58xd_Cxfe_Init), 255=Cxff_Fehler (CM_DI_KL_58xd_Cxff_Fehler)}, range phys 0..253, raw 0..255, transfer-property=PENDING  # Klemme 58xd Display- und Funktionsbeleuchtung Mit der Klemme 58xd wird die Helligkeit der Display- und der Funktionsbeleuchtungen der Schalter gesteuert. Im Detail beschrieben im 'Funktionslastenheft Dimmung MQB'.
            signal DI_KL_58xs_XIX_SMod_SRHe_01_XIX_Klima_LIN4: start 8, 7 bit, little-endian, data-type-policy=OVERRIDE, i-signal-type=PRIMITIVE, init-value=126, base-type=BT_DI_KL_58xs, invalid-value=Invalid_DI_KL_58xs_XIX_SMod_SRHe_01_XIX_Klima_LIN4:127, compu {phys=raw for raw 0..100, 126=Cx7e_Init (CM_DI_KL_58xs_Cx7e_Init), 127=Cx7f_Fehler (CM_DI_KL_58xs_Cx7f_Fehler); unit Unit_PerCent}, range phys 0..100 Unit_PerCent, raw 0..127, unit=Unit_PerCent, transfer-property=PENDING  # Suchbeleuchtung Schalter EIN-AUS-Schaltalgorithmus der allgemeinen Schaltersuchbeleuchtung. Im Detail beschrieben im 'Funktionslastenheft Dimmung MQB'.
            signal KL_SMod_SIH_Stufe_LED_hl_XIX_SMod_SRHe_01_XIX_Klima_LIN4: start 16, 3 bit, little-endian, data-type-policy=OVERRIDE, i-signal-type=PRIMITIVE, init-value=0, base-type=BT_KL_SMod_SIH_Stufe_LED_hl, compu {0=Cx0_Aus (CM_KL_SMod_SIH_Stufe_LED_hl_Cx0_Aus), 1=Cx1_Stufe_1 (CM_KL_SMod_SIH_Stufe_LED_hl_Cx1_Stufe_1), 2=Cx2_Stufe_2 (CM_KL_SMod_SIH_Stufe_LED_hl_Cx2_Stufe_2), 3=Cx3_Stufe_3 (CM_KL_SMod_SIH_Stufe_LED_hl_Cx3_Stufe_3), 4=Cx4_Stufe_4 (CM_KL_SMod_SIH_Stufe_LED_hl_Cx4_Stufe_4), 5=Cx5_Stufe_5 (CM_KL_SMod_SIH_Stufe_LED_hl_Cx5_Stufe_5), 6=Cx6_Stufe_6 (CM_KL_SMod_SIH_Stufe_LED_hl_Cx6_Stufe_6)}, range raw 0..6, transfer-property=PENDING  # Statusmeldung Sitzheizung hinten links durch Klima.
            signal KL_SMod_SIH_Stufe_LED_hr_XIX_SMod_SRHe_01_XIX_Klima_LIN4: start 19, 3 bit, little-endian, data-type-policy=OVERRIDE, i-signal-type=PRIMITIVE, init-value=0, base-type=BT_KL_SMod_SIH_Stufe_LED_hr, compu {0=Cx0_Aus (CM_KL_SMod_SIH_Stufe_LED_hr_Cx0_Aus), 1=Cx1_Stufe_1 (CM_KL_SMod_SIH_Stufe_LED_hr_Cx1_Stufe_1), 2=Cx2_Stufe_2 (CM_KL_SMod_SIH_Stufe_LED_hr_Cx2_Stufe_2), 3=Cx3_Stufe_3 (CM_KL_SMod_SIH_Stufe_LED_hr_Cx3_Stufe_3), 4=Cx4_Stufe_4 (CM_KL_SMod_SIH_Stufe_LED_hr_Cx4_Stufe_4), 5=Cx5_Stufe_5 (CM_KL_SMod_SIH_Stufe_LED_hr_Cx5_Stufe_5), 6=Cx6_Stufe_6 (CM_KL_SMod_SIH_Stufe_LED_hr_Cx6_Stufe_6)}, range raw 0..6, transfer-property=PENDING  # Statusmeldung Sitzheizung hinten rechts durch Klima.
            signal ZAS_Kl_S_XIX_SMod_SRHe_01_XIX_Klima_LIN4: start 22, 1 bit, little-endian, data-type-policy=OVERRIDE, i-signal-type=PRIMITIVE, init-value=0, base-type=BT_ZAS_Kl_S, compu {0=Cx0_aus (CM_ZAS_Kl_S_Cx0_aus), 1=Cx1_S_Kontakt_ein (CM_ZAS_Kl_S_Cx1_S_Kontakt_ein)}, range raw 0..1, transfer-property=PENDING  # Klemme S: S-Kontakt (Schluessel steckt)
            signal ZAS_Kl_15_XIX_SMod_SRHe_01_XIX_Klima_LIN4: start 23, 1 bit, little-endian, data-type-policy=OVERRIDE, i-signal-type=PRIMITIVE, init-value=0, base-type=BT_ZAS_Kl_15, compu {0=Cx0_aus (CM_ZAS_Kl_15_Cx0_aus), 1=Cx1_ein (CM_ZAS_Kl_15_Cx1_ein)}, range raw 0..1, transfer-property=PENDING  # Klemme 15: Zuendung (SW-Kl.15)
            signal KL_SMod_SIL_Stufe_LED_hl_XIX_SMod_SRHe_01_XIX_Klima_LIN4: start 24, 3 bit, little-endian, data-type-policy=OVERRIDE, i-signal-type=PRIMITIVE, init-value=0, base-type=BT_KL_SMod_SIL_Stufe_LED_hl, compu {0=Cx0_Aus (CM_KL_SMod_SIL_Stufe_LED_hl_Cx0_Aus), 1=Cx1_Stufe_1 (CM_KL_SMod_SIL_Stufe_LED_hl_Cx1_Stufe_1), 2=Cx2_Stufe_2 (CM_KL_SMod_SIL_Stufe_LED_hl_Cx2_Stufe_2), 3=Cx3_Stufe_3 (CM_KL_SMod_SIL_Stufe_LED_hl_Cx3_Stufe_3), 4=Cx4_Stufe_4 (CM_KL_SMod_SIL_Stufe_LED_hl_Cx4_Stufe_4), 5=Cx5_Stufe_5 (CM_KL_SMod_SIL_Stufe_LED_hl_Cx5_Stufe_5), 6=Cx6_Stufe_6 (CM_KL_SMod_SIL_Stufe_LED_hl_Cx6_Stufe_6)}, range raw 0..6, transfer-property=PENDING  # Statusmeldung Sitzlüftung hinten links durch KlimaBT.
            signal KL_SMod_SIL_Stufe_LED_hr_XIX_SMod_SRHe_01_XIX_Klima_LIN4: start 27, 3 bit, little-endian, data-type-policy=OVERRIDE, i-signal-type=PRIMITIVE, init-value=0, base-type=BT_KL_SMod_SIL_Stufe_LED_hr, compu {0=Cx0_Aus (CM_KL_SMod_SIL_Stufe_LED_hr_Cx0_Aus), 1=Cx1_Stufe_1 (CM_KL_SMod_SIL_Stufe_LED_hr_Cx1_Stufe_1), 2=Cx2_Stufe_2 (CM_KL_SMod_SIL_Stufe_LED_hr_Cx2_Stufe_2), 3=Cx3_Stufe_3 (CM_KL_SMod_SIL_Stufe_LED_hr_Cx3_Stufe_3), 4=Cx4_Stufe_4 (CM_KL_SMod_SIL_Stufe_LED_hr_Cx4_Stufe_4), 5=Cx5_Stufe_5 (CM_KL_SMod_SIL_Stufe_LED_hr_Cx5_Stufe_5), 6=Cx6_Stufe_6 (CM_KL_SMod_SIL_Stufe_LED_hr_Cx6_Stufe_6)}, range raw 0..6, transfer-property=PENDING  # Statusmeldung Sitzlüftung hinten rechts durch KlimaBT.
            signal SI_T_Mode_XIX_SMod_SRHe_01_XIX_Klima_LIN4: start 30, 1 bit, little-endian, data-type-policy=OVERRIDE, i-signal-type=PRIMITIVE, init-value=0, base-type=BT_SI_T_Mode, compu {0=Cx0_Transportmodus_nicht_aktiv (CM_SI_T_Mode_Cx0_Transportmodus_nicht_aktiv), 1=Cx1_Transportmodus_aktiv (CM_SI_T_Mode_Cx1_Transportmodus_aktiv)}, range raw 0..1, transfer-property=PENDING  # 0x0: Transportmodus nicht aktiv 0x1: Transportmodus aktiv
            signal SI_T_Schutz_XIX_SMod_SRHe_01_XIX_Klima_LIN4: start 31, 1 bit, little-endian, data-type-policy=OVERRIDE, i-signal-type=PRIMITIVE, init-value=0, base-type=BT_SI_T_Schutz, compu {0=Cx0_Transportschutz_nicht_aktiv (CM_SI_T_Schutz_Cx0_Transportschutz_nicht_aktiv), 1=Cx1_Transportschutz_aktiv (CM_SI_T_Schutz_Cx1_Transportschutz_aktiv)}, range raw 0..1, transfer-property=PENDING  # Transportschutz-Signal, das bei Transportmodus und Motorlauf aktiv bleibt 0x0: Transportschutz nicht aktiv 0x1: Transportschutz aktiv
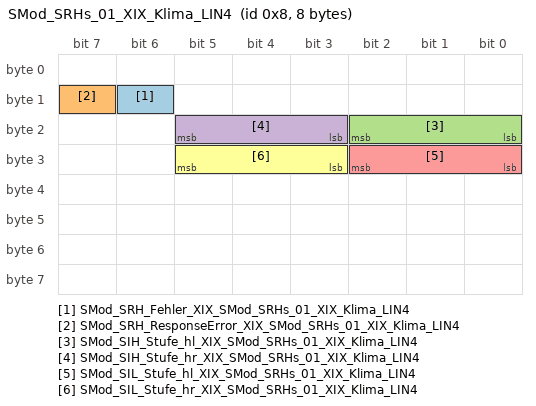
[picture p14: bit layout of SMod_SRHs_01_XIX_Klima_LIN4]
        frame SMod_SRHs_01_XIX_Klima_LIN4: id 0x8, to Klima, frame-length=8, lin-checksum=ENHANCED
          pdu SMod_SRHs_01_XIX_Klima_LIN4: length=8, unused-bit-pattern=0
            signal SMod_SRH_Fehler_XIX_SMod_SRHs_01_XIX_Klima_LIN4: start 14, 1 bit, little-endian, data-type-policy=OVERRIDE, i-signal-type=PRIMITIVE, init-value=0, base-type=BT_SMod_SRH_Fehler, invalid-value=Invalid_SMod_SRH_Fehler_XIX_SMod_SRHs_01_XIX_Klima_LIN4:1, compu {0=Cx0_Normal (CM_SMod_SRH_Fehler_Cx0_Normal), 1=Cx1_Fehler (CM_SMod_SRH_Fehler_Cx1_Fehler)}, range raw 0..1, transfer-property=PENDING, to Klima(timeout 3.5 s)  # Fehlerhandling des SMod_SRH
            signal SMod_SRH_ResponseError_XIX_SMod_SRHs_01_XIX_Klima_LIN4: start 15, 1 bit, little-endian, data-type-policy=OVERRIDE, i-signal-type=PRIMITIVE, init-value=0, base-type=BT_SMod_SRH_ResponseError, invalid-value=Invalid_SMod_SRH_ResponseError_XIX_SMod_SRHs_01_XIX_Klima_LIN4:1, compu {0=Cx0_normal (CM_SMod_SRH_ResponseError_Cx0_normal), 1=Cx1_Fehler (CM_SMod_SRH_ResponseError_Cx1_Fehler)}, range raw 0..1, transfer-property=PENDING, to Klima(timeout 3.5 s)  # siehe LIN2.0-Spezifikation (Darf nicht über ein Fehlergueltigkeitsbit abgesichert werden!)
            signal SMod_SIH_Stufe_hl_XIX_SMod_SRHs_01_XIX_Klima_LIN4: start 16, 3 bit, little-endian, data-type-policy=OVERRIDE, i-signal-type=PRIMITIVE, init-value=0, base-type=BT_SMod_SIH_Stufe_hl, compu {0=Cx0_Stufe_0 (CM_SMod_SIH_Stufe_hl_Cx0_Stufe_0), 1=Cx1_Stufe_1 (CM_SMod_SIH_Stufe_hl_Cx1_Stufe_1), 2=Cx2_Stufe_2 (CM_SMod_SIH_Stufe_hl_Cx2_Stufe_2), 3=Cx3_Stufe_3 (CM_SMod_SIH_Stufe_hl_Cx3_Stufe_3), 4=Cx4_Stufe_4 (CM_SMod_SIH_Stufe_hl_Cx4_Stufe_4), 5=Cx5_Stufe_5 (CM_SMod_SIH_Stufe_hl_Cx5_Stufe_5), 6=Cx6_Stufe_6 (CM_SMod_SIH_Stufe_hl_Cx6_Stufe_6)}, range raw 0..6, transfer-property=PENDING, to Klima(timeout 3.5 s)  # Einstellung Sitzheizung hinten links (0...6)
            signal SMod_SIH_Stufe_hr_XIX_SMod_SRHs_01_XIX_Klima_LIN4: start 19, 3 bit, little-endian, data-type-policy=OVERRIDE, i-signal-type=PRIMITIVE, init-value=0, base-type=BT_SMod_SIH_Stufe_hr, compu {0=Cx0_Stufe_0 (CM_SMod_SIH_Stufe_hr_Cx0_Stufe_0), 1=Cx1_Stufe_1 (CM_SMod_SIH_Stufe_hr_Cx1_Stufe_1), 2=Cx2_Stufe_2 (CM_SMod_SIH_Stufe_hr_Cx2_Stufe_2), 3=Cx3_Stufe_3 (CM_SMod_SIH_Stufe_hr_Cx3_Stufe_3), 4=Cx4_Stufe_4 (CM_SMod_SIH_Stufe_hr_Cx4_Stufe_4), 5=Cx5_Stufe_5 (CM_SMod_SIH_Stufe_hr_Cx5_Stufe_5), 6=Cx6_Stufe_6 (CM_SMod_SIH_Stufe_hr_Cx6_Stufe_6)}, range raw 0..6, transfer-property=PENDING, to Klima(timeout 3.5 s)  # Einstellung Sitzheizung hinten rechts (0...6)
            signal SMod_SIL_Stufe_hl_XIX_SMod_SRHs_01_XIX_Klima_LIN4: start 24, 3 bit, little-endian, data-type-policy=OVERRIDE, i-signal-type=PRIMITIVE, init-value=0, base-type=BT_SMod_SIL_Stufe_hl, compu {0=Cx0_Stufe_0 (CM_SMod_SIL_Stufe_hl_Cx0_Stufe_0), 1=Cx1_Stufe_1 (CM_SMod_SIL_Stufe_hl_Cx1_Stufe_1), 2=Cx2_Stufe_2 (CM_SMod_SIL_Stufe_hl_Cx2_Stufe_2), 3=Cx3_Stufe_3 (CM_SMod_SIL_Stufe_hl_Cx3_Stufe_3), 4=Cx4_Stufe_4 (CM_SMod_SIL_Stufe_hl_Cx4_Stufe_4), 5=Cx5_Stufe_5 (CM_SMod_SIL_Stufe_hl_Cx5_Stufe_5), 6=Cx6_Stufe_6 (CM_SMod_SIL_Stufe_hl_Cx6_Stufe_6)}, range raw 0..6, transfer-property=PENDING, to Klima(timeout 3.5 s)  # Einstellung Sitzlüftung hinten links (0...6)
            signal SMod_SIL_Stufe_hr_XIX_SMod_SRHs_01_XIX_Klima_LIN4: start 27, 3 bit, little-endian, data-type-policy=OVERRIDE, i-signal-type=PRIMITIVE, init-value=0, base-type=BT_SMod_SIL_Stufe_hr, compu {0=Cx0_Stufe_0 (CM_SMod_SIL_Stufe_hr_Cx0_Stufe_0), 1=Cx1_Stufe_1 (CM_SMod_SIL_Stufe_hr_Cx1_Stufe_1), 2=Cx2_Stufe_2 (CM_SMod_SIL_Stufe_hr_Cx2_Stufe_2), 3=Cx3_Stufe_3 (CM_SMod_SIL_Stufe_hr_Cx3_Stufe_3), 4=Cx4_Stufe_4 (CM_SMod_SIL_Stufe_hr_Cx4_Stufe_4), 5=Cx5_Stufe_5 (CM_SMod_SIL_Stufe_hr_Cx5_Stufe_5), 6=Cx6_Stufe_6 (CM_SMod_SIL_Stufe_hr_Cx6_Stufe_6)}, range raw 0..6, transfer-property=PENDING, to Klima(timeout 3.5 s)  # Einstellung Sitzlüftung hinten rechts (0...6)
        pdu triggering PT_Klima_LIN4_XIX_TPCHType_LIN_Diagnose_XIX_0x0_XIX_0x15_XIX_Physical: pdu=DCM_Klima_LIN4_XIX_TPCHType_LIN_Diagnose_XIX_0x0_XIX_0x15_XIX_Physical, from Klima
        pdu triggering PT_Klima_LIN4_XIX_TPCHType_LIN_Diagnose_XIX_0x0_XIX_0x17_XIX_Physical: pdu=DCM_Klima_LIN4_XIX_TPCHType_LIN_Diagnose_XIX_0x0_XIX_0x17_XIX_Physical, from Klima
        pdu triggering PT_Klima_LIN4_XIX_TPCHType_LIN_Diagnose_XIX_0x0_XIX_0x4E_XIX_Physical: pdu=DCM_Klima_LIN4_XIX_TPCHType_LIN_Diagnose_XIX_0x0_XIX_0x4E_XIX_Physical, from Klima
        pdu triggering PT_Klima_LIN4_XIX_TPCHType_LIN_Diagnose_XIX_0x0_XIX_0x50_XIX_Physical: pdu=DCM_Klima_LIN4_XIX_TPCHType_LIN_Diagnose_XIX_0x0_XIX_0x50_XIX_Physical, from Klima
        pdu triggering PT_Klima_LIN4_XIX_TPCHType_LIN_Diagnose_XIX_0x0_XIX_0xD_XIX_Physical: pdu=DCM_Klima_LIN4_XIX_TPCHType_LIN_Diagnose_XIX_0x0_XIX_0xD_XIX_Physical, from Klima
        pdu triggering PT_Klima_LIN4_XIX_TPCHType_LIN_Diagnose_XIX_0x0_XIX_0xF_XIX_Physical: pdu=DCM_Klima_LIN4_XIX_TPCHType_LIN_Diagnose_XIX_0x0_XIX_0xF_XIX_Physical, from Klima
        pdu triggering PT_Klima_LIN4_XIX_TPCHType_LIN_Diagnose_XIX_0x15_XIX_0x0_XIX_Physical: pdu=DCM_Klima_LIN4_XIX_TPCHType_LIN_Diagnose_XIX_0x15_XIX_0x0_XIX_Physical, to Klima
        pdu triggering PT_Klima_LIN4_XIX_TPCHType_LIN_Diagnose_XIX_0x17_XIX_0x0_XIX_Physical: pdu=DCM_Klima_LIN4_XIX_TPCHType_LIN_Diagnose_XIX_0x17_XIX_0x0_XIX_Physical, to Klima
        pdu triggering PT_Klima_LIN4_XIX_TPCHType_LIN_Diagnose_XIX_0x4E_XIX_0x0_XIX_Physical: pdu=DCM_Klima_LIN4_XIX_TPCHType_LIN_Diagnose_XIX_0x4E_XIX_0x0_XIX_Physical, to Klima
        pdu triggering PT_Klima_LIN4_XIX_TPCHType_LIN_Diagnose_XIX_0x50_XIX_0x0_XIX_Physical: pdu=DCM_Klima_LIN4_XIX_TPCHType_LIN_Diagnose_XIX_0x50_XIX_0x0_XIX_Physical, to Klima
        pdu triggering PT_Klima_LIN4_XIX_TPCHType_LIN_Diagnose_XIX_0xD_XIX_0x0_XIX_Physical: pdu=DCM_Klima_LIN4_XIX_TPCHType_LIN_Diagnose_XIX_0xD_XIX_0x0_XIX_Physical, to Klima
        pdu triggering PT_Klima_LIN4_XIX_TPCHType_LIN_Diagnose_XIX_0xF_XIX_0x0_XIX_Physical: pdu=DCM_Klima_LIN4_XIX_TPCHType_LIN_Diagnose_XIX_0xF_XIX_0x0_XIX_Physical, to Klima
        5 x lin schedule table, all with resume-position=CONTINUE-AT-IT-POSITION:
          DiagRequest: run-mode=RUN-ONCE, application-entry{delay=0.01, position-in-table=0, frame-triggering=CHNL/FT_MasterReq}
          DiagResponse: run-mode=RUN-ONCE, application-entry{delay=0.01, position-in-table=0, frame-triggering=CHNL/FT_SlaveResp}
          st_main_1: run-mode=RUN-CONTINUOUS
            table-entrys:
              delay=0.01, position-in-table=0, frame-triggering=CHNL/FT_KLhe_01
              delay=0.02, position-in-table=1, frame-triggering=CHNL/FT_KLhe_02
              delay=0.01, position-in-table=2, frame-triggering=FT_FRSe_01
              delay=0.01, position-in-table=3, frame-triggering=CHNL/FT_KLhs_01
              delay=0.03, position-in-table=4, frame-triggering=CHNL/FT_KLhs_02
              delay=0.01, position-in-table=5, frame-triggering=CHNL/FT_KLhe_01
              delay=0.03, position-in-table=6, frame-triggering=CHNL/FT_KLhe_02
              delay=0.01, position-in-table=7, frame-triggering=CHNL/FT_KLhs_01
              delay=0.03, position-in-table=8, frame-triggering=CHNL/FT_KLhs_02
              delay=0.01, position-in-table=9, frame-triggering=CHNL/FT_KLhe_01
              delay=0.02, position-in-table=10, frame-triggering=CHNL/FT_KLhe_02
              delay=0.01, position-in-table=11, frame-triggering=FT_FRSs_01
              delay=0.01, position-in-table=12, frame-triggering=CHNL/FT_KLhs_01
              delay=0.03, position-in-table=13, frame-triggering=CHNL/FT_KLhs_02
          st_main_2: run-mode=RUN-CONTINUOUS
            table-entrys:
              delay=0.01, position-in-table=0, frame-triggering=CHNL/FT_LHR_0102e_01
              delay=0.01, position-in-table=1, frame-triggering=CHNL/FT_KLhe_01
              delay=0.01, position-in-table=2, frame-triggering=CHNL/FT_KLhe_02
              delay=0.01, position-in-table=3, frame-triggering=FT_FRSe_01
              delay=0.01, position-in-table=4, frame-triggering=FT_HV_Hbe_01
              delay=0.01, position-in-table=5, frame-triggering=CHNL/FT_KLhs_01
              delay=0.02, position-in-table=6, frame-triggering=CHNL/FT_KLhs_02
              delay=0.01, position-in-table=7, frame-triggering=FT_HV_Hbs_01
              delay=0.01, position-in-table=8, frame-triggering=CHNL/FT_KLhe_01
              delay=0.01, position-in-table=9, frame-triggering=CHNL/FT_KLhe_02
              delay=0.01, position-in-table=10, frame-triggering=FT_HV_Hbs_02
              delay=0.01, position-in-table=11, frame-triggering=CHNL/FT_LHR_01s_01
              delay=0.01, position-in-table=12, frame-triggering=CHNL/FT_KLhs_01
              delay=0.02, position-in-table=13, frame-triggering=CHNL/FT_KLhs_02
              delay=0.01, position-in-table=14, frame-triggering=FT_HV_Hbe_01
              delay=0.01, position-in-table=15, frame-triggering=CHNL/FT_KLhe_01
              delay=0.01, position-in-table=16, frame-triggering=CHNL/FT_KLhe_02
              delay=0.01, position-in-table=17, frame-triggering=FT_FRSs_01
              delay=0.01, position-in-table=18, frame-triggering=FT_HV_Hbs_01
              delay=0.01, position-in-table=19, frame-triggering=CHNL/FT_KLhs_01
              delay=0.01, position-in-table=20, frame-triggering=CHNL/FT_KLhs_02
              delay=0.01, position-in-table=21, frame-triggering=FT_HV_Hbs_02
          st_main_3: run-mode=RUN-CONTINUOUS
            table-entrys:
              delay=0.01, position-in-table=0, frame-triggering=CHNL/FT_LLRe_L_01
              delay=0.01, position-in-table=1, frame-triggering=CHNL/FT_LHR_0102e_01
              delay=0.01, position-in-table=2, frame-triggering=CHNL/FT_KLhe_01
              delay=0.01, position-in-table=3, frame-triggering=CHNL/FT_KLhe_02
              delay=0.01, position-in-table=4, frame-triggering=CHNL/FT_LLRs_LL_01
              delay=0.01, position-in-table=5, frame-triggering=FT_FRSe_01
              delay=0.01, position-in-table=6, frame-triggering=CHNL/FT_KLhs_01
              delay=0.01, position-in-table=7, frame-triggering=CHNL/FT_KLhs_02
              delay=0.01, position-in-table=8, frame-triggering=CHNL/FT_LLRs_LS_01
              delay=0.01, position-in-table=9, frame-triggering=FT_SMod_SRHe_01
              delay=0.01, position-in-table=10, frame-triggering=CHNL/FT_KLhe_01
              delay=0.01, position-in-table=11, frame-triggering=CHNL/FT_KLhe_02
              delay=0.01, position-in-table=12, frame-triggering=CHNL/FT_LLRe_R_01
              delay=0.01, position-in-table=13, frame-triggering=CHNL/FT_LHR_01s_01
              delay=0.01, position-in-table=14, frame-triggering=CHNL/FT_KLhs_01
              delay=0.01, position-in-table=15, frame-triggering=CHNL/FT_KLhs_02
              delay=0.01, position-in-table=16, frame-triggering=CHNL/FT_LLRs_RL_01
              delay=0.01, position-in-table=17, frame-triggering=FT_FRSs_01
              delay=0.01, position-in-table=18, frame-triggering=CHNL/FT_KLhe_01
              delay=0.01, position-in-table=19, frame-triggering=CHNL/FT_KLhe_02
              delay=0.01, position-in-table=20, frame-triggering=CHNL/FT_LLRs_RS_01
              delay=0.01, position-in-table=21, frame-triggering=FT_SMod_SRHs_01
              delay=0.01, position-in-table=22, frame-triggering=CHNL/FT_KLhs_01
              delay=0.01, position-in-table=23, frame-triggering=CHNL/FT_KLhs_02
